[part 2 of 11: package /CANAnalyzer/CommunicationClusters]
AUTOSAR XML (schema 00051)
package /CANAnalyzer/CommunicationClusters  (continued)
  can cluster CAN_FD_IPB_41  (continued)
    can physical channel Channel  (continued)
      frame LocalizationInitFBD_Trunk: id 0x229, frame-length=48, can-addressing-mode=STANDARD, can-frame-rx-behavior=CAN-FD, can-frame-tx-behavior=CAN-FD
        pdu LocalizationInitFBD_Trunk: length=48, unused-bit-pattern=0
          signal LocalizationInitFBD_Trunk_IRKListIndex: start 0, 8 bit, little-endian, data-type-policy=OVERRIDE, base-type=uint8, compu {phys=raw}, range phys 0..252
          signal LocalizationInitFBD_Trunk_ZoneEntry: start 8, 8 bit, little-endian, data-type-policy=OVERRIDE, base-type=uint8, compu {phys=raw}, range phys 0..252
          signal LocalizationInitFBD_Trunk_RangingBlockIndex_0: start 16, 16 bit, little-endian, data-type-policy=OVERRIDE, base-type=uint16, compu {phys=raw}, range phys 0..65532
          signal LocalizationInitFBD_Trunk_TimeOfFlight_0: start 32, 16 bit, little-endian, data-type-policy=OVERRIDE, base-type=uint16, compu {phys=raw*15.65; unit ps}, range phys 0..1000000
          signal LocalizationInitFBD_Trunk_RSSI_0: start 48, 8 bit, little-endian, data-type-policy=OVERRIDE, base-type=uint8, compu {phys=raw-90; unit °}, range phys -90..90
          signal LocalizationInitFBD_Trunk_RangingBlockIndex_1: start 56, 16 bit, little-endian, data-type-policy=OVERRIDE, base-type=uint16, compu {phys=raw}, range phys 0..65532
          signal LocalizationInitFBD_Trunk_TimeOfFlight_1: start 72, 16 bit, little-endian, data-type-policy=OVERRIDE, base-type=uint16, compu {phys=raw*15.65; unit ps}, range phys 0..1000000
          signal LocalizationInitFBD_Trunk_RSSI_1: start 88, 8 bit, little-endian, data-type-policy=OVERRIDE, base-type=uint8, compu {phys=raw-90; unit °}, range phys -90..90
          signal LocalizationInitFBD_Trunk_RangingBlockIndex_2: start 96, 16 bit, little-endian, data-type-policy=OVERRIDE, base-type=uint16, compu {phys=raw}, range phys 0..65532
          signal LocalizationInitFBD_Trunk_TimeOfFlight_2: start 112, 16 bit, little-endian, data-type-policy=OVERRIDE, base-type=uint16, compu {phys=raw*15.65; unit ps}, range phys 0..1000000
          signal LocalizationInitFBD_Trunk_RSSI_2: start 128, 8 bit, little-endian, data-type-policy=OVERRIDE, base-type=uint8, compu {phys=raw-90; unit °}, range phys -90..90
          signal LocalizationInitFBD_Trunk_RangingBlockIndex_3: start 136, 16 bit, little-endian, data-type-policy=OVERRIDE, base-type=uint16, compu {phys=raw}, range phys 0..65532
          signal LocalizationInitFBD_Trunk_TimeOfFlight_3: start 152, 16 bit, little-endian, data-type-policy=OVERRIDE, base-type=uint16, compu {phys=raw*15.65; unit ps}, range phys 0..1000000
          signal LocalizationInitFBD_Trunk_RSSI_3: start 168, 8 bit, little-endian, data-type-policy=OVERRIDE, base-type=uint8, compu {phys=raw-90; unit °}, range phys -90..90
          signal LocalizationInitFBD_Trunk_RangingBlockIndex_4: start 176, 16 bit, little-endian, data-type-policy=OVERRIDE, base-type=uint16, compu {phys=raw}, range phys 0..65532
          signal LocalizationInitFBD_Trunk_TimeOfFlight_4: start 192, 16 bit, little-endian, data-type-policy=OVERRIDE, base-type=uint16, compu {phys=raw*15.65; unit ps}, range phys 0..1000000
          signal LocalizationInitFBD_Trunk_RSSI_4: start 208, 8 bit, little-endian, data-type-policy=OVERRIDE, base-type=uint8, compu {phys=raw-90; unit °}, range phys -90..90
          signal LocalizationInitFBD_Trunk_Sign_00: start 216, 8 bit, little-endian, data-type-policy=OVERRIDE, base-type=uint8, compu {phys=raw}, range phys 0..255
          signal LocalizationInitFBD_Trunk_Sign_01: start 224, 8 bit, little-endian, data-type-policy=OVERRIDE, base-type=uint8, compu {phys=raw}, range phys 0..255
          signal LocalizationInitFBD_Trunk_Sign_02: start 232, 8 bit, little-endian, data-type-policy=OVERRIDE, base-type=uint8, compu {phys=raw}, range phys 0..255
          signal LocalizationInitFBD_Trunk_Sign_03: start 240, 8 bit, little-endian, data-type-policy=OVERRIDE, base-type=uint8, compu {phys=raw}, range phys 0..255
          signal LocalizationInitFBD_Trunk_Sign_04: start 248, 8 bit, little-endian, data-type-policy=OVERRIDE, base-type=uint8, compu {phys=raw}, range phys 0..255
          signal LocalizationInitFBD_Trunk_Sign_05: start 256, 8 bit, little-endian, data-type-policy=OVERRIDE, base-type=uint8, compu {phys=raw}, range phys 0..255
          signal LocalizationInitFBD_Trunk_Sign_06: start 264, 8 bit, little-endian, data-type-policy=OVERRIDE, base-type=uint8, compu {phys=raw}, range phys 0..255
          signal LocalizationInitFBD_Trunk_Sign_07: start 272, 8 bit, little-endian, data-type-policy=OVERRIDE, base-type=uint8, compu {phys=raw}, range phys 0..255
          signal LocalizationInitFBD_Trunk_Sign_08: start 280, 8 bit, little-endian, data-type-policy=OVERRIDE, base-type=uint8, compu {phys=raw}, range phys 0..255
          signal LocalizationInitFBD_Trunk_Sign_09: start 288, 8 bit, little-endian, data-type-policy=OVERRIDE, base-type=uint8, compu {phys=raw}, range phys 0..255
          signal LocalizationInitFBD_Trunk_Sign_10: start 296, 8 bit, little-endian, data-type-policy=OVERRIDE, base-type=uint8, compu {phys=raw}, range phys 0..255
          signal LocalizationInitFBD_Trunk_Sign_11: start 304, 8 bit, little-endian, data-type-policy=OVERRIDE, base-type=uint8, compu {phys=raw}, range phys 0..255
          signal LocalizationInitFBD_Trunk_Sign_12: start 312, 8 bit, little-endian, data-type-policy=OVERRIDE, base-type=uint8, compu {phys=raw}, range phys 0..255
          signal LocalizationInitFBD_Trunk_Sign_13: start 320, 8 bit, little-endian, data-type-policy=OVERRIDE, base-type=uint8, compu {phys=raw}, range phys 0..255
          signal LocalizationInitFBD_Trunk_Sign_14: start 328, 8 bit, little-endian, data-type-policy=OVERRIDE, base-type=uint8, compu {phys=raw}, range phys 0..255
          signal LocalizationInitFBD_Trunk_Sign_15: start 336, 8 bit, little-endian, data-type-policy=OVERRIDE, base-type=uint8, compu {phys=raw}, range phys 0..255
          signal LocalizationInitFBD_Trunk_RangingRoundIndex_0: start 344, 8 bit, little-endian, data-type-policy=OVERRIDE, base-type=uint8, compu {phys=raw}, range phys 0..255
          signal LocalizationInitFBD_Trunk_RangingRoundIndex_1: start 352, 8 bit, little-endian, data-type-policy=OVERRIDE, base-type=uint8, compu {phys=raw}, range phys 0..255
          signal LocalizationInitFBD_Trunk_RangingRoundIndex_2: start 360, 8 bit, little-endian, data-type-policy=OVERRIDE, base-type=uint8, compu {phys=raw}, range phys 0..255
          signal LocalizationInitFBD_Trunk_RangingRoundIndex_3: start 368, 8 bit, little-endian, data-type-policy=OVERRIDE, base-type=uint8, compu {phys=raw}, range phys 0..255
          signal LocalizationInitFBD_Trunk_RangingRoundIndex_4: start 376, 8 bit, little-endian, data-type-policy=OVERRIDE, base-type=uint8, compu {phys=raw}, range phys 0..255
      frame LocalizationInitFBD_VL: id 0x22A, frame-length=48, can-addressing-mode=STANDARD, can-frame-rx-behavior=CAN-FD, can-frame-tx-behavior=CAN-FD
        pdu LocalizationInitFBD_VL: length=48, unused-bit-pattern=0
          signal LocalizationInitFBD_VL_IRKListIndex: start 0, 8 bit, little-endian, data-type-policy=OVERRIDE, base-type=uint8, compu {phys=raw}, range phys 0..252
          signal LocalizationInitFBD_VL_ZoneEntry: start 8, 8 bit, little-endian, data-type-policy=OVERRIDE, base-type=uint8, compu {phys=raw}, range phys 0..252
          signal LocalizationInitFBD_VL_RangingBlockIndex_0: start 16, 16 bit, little-endian, data-type-policy=OVERRIDE, base-type=uint16, compu {phys=raw}, range phys 0..65532
          signal LocalizationInitFBD_VL_TimeOfFlight_0: start 32, 16 bit, little-endian, data-type-policy=OVERRIDE, base-type=uint16, compu {phys=raw*15.65; unit ps}, range phys 0..1000000
          signal LocalizationInitFBD_VL_RSSI_0: start 48, 8 bit, little-endian, data-type-policy=OVERRIDE, base-type=uint8, compu {phys=raw-90; unit °}, range phys -90..90
          signal LocalizationInitFBD_VL_RangingBlockIndex_1: start 56, 16 bit, little-endian, data-type-policy=OVERRIDE, base-type=uint16, compu {phys=raw}, range phys 0..65532
          signal LocalizationInitFBD_VL_TimeOfFlight_1: start 72, 16 bit, little-endian, data-type-policy=OVERRIDE, base-type=uint16, compu {phys=raw*15.65; unit ps}, range phys 0..1000000
          signal LocalizationInitFBD_VL_RSSI_1: start 88, 8 bit, little-endian, data-type-policy=OVERRIDE, base-type=uint8, compu {phys=raw-90; unit °}, range phys -90..90
          signal LocalizationInitFBD_VL_RangingBlockIndex_2: start 96, 16 bit, little-endian, data-type-policy=OVERRIDE, base-type=uint16, compu {phys=raw}, range phys 0..65532
          signal LocalizationInitFBD_VL_TimeOfFlight_2: start 112, 16 bit, little-endian, data-type-policy=OVERRIDE, base-type=uint16, compu {phys=raw*15.65; unit ps}, range phys 0..1000000
          signal LocalizationInitFBD_VL_RSSI_2: start 128, 8 bit, little-endian, data-type-policy=OVERRIDE, base-type=uint8, compu {phys=raw-90; unit °}, range phys -90..90
          signal LocalizationInitFBD_VL_RangingBlockIndex_3: start 136, 16 bit, little-endian, data-type-policy=OVERRIDE, base-type=uint16, compu {phys=raw}, range phys 0..65532
          signal LocalizationInitFBD_VL_TimeOfFlight_3: start 152, 16 bit, little-endian, data-type-policy=OVERRIDE, base-type=uint16, compu {phys=raw*15.65; unit ps}, range phys 0..1000000
          signal LocalizationInitFBD_VL_RSSI_3: start 168, 8 bit, little-endian, data-type-policy=OVERRIDE, base-type=uint8, compu {phys=raw-90; unit °}, range phys -90..90
          signal LocalizationInitFBD_VL_RangingBlockIndex_4: start 176, 16 bit, little-endian, data-type-policy=OVERRIDE, base-type=uint16, compu {phys=raw}, range phys 0..65532
          signal LocalizationInitFBD_VL_TimeOfFlight_4: start 192, 16 bit, little-endian, data-type-policy=OVERRIDE, base-type=uint16, compu {phys=raw*15.65; unit ps}, range phys 0..1000000
          signal LocalizationInitFBD_VL_RSSI_4: start 208, 8 bit, little-endian, data-type-policy=OVERRIDE, base-type=uint8, compu {phys=raw-90; unit °}, range phys -90..90
          signal LocalizationInitFBD_VL_Sign_00: start 216, 8 bit, little-endian, data-type-policy=OVERRIDE, base-type=uint8, compu {phys=raw}, range phys 0..255
          signal LocalizationInitFBD_VL_Sign_01: start 224, 8 bit, little-endian, data-type-policy=OVERRIDE, base-type=uint8, compu {phys=raw}, range phys 0..255
          signal LocalizationInitFBD_VL_Sign_02: start 232, 8 bit, little-endian, data-type-policy=OVERRIDE, base-type=uint8, compu {phys=raw}, range phys 0..255
          signal LocalizationInitFBD_VL_Sign_03: start 240, 8 bit, little-endian, data-type-policy=OVERRIDE, base-type=uint8, compu {phys=raw}, range phys 0..255
          signal LocalizationInitFBD_VL_Sign_04: start 248, 8 bit, little-endian, data-type-policy=OVERRIDE, base-type=uint8, compu {phys=raw}, range phys 0..255
          signal LocalizationInitFBD_VL_Sign_05: start 256, 8 bit, little-endian, data-type-policy=OVERRIDE, base-type=uint8, compu {phys=raw}, range phys 0..255
          signal LocalizationInitFBD_VL_Sign_06: start 264, 8 bit, little-endian, data-type-policy=OVERRIDE, base-type=uint8, compu {phys=raw}, range phys 0..255
          signal LocalizationInitFBD_VL_Sign_07: start 272, 8 bit, little-endian, data-type-policy=OVERRIDE, base-type=uint8, compu {phys=raw}, range phys 0..255
          signal LocalizationInitFBD_VL_Sign_08: start 280, 8 bit, little-endian, data-type-policy=OVERRIDE, base-type=uint8, compu {phys=raw}, range phys 0..255
          signal LocalizationInitFBD_VL_Sign_09: start 288, 8 bit, little-endian, data-type-policy=OVERRIDE, base-type=uint8, compu {phys=raw}, range phys 0..255
          signal LocalizationInitFBD_VL_Sign_10: start 296, 8 bit, little-endian, data-type-policy=OVERRIDE, base-type=uint8, compu {phys=raw}, range phys 0..255
          signal LocalizationInitFBD_VL_Sign_11: start 304, 8 bit, little-endian, data-type-policy=OVERRIDE, base-type=uint8, compu {phys=raw}, range phys 0..255
          signal LocalizationInitFBD_VL_Sign_12: start 312, 8 bit, little-endian, data-type-policy=OVERRIDE, base-type=uint8, compu {phys=raw}, range phys 0..255
          signal LocalizationInitFBD_VL_Sign_13: start 320, 8 bit, little-endian, data-type-policy=OVERRIDE, base-type=uint8, compu {phys=raw}, range phys 0..255
          signal LocalizationInitFBD_VL_Sign_14: start 328, 8 bit, little-endian, data-type-policy=OVERRIDE, base-type=uint8, compu {phys=raw}, range phys 0..255
          signal LocalizationInitFBD_VL_Sign_15: start 336, 8 bit, little-endian, data-type-policy=OVERRIDE, base-type=uint8, compu {phys=raw}, range phys 0..255
          signal LocalizationInitFBD_VL_RangingRoundIndex_0: start 344, 8 bit, little-endian, data-type-policy=OVERRIDE, base-type=uint8, compu {phys=raw}, range phys 0..255
          signal LocalizationInitFBD_VL_RangingRoundIndex_1: start 352, 8 bit, little-endian, data-type-policy=OVERRIDE, base-type=uint8, compu {phys=raw}, range phys 0..255
          signal LocalizationInitFBD_VL_RangingRoundIndex_2: start 360, 8 bit, little-endian, data-type-policy=OVERRIDE, base-type=uint8, compu {phys=raw}, range phys 0..255
          signal LocalizationInitFBD_VL_RangingRoundIndex_3: start 368, 8 bit, little-endian, data-type-policy=OVERRIDE, base-type=uint8, compu {phys=raw}, range phys 0..255
          signal LocalizationInitFBD_VL_RangingRoundIndex_4: start 376, 8 bit, little-endian, data-type-policy=OVERRIDE, base-type=uint8, compu {phys=raw}, range phys 0..255
      frame LocalizationInitFBD_VM: id 0x226, frame-length=48, can-addressing-mode=STANDARD, can-frame-rx-behavior=CAN-FD, can-frame-tx-behavior=CAN-FD
        pdu LocalizationInitFBD_VM: length=48, unused-bit-pattern=0
          signal LocalizationInitFBD_VM_IRKListIndex: start 0, 8 bit, little-endian, data-type-policy=OVERRIDE, base-type=uint8, compu {phys=raw}, range phys 0..252
          signal LocalizationInitFBD_VM_ZoneEntry: start 8, 8 bit, little-endian, data-type-policy=OVERRIDE, base-type=uint8, compu {phys=raw}, range phys 0..252
          signal LocalizationInitFBD_VM_RangingBlockIndex_0: start 16, 16 bit, little-endian, data-type-policy=OVERRIDE, base-type=uint16, compu {phys=raw}, range phys 0..65532
          signal LocalizationInitFBD_VM_TimeOfFlight_0: start 32, 16 bit, little-endian, data-type-policy=OVERRIDE, base-type=uint16, compu {phys=raw*15.65; unit ps}, range phys 0..1000000
          signal LocalizationInitFBD_VM_RSSI_0: start 48, 8 bit, little-endian, data-type-policy=OVERRIDE, base-type=uint8, compu {phys=raw-90; unit °}, range phys -90..90
          signal LocalizationInitFBD_VM_RangingBlockIndex_1: start 56, 16 bit, little-endian, data-type-policy=OVERRIDE, base-type=uint16, compu {phys=raw}, range phys 0..65532
          signal LocalizationInitFBD_VM_TimeOfFlight_1: start 72, 16 bit, little-endian, data-type-policy=OVERRIDE, base-type=uint16, compu {phys=raw*15.65; unit ps}, range phys 0..1000000
          signal LocalizationInitFBD_VM_RSSI_1: start 88, 8 bit, little-endian, data-type-policy=OVERRIDE, base-type=uint8, compu {phys=raw-90; unit °}, range phys -90..90
          signal LocalizationInitFBD_VM_RangingBlockIndex_2: start 96, 16 bit, little-endian, data-type-policy=OVERRIDE, base-type=uint16, compu {phys=raw}, range phys 0..65532
          signal LocalizationInitFBD_VM_TimeOfFlight_2: start 112, 16 bit, little-endian, data-type-policy=OVERRIDE, base-type=uint16, compu {phys=raw*15.65; unit ps}, range phys 0..1000000
          signal LocalizationInitFBD_VM_RSSI_2: start 128, 8 bit, little-endian, data-type-policy=OVERRIDE, base-type=uint8, compu {phys=raw-90; unit °}, range phys -90..90
          signal LocalizationInitFBD_VM_RangingBlockIndex_3: start 136, 16 bit, little-endian, data-type-policy=OVERRIDE, base-type=uint16, compu {phys=raw}, range phys 0..65532
          signal LocalizationInitFBD_VM_TimeOfFlight_3: start 152, 16 bit, little-endian, data-type-policy=OVERRIDE, base-type=uint16, compu {phys=raw*15.65; unit ps}, range phys 0..1000000
          signal LocalizationInitFBD_VM_RSSI_3: start 168, 8 bit, little-endian, data-type-policy=OVERRIDE, base-type=uint8, compu {phys=raw-90; unit °}, range phys -90..90
          signal LocalizationInitFBD_VM_RangingBlockIndex_4: start 176, 16 bit, little-endian, data-type-policy=OVERRIDE, base-type=uint16, compu {phys=raw}, range phys 0..65532
          signal LocalizationInitFBD_VM_TimeOfFlight_4: start 192, 16 bit, little-endian, data-type-policy=OVERRIDE, base-type=uint16, compu {phys=raw*15.65; unit ps}, range phys 0..1000000
          signal LocalizationInitFBD_VM_RSSI_4: start 208, 8 bit, little-endian, data-type-policy=OVERRIDE, base-type=uint8, compu {phys=raw-90; unit °}, range phys -90..90
          signal LocalizationInitFBD_VM_Sign_00: start 216, 8 bit, little-endian, data-type-policy=OVERRIDE, base-type=uint8, compu {phys=raw}, range phys 0..255
          signal LocalizationInitFBD_VM_Sign_01: start 224, 8 bit, little-endian, data-type-policy=OVERRIDE, base-type=uint8, compu {phys=raw}, range phys 0..255
          signal LocalizationInitFBD_VM_Sign_02: start 232, 8 bit, little-endian, data-type-policy=OVERRIDE, base-type=uint8, compu {phys=raw}, range phys 0..255
          signal LocalizationInitFBD_VM_Sign_03: start 240, 8 bit, little-endian, data-type-policy=OVERRIDE, base-type=uint8, compu {phys=raw}, range phys 0..255
          signal LocalizationInitFBD_VM_Sign_04: start 248, 8 bit, little-endian, data-type-policy=OVERRIDE, base-type=uint8, compu {phys=raw}, range phys 0..255
          signal LocalizationInitFBD_VM_Sign_05: start 256, 8 bit, little-endian, data-type-policy=OVERRIDE, base-type=uint8, compu {phys=raw}, range phys 0..255
          signal LocalizationInitFBD_VM_Sign_06: start 264, 8 bit, little-endian, data-type-policy=OVERRIDE, base-type=uint8, compu {phys=raw}, range phys 0..255
          signal LocalizationInitFBD_VM_Sign_07: start 272, 8 bit, little-endian, data-type-policy=OVERRIDE, base-type=uint8, compu {phys=raw}, range phys 0..255
          signal LocalizationInitFBD_VM_Sign_08: start 280, 8 bit, little-endian, data-type-policy=OVERRIDE, base-type=uint8, compu {phys=raw}, range phys 0..255
          signal LocalizationInitFBD_VM_Sign_09: start 288, 8 bit, little-endian, data-type-policy=OVERRIDE, base-type=uint8, compu {phys=raw}, range phys 0..255
          signal LocalizationInitFBD_VM_Sign_10: start 296, 8 bit, little-endian, data-type-policy=OVERRIDE, base-type=uint8, compu {phys=raw}, range phys 0..255
          signal LocalizationInitFBD_VM_Sign_11: start 304, 8 bit, little-endian, data-type-policy=OVERRIDE, base-type=uint8, compu {phys=raw}, range phys 0..255
          signal LocalizationInitFBD_VM_Sign_12: start 312, 8 bit, little-endian, data-type-policy=OVERRIDE, base-type=uint8, compu {phys=raw}, range phys 0..255
          signal LocalizationInitFBD_VM_Sign_13: start 320, 8 bit, little-endian, data-type-policy=OVERRIDE, base-type=uint8, compu {phys=raw}, range phys 0..255
          signal LocalizationInitFBD_VM_Sign_14: start 328, 8 bit, little-endian, data-type-policy=OVERRIDE, base-type=uint8, compu {phys=raw}, range phys 0..255
          signal LocalizationInitFBD_VM_Sign_15: start 336, 8 bit, little-endian, data-type-policy=OVERRIDE, base-type=uint8, compu {phys=raw}, range phys 0..255
          signal LocalizationInitFBD_VM_RangingRoundIndex_0: start 344, 8 bit, little-endian, data-type-policy=OVERRIDE, base-type=uint8, compu {phys=raw}, range phys 0..255
          signal LocalizationInitFBD_VM_RangingRoundIndex_1: start 352, 8 bit, little-endian, data-type-policy=OVERRIDE, base-type=uint8, compu {phys=raw}, range phys 0..255
          signal LocalizationInitFBD_VM_RangingRoundIndex_2: start 360, 8 bit, little-endian, data-type-policy=OVERRIDE, base-type=uint8, compu {phys=raw}, range phys 0..255
          signal LocalizationInitFBD_VM_RangingRoundIndex_3: start 368, 8 bit, little-endian, data-type-policy=OVERRIDE, base-type=uint8, compu {phys=raw}, range phys 0..255
          signal LocalizationInitFBD_VM_RangingRoundIndex_4: start 376, 8 bit, little-endian, data-type-policy=OVERRIDE, base-type=uint8, compu {phys=raw}, range phys 0..255
      frame LocalizationInitFBD_VR: id 0x22B, frame-length=48, can-addressing-mode=STANDARD, can-frame-rx-behavior=CAN-FD, can-frame-tx-behavior=CAN-FD
        pdu LocalizationInitFBD_VR: length=48, unused-bit-pattern=0
          signal LocalizationInitFBD_VR_IRKListIndex: start 0, 8 bit, little-endian, data-type-policy=OVERRIDE, base-type=uint8, compu {phys=raw}, range phys 0..252
          signal LocalizationInitFBD_VR_ZoneEntry: start 8, 8 bit, little-endian, data-type-policy=OVERRIDE, base-type=uint8, compu {phys=raw}, range phys 0..252
          signal LocalizationInitFBD_VR_RangingBlockIndex_0: start 16, 16 bit, little-endian, data-type-policy=OVERRIDE, base-type=uint16, compu {phys=raw}, range phys 0..65532
          signal LocalizationInitFBD_VR_TimeOfFlight_0: start 32, 16 bit, little-endian, data-type-policy=OVERRIDE, base-type=uint16, compu {phys=raw*15.65; unit ps}, range phys 0..1000000
          signal LocalizationInitFBD_VR_RSSI_0: start 48, 8 bit, little-endian, data-type-policy=OVERRIDE, base-type=uint8, compu {phys=raw-90; unit °}, range phys -90..90
          signal LocalizationInitFBD_VR_RangingBlockIndex_1: start 56, 16 bit, little-endian, data-type-policy=OVERRIDE, base-type=uint16, compu {phys=raw}, range phys 0..65532
          signal LocalizationInitFBD_VR_TimeOfFlight_1: start 72, 16 bit, little-endian, data-type-policy=OVERRIDE, base-type=uint16, compu {phys=raw*15.65; unit ps}, range phys 0..1000000
          signal LocalizationInitFBD_VR_RSSI_1: start 88, 8 bit, little-endian, data-type-policy=OVERRIDE, base-type=uint8, compu {phys=raw-90; unit °}, range phys -90..90
          signal LocalizationInitFBD_VR_RangingBlockIndex_2: start 96, 16 bit, little-endian, data-type-policy=OVERRIDE, base-type=uint16, compu {phys=raw}, range phys 0..65532
          signal LocalizationInitFBD_VR_TimeOfFlight_2: start 112, 16 bit, little-endian, data-type-policy=OVERRIDE, base-type=uint16, compu {phys=raw*15.65; unit ps}, range phys 0..1000000
          signal LocalizationInitFBD_VR_RSSI_2: start 128, 8 bit, little-endian, data-type-policy=OVERRIDE, base-type=uint8, compu {phys=raw-90; unit °}, range phys -90..90
          signal LocalizationInitFBD_VR_RangingBlockIndex_3: start 136, 16 bit, little-endian, data-type-policy=OVERRIDE, base-type=uint16, compu {phys=raw}, range phys 0..65532
          signal LocalizationInitFBD_VR_TimeOfFlight_3: start 152, 16 bit, little-endian, data-type-policy=OVERRIDE, base-type=uint16, compu {phys=raw*15.65; unit ps}, range phys 0..1000000
          signal LocalizationInitFBD_VR_RSSI_3: start 168, 8 bit, little-endian, data-type-policy=OVERRIDE, base-type=uint8, compu {phys=raw-90; unit °}, range phys -90..90
          signal LocalizationInitFBD_VR_RangingBlockIndex_4: start 176, 16 bit, little-endian, data-type-policy=OVERRIDE, base-type=uint16, compu {phys=raw}, range phys 0..65532
          signal LocalizationInitFBD_VR_TimeOfFlight_4: start 192, 16 bit, little-endian, data-type-policy=OVERRIDE, base-type=uint16, compu {phys=raw*15.65; unit ps}, range phys 0..1000000
          signal LocalizationInitFBD_VR_RSSI_4: start 208, 8 bit, little-endian, data-type-policy=OVERRIDE, base-type=uint8, compu {phys=raw-90; unit °}, range phys -90..90
          signal LocalizationInitFBD_VR_Sign_00: start 216, 8 bit, little-endian, data-type-policy=OVERRIDE, base-type=uint8, compu {phys=raw}, range phys 0..255
          signal LocalizationInitFBD_VR_Sign_01: start 224, 8 bit, little-endian, data-type-policy=OVERRIDE, base-type=uint8, compu {phys=raw}, range phys 0..255
          signal LocalizationInitFBD_VR_Sign_02: start 232, 8 bit, little-endian, data-type-policy=OVERRIDE, base-type=uint8, compu {phys=raw}, range phys 0..255
          signal LocalizationInitFBD_VR_Sign_03: start 240, 8 bit, little-endian, data-type-policy=OVERRIDE, base-type=uint8, compu {phys=raw}, range phys 0..255
          signal LocalizationInitFBD_VR_Sign_04: start 248, 8 bit, little-endian, data-type-policy=OVERRIDE, base-type=uint8, compu {phys=raw}, range phys 0..255
          signal LocalizationInitFBD_VR_Sign_05: start 256, 8 bit, little-endian, data-type-policy=OVERRIDE, base-type=uint8, compu {phys=raw}, range phys 0..255
          signal LocalizationInitFBD_VR_Sign_06: start 264, 8 bit, little-endian, data-type-policy=OVERRIDE, base-type=uint8, compu {phys=raw}, range phys 0..255
          signal LocalizationInitFBD_VR_Sign_07: start 272, 8 bit, little-endian, data-type-policy=OVERRIDE, base-type=uint8, compu {phys=raw}, range phys 0..255
          signal LocalizationInitFBD_VR_Sign_08: start 280, 8 bit, little-endian, data-type-policy=OVERRIDE, base-type=uint8, compu {phys=raw}, range phys 0..255
          signal LocalizationInitFBD_VR_Sign_09: start 288, 8 bit, little-endian, data-type-policy=OVERRIDE, base-type=uint8, compu {phys=raw}, range phys 0..255
          signal LocalizationInitFBD_VR_Sign_10: start 296, 8 bit, little-endian, data-type-policy=OVERRIDE, base-type=uint8, compu {phys=raw}, range phys 0..255
          signal LocalizationInitFBD_VR_Sign_11: start 304, 8 bit, little-endian, data-type-policy=OVERRIDE, base-type=uint8, compu {phys=raw}, range phys 0..255
          signal LocalizationInitFBD_VR_Sign_12: start 312, 8 bit, little-endian, data-type-policy=OVERRIDE, base-type=uint8, compu {phys=raw}, range phys 0..255
          signal LocalizationInitFBD_VR_Sign_13: start 320, 8 bit, little-endian, data-type-policy=OVERRIDE, base-type=uint8, compu {phys=raw}, range phys 0..255
          signal LocalizationInitFBD_VR_Sign_14: start 328, 8 bit, little-endian, data-type-policy=OVERRIDE, base-type=uint8, compu {phys=raw}, range phys 0..255
          signal LocalizationInitFBD_VR_Sign_15: start 336, 8 bit, little-endian, data-type-policy=OVERRIDE, base-type=uint8, compu {phys=raw}, range phys 0..255
          signal LocalizationInitFBD_VR_RangingRoundIndex_0: start 344, 8 bit, little-endian, data-type-policy=OVERRIDE, base-type=uint8, compu {phys=raw}, range phys 0..255
          signal LocalizationInitFBD_VR_RangingRoundIndex_1: start 352, 8 bit, little-endian, data-type-policy=OVERRIDE, base-type=uint8, compu {phys=raw}, range phys 0..255
          signal LocalizationInitFBD_VR_RangingRoundIndex_2: start 360, 8 bit, little-endian, data-type-policy=OVERRIDE, base-type=uint8, compu {phys=raw}, range phys 0..255
          signal LocalizationInitFBD_VR_RangingRoundIndex_3: start 368, 8 bit, little-endian, data-type-policy=OVERRIDE, base-type=uint8, compu {phys=raw}, range phys 0..255
          signal LocalizationInitFBD_VR_RangingRoundIndex_4: start 376, 8 bit, little-endian, data-type-policy=OVERRIDE, base-type=uint8, compu {phys=raw}, range phys 0..255
      frame LocalizationInitRequest: id 0x196, frame-length=20, can-addressing-mode=STANDARD, can-frame-rx-behavior=CAN-FD, can-frame-tx-behavior=CAN-FD
        pdu LocalizationInitRequest: length=20, unused-bit-pattern=0
          signal LocalizationInitRequest_Address: start 0, 16 bit, little-endian, data-type-policy=OVERRIDE, compu {phys=raw}
          signal LocalizationInitRequest_SessionIDShort: start 16, 8 bit, little-endian, data-type-policy=OVERRIDE, base-type=uint8, compu {phys=raw}, range phys 0..252
          signal LocalizationInitRequest_IRKListIndex: start 24, 8 bit, little-endian, data-type-policy=OVERRIDE, base-type=uint8, compu {phys=raw}, range phys 0..252
          signal LocalizationInitRequest_Auth00: start 32, 8 bit, little-endian, data-type-policy=OVERRIDE, base-type=uint8, compu {phys=raw}, range phys 0..255
          signal LocalizationInitRequest_Auth01: start 40, 8 bit, little-endian, data-type-policy=OVERRIDE, base-type=uint8, compu {phys=raw}, range phys 0..255
          signal LocalizationInitRequest_Auth02: start 48, 8 bit, little-endian, data-type-policy=OVERRIDE, base-type=uint8, compu {phys=raw}, range phys 0..255
          signal LocalizationInitRequest_Auth03: start 56, 8 bit, little-endian, data-type-policy=OVERRIDE, base-type=uint8, compu {phys=raw}, range phys 0..255
          signal LocalizationInitRequest_Auth04: start 64, 8 bit, little-endian, data-type-policy=OVERRIDE, base-type=uint8, compu {phys=raw}, range phys 0..255
          signal LocalizationInitRequest_Auth05: start 72, 8 bit, little-endian, data-type-policy=OVERRIDE, base-type=uint8, compu {phys=raw}, range phys 0..255
          signal LocalizationInitRequest_Auth06: start 80, 8 bit, little-endian, data-type-policy=OVERRIDE, base-type=uint8, compu {phys=raw}, range phys 0..255
          signal LocalizationInitRequest_Auth07: start 88, 8 bit, little-endian, data-type-policy=OVERRIDE, base-type=uint8, compu {phys=raw}, range phys 0..255
          signal LocalizationInitRequest_Auth08: start 96, 8 bit, little-endian, data-type-policy=OVERRIDE, base-type=uint8, compu {phys=raw}, range phys 0..255
          signal LocalizationInitRequest_Auth09: start 104, 8 bit, little-endian, data-type-policy=OVERRIDE, base-type=uint8, compu {phys=raw}, range phys 0..255
          signal LocalizationInitRequest_Auth10: start 112, 8 bit, little-endian, data-type-policy=OVERRIDE, base-type=uint8, compu {phys=raw}, range phys 0..255
          signal LocalizationInitRequest_Auth11: start 120, 8 bit, little-endian, data-type-policy=OVERRIDE, base-type=uint8, compu {phys=raw}, range phys 0..255
          signal LocalizationInitRequest_Auth12: start 128, 8 bit, little-endian, data-type-policy=OVERRIDE, base-type=uint8, compu {phys=raw}, range phys 0..255
          signal LocalizationInitRequest_Auth13: start 136, 8 bit, little-endian, data-type-policy=OVERRIDE, base-type=uint8, compu {phys=raw}, range phys 0..255
          signal LocalizationInitRequest_Auth14: start 144, 8 bit, little-endian, data-type-policy=OVERRIDE, base-type=uint8, compu {phys=raw}, range phys 0..255
          signal LocalizationInitRequest_Auth15: start 152, 8 bit, little-endian, data-type-policy=OVERRIDE, base-type=uint8, compu {phys=raw}, range phys 0..255
      frame LocalizationResult_IPB: id 0x3E7, frame-length=32, can-addressing-mode=STANDARD, can-frame-rx-behavior=CAN-FD, can-frame-tx-behavior=CAN-FD
        pdu LocalizationResult_IPB: length=32, unused-bit-pattern=0
          signal LocalizationResult_IPB_Byte00: start 0, 8 bit, little-endian, data-type-policy=OVERRIDE, base-type=uint8, compu {phys=raw}, range phys 0..252
          signal LocalizationResult_IPB_Byte01: start 8, 8 bit, little-endian, data-type-policy=OVERRIDE, base-type=uint8, compu {phys=raw}, range phys 0..252
          signal LocalizationResult_IPB_Byte02: start 16, 8 bit, little-endian, data-type-policy=OVERRIDE, base-type=uint8, compu {phys=raw}, range phys 0..252
          signal LocalizationResult_IPB_Byte03: start 24, 8 bit, little-endian, data-type-policy=OVERRIDE, base-type=uint8, compu {phys=raw}, range phys 0..252
          signal LocalizationResult_IPB_Byte04: start 32, 8 bit, little-endian, data-type-policy=OVERRIDE, base-type=uint8, compu {phys=raw}, range phys 0..252
          signal LocalizationResult_IPB_Byte05: start 40, 8 bit, little-endian, data-type-policy=OVERRIDE, base-type=uint8, compu {phys=raw}, range phys 0..252
          signal LocalizationResult_IPB_Byte06: start 48, 8 bit, little-endian, data-type-policy=OVERRIDE, base-type=uint8, compu {phys=raw}, range phys 0..252
          signal LocalizationResult_IPB_Byte07: start 56, 8 bit, little-endian, data-type-policy=OVERRIDE, base-type=uint8, compu {phys=raw}, range phys 0..252
          signal LocalizationResult_IPB_Byte08: start 64, 8 bit, little-endian, data-type-policy=OVERRIDE, base-type=uint8, compu {phys=raw}, range phys 0..252
          signal LocalizationResult_IPB_Byte09: start 72, 8 bit, little-endian, data-type-policy=OVERRIDE, base-type=uint8, compu {phys=raw}, range phys 0..252
          signal LocalizationResult_IPB_Byte10: start 80, 8 bit, little-endian, data-type-policy=OVERRIDE, base-type=uint8, compu {phys=raw}, range phys 0..252
          signal LocalizationResult_IPB_Byte11: start 88, 8 bit, little-endian, data-type-policy=OVERRIDE, base-type=uint8, compu {phys=raw}, range phys 0..252
          signal LocalizationResult_IPB_Byte12: start 96, 8 bit, little-endian, data-type-policy=OVERRIDE, base-type=uint8, compu {phys=raw}, range phys 0..252
          signal LocalizationResult_IPB_Byte13: start 104, 8 bit, little-endian, data-type-policy=OVERRIDE, base-type=uint8, compu {phys=raw}, range phys 0..252
          signal LocalizationResult_IPB_Byte14: start 112, 8 bit, little-endian, data-type-policy=OVERRIDE, base-type=uint8, compu {phys=raw}, range phys 0..252
          signal LocalizationResult_IPB_Byte15: start 120, 8 bit, little-endian, data-type-policy=OVERRIDE, base-type=uint8, compu {phys=raw}, range phys 0..252
          signal LocalizationResult_IPB_Byte16: start 128, 8 bit, little-endian, data-type-policy=OVERRIDE, base-type=uint8, compu {phys=raw}, range phys 0..252
          signal LocalizationResult_IPB_Byte17: start 136, 8 bit, little-endian, data-type-policy=OVERRIDE, base-type=uint8, compu {phys=raw}, range phys 0..252
          signal LocalizationResult_IPB_Byte18: start 144, 8 bit, little-endian, data-type-policy=OVERRIDE, base-type=uint8, compu {phys=raw}, range phys 0..252
          signal LocalizationResult_IPB_Byte19: start 152, 8 bit, little-endian, data-type-policy=OVERRIDE, base-type=uint8, compu {phys=raw}, range phys 0..252
          signal LocalizationResult_IPB_Byte20: start 160, 8 bit, little-endian, data-type-policy=OVERRIDE, base-type=uint8, compu {phys=raw}, range phys 0..252
          signal LocalizationResult_IPB_Byte21: start 168, 8 bit, little-endian, data-type-policy=OVERRIDE, base-type=uint8, compu {phys=raw}, range phys 0..252
          signal LocalizationResult_IPB_Byte22: start 176, 8 bit, little-endian, data-type-policy=OVERRIDE, base-type=uint8, compu {phys=raw}, range phys 0..252
          signal LocalizationResult_IPB_Byte23: start 184, 8 bit, little-endian, data-type-policy=OVERRIDE, base-type=uint8, compu {phys=raw}, range phys 0..252
          signal LocalizationResult_IPB_Byte24: start 192, 8 bit, little-endian, data-type-policy=OVERRIDE, base-type=uint8, compu {phys=raw}, range phys 0..252
          signal LocalizationResult_IPB_Byte25: start 200, 8 bit, little-endian, data-type-policy=OVERRIDE, base-type=uint8, compu {phys=raw}, range phys 0..252
          signal LocalizationResult_IPB_Byte26: start 208, 8 bit, little-endian, data-type-policy=OVERRIDE, base-type=uint8, compu {phys=raw}, range phys 0..252
          signal LocalizationResult_IPB_Byte27: start 216, 8 bit, little-endian, data-type-policy=OVERRIDE, base-type=uint8, compu {phys=raw}, range phys 0..252
          signal LocalizationResult_IPB_Byte28: start 224, 8 bit, little-endian, data-type-policy=OVERRIDE, base-type=uint8, compu {phys=raw}, range phys 0..252
          signal LocalizationResult_IPB_Byte29: start 232, 8 bit, little-endian, data-type-policy=OVERRIDE, base-type=uint8, compu {phys=raw}, range phys 0..252
          signal LocalizationResult_IPB_Byte30: start 240, 8 bit, little-endian, data-type-policy=OVERRIDE, base-type=uint8, compu {phys=raw}, range phys 0..252
          signal LocalizationResult_IPB_Byte31: start 248, 8 bit, little-endian, data-type-policy=OVERRIDE, base-type=uint8, compu {phys=raw}, range phys 0..252
      frame MyWayTracking_IPB: id 0x3E6, frame-length=32, can-addressing-mode=STANDARD, can-frame-rx-behavior=CAN-FD, can-frame-tx-behavior=CAN-FD
        pdu MyWayTracking_IPB: length=32, unused-bit-pattern=0
          signal MyWayTracking_IPB_SessionIDShort: start 0, 8 bit, little-endian, data-type-policy=OVERRIDE, base-type=uint8, compu {phys=raw}, range phys 0..252
          signal MyWayTracking_IPB_IRKListIndex: start 8, 8 bit, little-endian, data-type-policy=OVERRIDE, base-type=uint8, compu {phys=raw}, range phys 0..252
          signal MyWayTracking_IPB_TrackingStatus: start 16, 8 bit, little-endian, data-type-policy=OVERRIDE, base-type=uint8, compu {phys=raw}, range phys 0..252
          signal MyWayTracking_IPB_ClassificationConfidence: start 24, 8 bit, little-endian, data-type-policy=OVERRIDE, base-type=uint8, compu {phys=raw}, range phys 0..252
          signal MyWayTracking_IPB_Intent: start 32, 8 bit, little-endian, data-type-policy=OVERRIDE, base-type=uint8, compu {phys=raw}, range phys 0..252
          signal MyWayTracking_IPB_TimeRemaining: start 40, 8 bit, little-endian, data-type-policy=OVERRIDE, base-type=uint8, compu {phys=raw}, range phys 0..252
          signal MyWayTracking_IPB_Target: start 48, 8 bit, little-endian, data-type-policy=OVERRIDE, base-type=uint8, compu {phys=raw}, range phys 0..252
          signal MyWayTracking_IPB_Parameter00: start 56, 8 bit, little-endian, data-type-policy=OVERRIDE, base-type=uint8, compu {phys=raw}, range phys 0..252
          signal MyWayTracking_IPB_Parameter01: start 64, 8 bit, little-endian, data-type-policy=OVERRIDE, base-type=uint8, compu {phys=raw}, range phys 0..252
          signal MyWayTracking_IPB_Parameter02: start 72, 8 bit, little-endian, data-type-policy=OVERRIDE, base-type=uint8, compu {phys=raw}, range phys 0..252
          signal MyWayTracking_IPB_Parameter03: start 80, 8 bit, little-endian, data-type-policy=OVERRIDE, base-type=uint8, compu {phys=raw}, range phys 0..252
          signal MyWayTracking_IPB_Parameter04: start 88, 8 bit, little-endian, data-type-policy=OVERRIDE, base-type=uint8, compu {phys=raw}, range phys 0..252
          signal MyWayTracking_IPB_Parameter05: start 96, 8 bit, little-endian, data-type-policy=OVERRIDE, base-type=uint8, compu {phys=raw}, range phys 0..252
          signal MyWayTracking_IPB_Parameter06: start 104, 8 bit, little-endian, data-type-policy=OVERRIDE, base-type=uint8, compu {phys=raw}, range phys 0..252
          signal MyWayTracking_IPB_Parameter07: start 112, 8 bit, little-endian, data-type-policy=OVERRIDE, base-type=uint8, compu {phys=raw}, range phys 0..252
          signal MyWayTracking_IPB_Parameter08: start 120, 8 bit, little-endian, data-type-policy=OVERRIDE, base-type=uint8, compu {phys=raw}, range phys 0..252
          signal MyWayTracking_IPB_Parameter09: start 128, 8 bit, little-endian, data-type-policy=OVERRIDE, base-type=uint8, compu {phys=raw}, range phys 0..252
          signal MyWayTracking_IPB_Parameter10: start 136, 8 bit, little-endian, data-type-policy=OVERRIDE, base-type=uint8, compu {phys=raw}, range phys 0..252
          signal MyWayTracking_IPB_Parameter11: start 144, 8 bit, little-endian, data-type-policy=OVERRIDE, base-type=uint8, compu {phys=raw}, range phys 0..252
          signal MyWayTracking_IPB_Parameter12: start 152, 8 bit, little-endian, data-type-policy=OVERRIDE, base-type=uint8, compu {phys=raw}, range phys 0..252
          signal MyWayTracking_IPB_Parameter13: start 160, 8 bit, little-endian, data-type-policy=OVERRIDE, base-type=uint8, compu {phys=raw}, range phys 0..252
          signal MyWayTracking_IPB_Parameter14: start 168, 8 bit, little-endian, data-type-policy=OVERRIDE, base-type=uint8, compu {phys=raw}, range phys 0..252
          signal MyWayTracking_IPB_Parameter15: start 176, 8 bit, little-endian, data-type-policy=OVERRIDE, base-type=uint8, compu {phys=raw}, range phys 0..252
          signal MyWayTracking_IPB_Parameter16: start 184, 8 bit, little-endian, data-type-policy=OVERRIDE, base-type=uint8, compu {phys=raw}, range phys 0..252
          signal MyWayTracking_IPB_Parameter17: start 192, 8 bit, little-endian, data-type-policy=OVERRIDE, base-type=uint8, compu {phys=raw}, range phys 0..252
          signal MyWayTracking_IPB_Parameter18: start 200, 8 bit, little-endian, data-type-policy=OVERRIDE, base-type=uint8, compu {phys=raw}, range phys 0..252
          signal MyWayTracking_IPB_Parameter19: start 208, 8 bit, little-endian, data-type-policy=OVERRIDE, base-type=uint8, compu {phys=raw}, range phys 0..252
          signal MyWayTracking_IPB_Parameter20: start 216, 8 bit, little-endian, data-type-policy=OVERRIDE, base-type=uint8, compu {phys=raw}, range phys 0..252
          signal MyWayTracking_IPB_Parameter21: start 224, 8 bit, little-endian, data-type-policy=OVERRIDE, base-type=uint8, compu {phys=raw}, range phys 0..252
          signal MyWayTracking_IPB_Parameter22: start 232, 8 bit, little-endian, data-type-policy=OVERRIDE, base-type=uint8, compu {phys=raw}, range phys 0..252
          signal MyWayTracking_IPB_Parameter23: start 240, 8 bit, little-endian, data-type-policy=OVERRIDE, base-type=uint8, compu {phys=raw}, range phys 0..252
          signal MyWayTracking_IPB_Parameter24: start 248, 8 bit, little-endian, data-type-policy=OVERRIDE, base-type=uint8, compu {phys=raw}, range phys 0..252
      frame RequestBindingStatusFBD: id 0x25E, frame-length=8, can-addressing-mode=STANDARD, can-frame-rx-behavior=CAN-20, can-frame-tx-behavior=CAN-20
        pdu RequestBindingStatusFBD: length=8, unused-bit-pattern=0
          signal RequestBindingStatusFBD_Address: start 0, 16 bit, little-endian, data-type-policy=OVERRIDE, compu {phys=raw}
          signal RequestBindingStatusFBD_RequestStatus: start 16, 8 bit, little-endian, data-type-policy=OVERRIDE, base-type=uint8, compu {phys=raw}, range phys 0..252
      frame RequestBLECSSession: id 0x180, frame-length=48, can-addressing-mode=STANDARD, can-frame-rx-behavior=CAN-FD, can-frame-tx-behavior=CAN-FD
        pdu RequestBLECSSession: length=48, unused-bit-pattern=0
          signal RequestBLECSSession_Address: start 0, 16 bit, little-endian, data-type-policy=OVERRIDE, compu {phys=raw}
          signal RequestBLECSSession_ID: start 16, 8 bit, little-endian, data-type-policy=OVERRIDE, base-type=uint8, compu {phys=raw}, range phys 0..252
          signal RequestBLECSSession_IRKListID: start 24, 8 bit, little-endian, data-type-policy=OVERRIDE, base-type=uint8, compu {phys=raw}, range phys 0..252
          signal RequestBLECSSession_DeviceGroup: start 32, 8 bit, little-endian, data-type-policy=OVERRIDE, base-type=uint8, compu {phys=raw}, range phys 0..252
          signal RequestBLECSSession_MainModeType: start 40, 8 bit, little-endian, data-type-policy=OVERRIDE, compu {phys=raw}
          signal RequestBLECSSession_SubModeType: start 48, 8 bit, little-endian, data-type-policy=OVERRIDE, compu {phys=raw}
          signal RequestBLECSSession_MainModeRepetition: start 56, 8 bit, little-endian, data-type-policy=OVERRIDE, base-type=uint8, compu {phys=raw}, range phys 0..252
          signal RequestBLECSSession_Mode0Steps: start 64, 8 bit, little-endian, data-type-policy=OVERRIDE, base-type=uint8, compu {phys=raw}, range phys 0..252
          signal RequestBLECSSession_RTTType: start 72, 8 bit, little-endian, data-type-policy=OVERRIDE, compu {phys=raw}
          signal RequestBLECSSession_CSSyncPHY: start 80, 8 bit, little-endian, data-type-policy=OVERRIDE, compu {phys=raw}
          signal RequestBLECSSession_ChannelMap00_59: start 88, 64 bit, little-endian, data-type-policy=OVERRIDE, compu {phys=raw}
          signal RequestBLECSSession_ChannelMap60_79: start 152, 24 bit, little-endian, data-type-policy=OVERRIDE, compu {phys=raw}
          signal RequestBLECSSession_MaxProcedureLen: start 176, 16 bit, little-endian, data-type-policy=OVERRIDE, base-type=uint16, compu {phys=raw*0.625; unit ms}, range phys 0..40900
          signal RequestBLECSSession_MinProcedureIntervals: start 192, 16 bit, little-endian, data-type-policy=OVERRIDE, base-type=uint16, compu {phys=raw*0.625; unit ms}, range phys 0..40900
          signal RequestBLECSSession_MaxProcedureIntervals: start 208, 16 bit, little-endian, data-type-policy=OVERRIDE, base-type=uint16, compu {phys=raw*0.625; unit ms}, range phys 0..40900
          signal RequestBLECSSession_MaxProcedureCount: start 224, 16 bit, little-endian, data-type-policy=OVERRIDE, base-type=uint16, compu {phys=raw}, range phys 0..65532
          signal RequestBLECSSession_ToneAntennaConfigSelection: start 240, 8 bit, little-endian, data-type-policy=OVERRIDE, compu {phys=raw}
          signal RequestBLECSSession_BusCycleTime: start 248, 16 bit, little-endian, data-type-policy=OVERRIDE, base-type=uint16, compu {phys=raw; unit ms}, range phys 0..65532
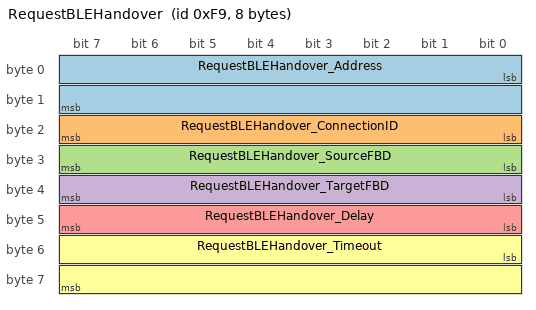
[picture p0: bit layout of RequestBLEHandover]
      frame RequestBLEHandover: id 0xF9, frame-length=8, can-addressing-mode=STANDARD, can-frame-rx-behavior=CAN-20, can-frame-tx-behavior=CAN-20
        pdu RequestBLEHandover: length=8, unused-bit-pattern=0
          signal RequestBLEHandover_Address: start 0, 16 bit, little-endian, data-type-policy=OVERRIDE, compu {phys=raw}
          signal RequestBLEHandover_ConnectionID: start 16, 8 bit, little-endian, data-type-policy=OVERRIDE, base-type=uint8, compu {phys=raw}, range phys 0..252
          signal RequestBLEHandover_SourceFBD: start 24, 8 bit, little-endian, data-type-policy=OVERRIDE, compu {phys=raw}
          signal RequestBLEHandover_TargetFBD: start 32, 8 bit, little-endian, data-type-policy=OVERRIDE, compu {phys=raw}
          signal RequestBLEHandover_Delay: start 40, 8 bit, little-endian, data-type-policy=OVERRIDE, base-type=uint8, compu {phys=raw; unit ms}, range phys 0..252
          signal RequestBLEHandover_Timeout: start 48, 16 bit, little-endian, data-type-policy=OVERRIDE, base-type=uint16, compu {phys=raw; unit ms}, range phys 0..65532
      frame RequestBLESettings: id 0xCB, frame-length=8, can-addressing-mode=STANDARD, can-frame-rx-behavior=CAN-20, can-frame-tx-behavior=CAN-20
        pdu RequestBLESettings: length=8, unused-bit-pattern=0
          signal RequestBLESettings_Address: start 0, 16 bit, little-endian, data-type-policy=OVERRIDE, compu {phys=raw}
          signal RequestBLESettings_RequestSettings: start 16, 8 bit, little-endian, data-type-policy=OVERRIDE, base-type=uint8, compu {phys=raw}, range phys 0..252
      frame RequestConfigurationStatusFBD: id 0x259, frame-length=8, can-addressing-mode=STANDARD, can-frame-rx-behavior=CAN-20, can-frame-tx-behavior=CAN-20
        pdu RequestConfigurationStatusFBD: length=8, unused-bit-pattern=0
          signal RequestConfigurationStatusFBD_Address: start 0, 16 bit, little-endian, data-type-policy=OVERRIDE, compu {phys=raw}
          signal RequestConfigurationStatusFBD_RequestConfiguration: start 16, 8 bit, little-endian, data-type-policy=OVERRIDE, base-type=uint8, compu {phys=raw}, range phys 0..252
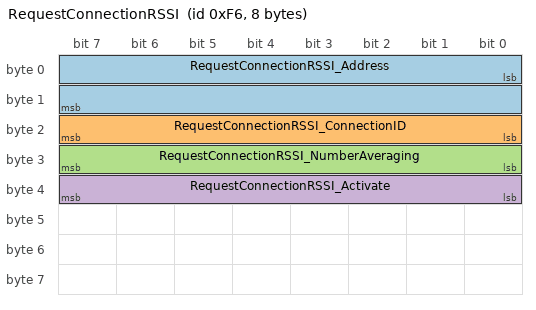
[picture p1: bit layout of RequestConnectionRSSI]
      frame RequestConnectionRSSI: id 0xF6, frame-length=8, can-addressing-mode=STANDARD, can-frame-rx-behavior=CAN-20, can-frame-tx-behavior=CAN-20
        pdu RequestConnectionRSSI: length=8, unused-bit-pattern=0
          signal RequestConnectionRSSI_Address: start 0, 16 bit, little-endian, data-type-policy=OVERRIDE, compu {phys=raw}
          signal RequestConnectionRSSI_ConnectionID: start 16, 8 bit, little-endian, data-type-policy=OVERRIDE, base-type=uint8, compu {phys=raw}, range phys 0..252
          signal RequestConnectionRSSI_NumberAveraging: start 24, 8 bit, little-endian, data-type-policy=OVERRIDE, base-type=uint8, compu {phys=raw}, range phys 0..252
          signal RequestConnectionRSSI_Activate: start 32, 8 bit, little-endian, data-type-policy=OVERRIDE, compu {phys=raw}
      frame RequestCoordinates: id 0x25A, frame-length=8, can-addressing-mode=STANDARD, can-frame-rx-behavior=CAN-20, can-frame-tx-behavior=CAN-20
        pdu RequestCoordinates: length=8, unused-bit-pattern=0
          signal RequestCoordinates_Address: start 0, 16 bit, little-endian, data-type-policy=OVERRIDE, compu {phys=raw}
          signal RequestCoordinates_RequestData: start 16, 8 bit, little-endian, data-type-policy=OVERRIDE, base-type=uint8, compu {phys=raw}, range phys 0..252
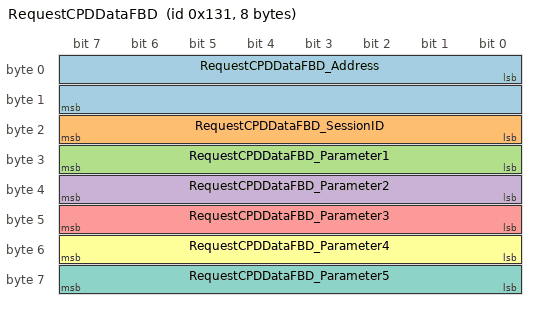
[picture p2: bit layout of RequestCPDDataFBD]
      frame RequestCPDDataFBD: id 0x131, frame-length=8, can-addressing-mode=STANDARD, can-frame-rx-behavior=CAN-20, can-frame-tx-behavior=CAN-20
        pdu RequestCPDDataFBD: length=8, unused-bit-pattern=0
          signal RequestCPDDataFBD_Address: start 0, 16 bit, little-endian, data-type-policy=OVERRIDE, compu {phys=raw}
          signal RequestCPDDataFBD_SessionID: start 16, 8 bit, little-endian, data-type-policy=OVERRIDE, base-type=uint8, compu {phys=raw}, range phys 0..252
          signal RequestCPDDataFBD_Parameter1: start 24, 8 bit, little-endian, data-type-policy=OVERRIDE, base-type=uint8, compu {phys=raw}, range phys 0..252
          signal RequestCPDDataFBD_Parameter2: start 32, 8 bit, little-endian, data-type-policy=OVERRIDE, base-type=uint8, compu {phys=raw}, range phys 0..252
          signal RequestCPDDataFBD_Parameter3: start 40, 8 bit, little-endian, data-type-policy=OVERRIDE, base-type=uint8, compu {phys=raw}, range phys 0..252
          signal RequestCPDDataFBD_Parameter4: start 48, 8 bit, little-endian, data-type-policy=OVERRIDE, base-type=uint8, compu {phys=raw}, range phys 0..252
          signal RequestCPDDataFBD_Parameter5: start 56, 8 bit, little-endian, data-type-policy=OVERRIDE, base-type=uint8, compu {phys=raw}, range phys 0..252
      frame RequestRangingSessionSign: id 0x195, frame-length=12, can-addressing-mode=STANDARD, can-frame-rx-behavior=CAN-FD, can-frame-tx-behavior=CAN-FD
        pdu RequestRangingSessionSign: length=12, unused-bit-pattern=0
          signal RequestRangingSessionSign_Address: start 0, 16 bit, little-endian, data-type-policy=OVERRIDE, compu {phys=raw}
          signal RequestRangingSessionSign_Function: start 16, 8 bit, little-endian, data-type-policy=OVERRIDE, base-type=uint8, compu {phys=raw}, range phys 0..252
          signal RequestRangingSessionSign_IRKListID: start 24, 8 bit, little-endian, data-type-policy=OVERRIDE, base-type=uint8, compu {phys=raw}, range phys 0..252
          signal RequestRangingSessionSign_STSIndex: start 32, 32 bit, little-endian, data-type-policy=OVERRIDE, base-type=uint32, compu {phys=raw}, range phys 0..4294967292
          signal RequestRangingSessionSign_Nonce: start 64, 32 bit, little-endian, data-type-policy=OVERRIDE, base-type=uint32, compu {phys=raw}, range phys 0..4294967294
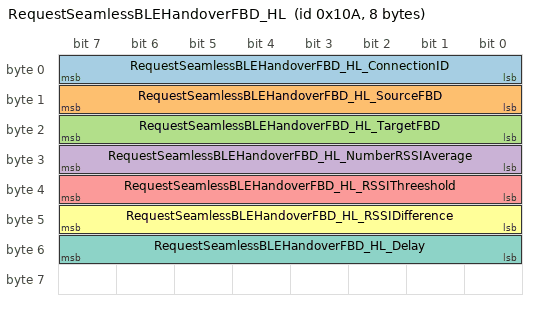
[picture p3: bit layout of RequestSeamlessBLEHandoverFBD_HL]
      frame RequestSeamlessBLEHandoverFBD_HL: id 0x10A, frame-length=8, can-addressing-mode=STANDARD, can-frame-rx-behavior=CAN-20, can-frame-tx-behavior=CAN-20
        pdu RequestSeamlessBLEHandoverFBD_HL: length=8, unused-bit-pattern=0
          signal RequestSeamlessBLEHandoverFBD_HL_ConnectionID: start 0, 8 bit, little-endian, data-type-policy=OVERRIDE, base-type=uint8, compu {phys=raw}, range phys 0..252
          signal RequestSeamlessBLEHandoverFBD_HL_SourceFBD: start 8, 8 bit, little-endian, data-type-policy=OVERRIDE, compu {phys=raw}
          signal RequestSeamlessBLEHandoverFBD_HL_TargetFBD: start 16, 8 bit, little-endian, data-type-policy=OVERRIDE, compu {phys=raw}
          signal RequestSeamlessBLEHandoverFBD_HL_NumberRSSIAverage: start 24, 8 bit, little-endian, data-type-policy=OVERRIDE, base-type=uint8, compu {phys=raw}, range phys 0..252
          signal RequestSeamlessBLEHandoverFBD_HL_RSSIThreeshold: start 32, 8 bit, little-endian, data-type-policy=OVERRIDE, base-type=uint8, compu {phys=raw*0.5-127; unit dB}, range phys -127..-1
          signal RequestSeamlessBLEHandoverFBD_HL_RSSIDifference: start 40, 8 bit, little-endian, data-type-policy=OVERRIDE, base-type=uint8, compu {phys=raw*0.5; unit dB}, range phys 0..126
          signal RequestSeamlessBLEHandoverFBD_HL_Delay: start 48, 8 bit, little-endian, data-type-policy=OVERRIDE, base-type=uint8, compu {phys=raw; unit ms}, range phys 0..252
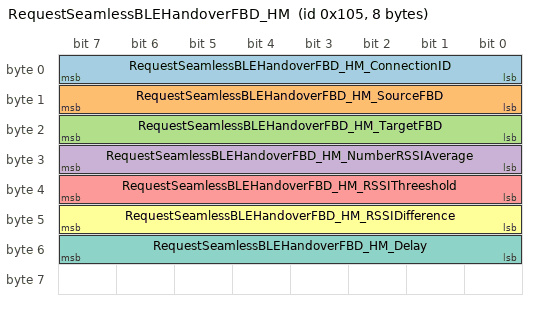
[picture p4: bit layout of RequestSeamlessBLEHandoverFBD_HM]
      frame RequestSeamlessBLEHandoverFBD_HM: id 0x105, frame-length=8, can-addressing-mode=STANDARD, can-frame-rx-behavior=CAN-20, can-frame-tx-behavior=CAN-20
        pdu RequestSeamlessBLEHandoverFBD_HM: length=8, unused-bit-pattern=0
          signal RequestSeamlessBLEHandoverFBD_HM_ConnectionID: start 0, 8 bit, little-endian, data-type-policy=OVERRIDE, base-type=uint8, compu {phys=raw}, range phys 0..252
          signal RequestSeamlessBLEHandoverFBD_HM_SourceFBD: start 8, 8 bit, little-endian, data-type-policy=OVERRIDE, compu {phys=raw}
          signal RequestSeamlessBLEHandoverFBD_HM_TargetFBD: start 16, 8 bit, little-endian, data-type-policy=OVERRIDE, compu {phys=raw}
          signal RequestSeamlessBLEHandoverFBD_HM_NumberRSSIAverage: start 24, 8 bit, little-endian, data-type-policy=OVERRIDE, base-type=uint8, compu {phys=raw}, range phys 0..252
          signal RequestSeamlessBLEHandoverFBD_HM_RSSIThreeshold: start 32, 8 bit, little-endian, data-type-policy=OVERRIDE, base-type=uint8, compu {phys=raw*0.5-127; unit dB}, range phys -127..-1
          signal RequestSeamlessBLEHandoverFBD_HM_RSSIDifference: start 40, 8 bit, little-endian, data-type-policy=OVERRIDE, base-type=uint8, compu {phys=raw*0.5; unit dB}, range phys 0..126
          signal RequestSeamlessBLEHandoverFBD_HM_Delay: start 48, 8 bit, little-endian, data-type-policy=OVERRIDE, base-type=uint8, compu {phys=raw; unit ms}, range phys 0..252
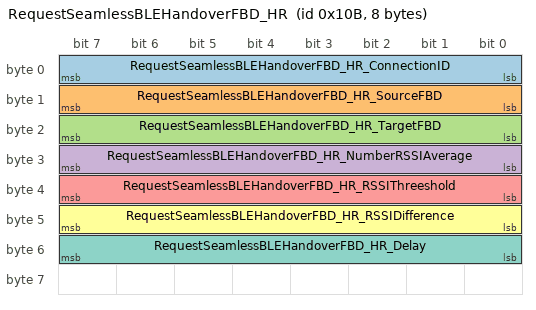
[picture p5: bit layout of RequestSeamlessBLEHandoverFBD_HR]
      frame RequestSeamlessBLEHandoverFBD_HR: id 0x10B, frame-length=8, can-addressing-mode=STANDARD, can-frame-rx-behavior=CAN-20, can-frame-tx-behavior=CAN-20
        pdu RequestSeamlessBLEHandoverFBD_HR: length=8, unused-bit-pattern=0
          signal RequestSeamlessBLEHandoverFBD_HR_ConnectionID: start 0, 8 bit, little-endian, data-type-policy=OVERRIDE, base-type=uint8, compu {phys=raw}, range phys 0..252
          signal RequestSeamlessBLEHandoverFBD_HR_SourceFBD: start 8, 8 bit, little-endian, data-type-policy=OVERRIDE, compu {phys=raw}
          signal RequestSeamlessBLEHandoverFBD_HR_TargetFBD: start 16, 8 bit, little-endian, data-type-policy=OVERRIDE, compu {phys=raw}
          signal RequestSeamlessBLEHandoverFBD_HR_NumberRSSIAverage: start 24, 8 bit, little-endian, data-type-policy=OVERRIDE, base-type=uint8, compu {phys=raw}, range phys 0..252
          signal RequestSeamlessBLEHandoverFBD_HR_RSSIThreeshold: start 32, 8 bit, little-endian, data-type-policy=OVERRIDE, base-type=uint8, compu {phys=raw*0.5-127; unit dB}, range phys -127..-1
          signal RequestSeamlessBLEHandoverFBD_HR_RSSIDifference: start 40, 8 bit, little-endian, data-type-policy=OVERRIDE, base-type=uint8, compu {phys=raw*0.5; unit dB}, range phys 0..126
          signal RequestSeamlessBLEHandoverFBD_HR_Delay: start 48, 8 bit, little-endian, data-type-policy=OVERRIDE, base-type=uint8, compu {phys=raw; unit ms}, range phys 0..252
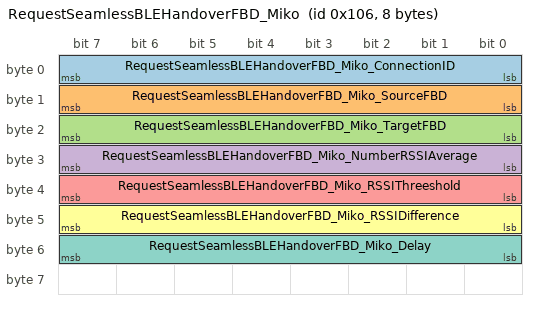
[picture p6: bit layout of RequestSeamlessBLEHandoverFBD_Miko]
      frame RequestSeamlessBLEHandoverFBD_Miko: id 0x106, frame-length=8, can-addressing-mode=STANDARD, can-frame-rx-behavior=CAN-20, can-frame-tx-behavior=CAN-20
        pdu RequestSeamlessBLEHandoverFBD_Miko: length=8, unused-bit-pattern=0
          signal RequestSeamlessBLEHandoverFBD_Miko_ConnectionID: start 0, 8 bit, little-endian, data-type-policy=OVERRIDE, base-type=uint8, compu {phys=raw}, range phys 0..252
          signal RequestSeamlessBLEHandoverFBD_Miko_SourceFBD: start 8, 8 bit, little-endian, data-type-policy=OVERRIDE, compu {phys=raw}
          signal RequestSeamlessBLEHandoverFBD_Miko_TargetFBD: start 16, 8 bit, little-endian, data-type-policy=OVERRIDE, compu {phys=raw}
          signal RequestSeamlessBLEHandoverFBD_Miko_NumberRSSIAverage: start 24, 8 bit, little-endian, data-type-policy=OVERRIDE, base-type=uint8, compu {phys=raw}, range phys 0..252
          signal RequestSeamlessBLEHandoverFBD_Miko_RSSIThreeshold: start 32, 8 bit, little-endian, data-type-policy=OVERRIDE, base-type=uint8, compu {phys=raw*0.5-127; unit dB}, range phys -127..-1
          signal RequestSeamlessBLEHandoverFBD_Miko_RSSIDifference: start 40, 8 bit, little-endian, data-type-policy=OVERRIDE, base-type=uint8, compu {phys=raw*0.5; unit dB}, range phys 0..126
          signal RequestSeamlessBLEHandoverFBD_Miko_Delay: start 48, 8 bit, little-endian, data-type-policy=OVERRIDE, base-type=uint8, compu {phys=raw; unit ms}, range phys 0..252
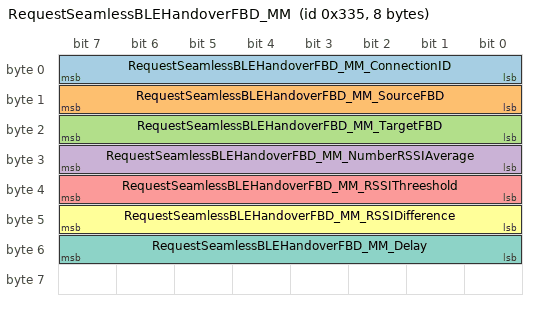
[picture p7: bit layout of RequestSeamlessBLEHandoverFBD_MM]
      frame RequestSeamlessBLEHandoverFBD_MM: id 0x335, frame-length=8, can-addressing-mode=STANDARD, can-frame-rx-behavior=CAN-20, can-frame-tx-behavior=CAN-20
        pdu RequestSeamlessBLEHandoverFBD_MM: length=8, unused-bit-pattern=0
          signal RequestSeamlessBLEHandoverFBD_MM_ConnectionID: start 0, 8 bit, little-endian, data-type-policy=OVERRIDE, base-type=uint8, compu {phys=raw}, range phys 0..252
          signal RequestSeamlessBLEHandoverFBD_MM_SourceFBD: start 8, 8 bit, little-endian, data-type-policy=OVERRIDE, compu {phys=raw}
          signal RequestSeamlessBLEHandoverFBD_MM_TargetFBD: start 16, 8 bit, little-endian, data-type-policy=OVERRIDE, compu {phys=raw}
          signal RequestSeamlessBLEHandoverFBD_MM_NumberRSSIAverage: start 24, 8 bit, little-endian, data-type-policy=OVERRIDE, base-type=uint8, compu {phys=raw}, range phys 0..252
          signal RequestSeamlessBLEHandoverFBD_MM_RSSIThreeshold: start 32, 8 bit, little-endian, data-type-policy=OVERRIDE, base-type=uint8, compu {phys=raw*0.5-127; unit dB}, range phys -127..-1
          signal RequestSeamlessBLEHandoverFBD_MM_RSSIDifference: start 40, 8 bit, little-endian, data-type-policy=OVERRIDE, base-type=uint8, compu {phys=raw*0.5; unit dB}, range phys 0..126
          signal RequestSeamlessBLEHandoverFBD_MM_Delay: start 48, 8 bit, little-endian, data-type-policy=OVERRIDE, base-type=uint8, compu {phys=raw; unit ms}, range phys 0..252
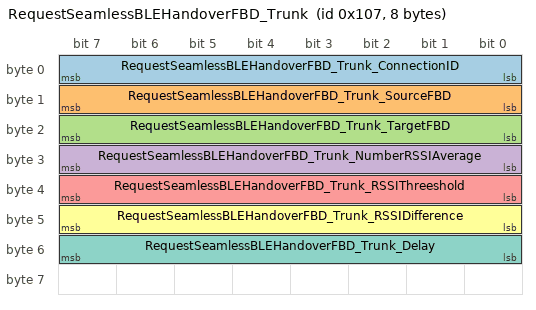
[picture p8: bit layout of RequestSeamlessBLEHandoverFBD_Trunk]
      frame RequestSeamlessBLEHandoverFBD_Trunk: id 0x107, frame-length=8, can-addressing-mode=STANDARD, can-frame-rx-behavior=CAN-20, can-frame-tx-behavior=CAN-20
        pdu RequestSeamlessBLEHandoverFBD_Trunk: length=8, unused-bit-pattern=0
          signal RequestSeamlessBLEHandoverFBD_Trunk_ConnectionID: start 0, 8 bit, little-endian, data-type-policy=OVERRIDE, base-type=uint8, compu {phys=raw}, range phys 0..252
          signal RequestSeamlessBLEHandoverFBD_Trunk_SourceFBD: start 8, 8 bit, little-endian, data-type-policy=OVERRIDE, compu {phys=raw}
          signal RequestSeamlessBLEHandoverFBD_Trunk_TargetFBD: start 16, 8 bit, little-endian, data-type-policy=OVERRIDE, compu {phys=raw}
          signal RequestSeamlessBLEHandoverFBD_Trunk_NumberRSSIAverage: start 24, 8 bit, little-endian, data-type-policy=OVERRIDE, base-type=uint8, compu {phys=raw}, range phys 0..252
          signal RequestSeamlessBLEHandoverFBD_Trunk_RSSIThreeshold: start 32, 8 bit, little-endian, data-type-policy=OVERRIDE, base-type=uint8, compu {phys=raw*0.5-127; unit dB}, range phys -127..-1
          signal RequestSeamlessBLEHandoverFBD_Trunk_RSSIDifference: start 40, 8 bit, little-endian, data-type-policy=OVERRIDE, base-type=uint8, compu {phys=raw*0.5; unit dB}, range phys 0..126
          signal RequestSeamlessBLEHandoverFBD_Trunk_Delay: start 48, 8 bit, little-endian, data-type-policy=OVERRIDE, base-type=uint8, compu {phys=raw; unit ms}, range phys 0..252
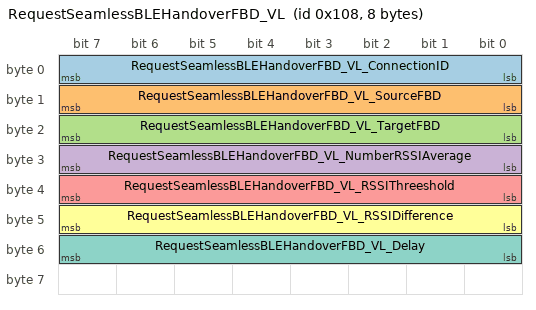
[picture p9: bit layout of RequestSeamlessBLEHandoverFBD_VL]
      frame RequestSeamlessBLEHandoverFBD_VL: id 0x108, frame-length=8, can-addressing-mode=STANDARD, can-frame-rx-behavior=CAN-20, can-frame-tx-behavior=CAN-20
        pdu RequestSeamlessBLEHandoverFBD_VL: length=8, unused-bit-pattern=0
          signal RequestSeamlessBLEHandoverFBD_VL_ConnectionID: start 0, 8 bit, little-endian, data-type-policy=OVERRIDE, base-type=uint8, compu {phys=raw}, range phys 0..252
          signal RequestSeamlessBLEHandoverFBD_VL_SourceFBD: start 8, 8 bit, little-endian, data-type-policy=OVERRIDE, compu {phys=raw}
          signal RequestSeamlessBLEHandoverFBD_VL_TargetFBD: start 16, 8 bit, little-endian, data-type-policy=OVERRIDE, compu {phys=raw}
          signal RequestSeamlessBLEHandoverFBD_VL_NumberRSSIAverage: start 24, 8 bit, little-endian, data-type-policy=OVERRIDE, base-type=uint8, compu {phys=raw}, range phys 0..252
          signal RequestSeamlessBLEHandoverFBD_VL_RSSIThreeshold: start 32, 8 bit, little-endian, data-type-policy=OVERRIDE, base-type=uint8, compu {phys=raw*0.5-127; unit dB}, range phys -127..-1
          signal RequestSeamlessBLEHandoverFBD_VL_RSSIDifference: start 40, 8 bit, little-endian, data-type-policy=OVERRIDE, base-type=uint8, compu {phys=raw*0.5; unit dB}, range phys 0..126
          signal RequestSeamlessBLEHandoverFBD_VL_Delay: start 48, 8 bit, little-endian, data-type-policy=OVERRIDE, base-type=uint8, compu {phys=raw; unit ms}, range phys 0..252
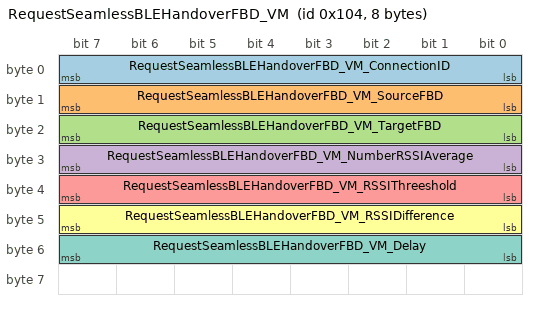
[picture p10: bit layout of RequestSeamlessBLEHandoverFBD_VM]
      frame RequestSeamlessBLEHandoverFBD_VM: id 0x104, frame-length=8, can-addressing-mode=STANDARD, can-frame-rx-behavior=CAN-20, can-frame-tx-behavior=CAN-20
        pdu RequestSeamlessBLEHandoverFBD_VM: length=8, unused-bit-pattern=0
          signal RequestSeamlessBLEHandoverFBD_VM_ConnectionID: start 0, 8 bit, little-endian, data-type-policy=OVERRIDE, base-type=uint8, compu {phys=raw}, range phys 0..252
          signal RequestSeamlessBLEHandoverFBD_VM_SourceFBD: start 8, 8 bit, little-endian, data-type-policy=OVERRIDE, compu {phys=raw}
          signal RequestSeamlessBLEHandoverFBD_VM_TargetFBD: start 16, 8 bit, little-endian, data-type-policy=OVERRIDE, compu {phys=raw}
          signal RequestSeamlessBLEHandoverFBD_VM_NumberRSSIAverage: start 24, 8 bit, little-endian, data-type-policy=OVERRIDE, base-type=uint8, compu {phys=raw}, range phys 0..252
          signal RequestSeamlessBLEHandoverFBD_VM_RSSIThreeshold: start 32, 8 bit, little-endian, data-type-policy=OVERRIDE, base-type=uint8, compu {phys=raw*0.5-127; unit dB}, range phys -127..-1
          signal RequestSeamlessBLEHandoverFBD_VM_RSSIDifference: start 40, 8 bit, little-endian, data-type-policy=OVERRIDE, base-type=uint8, compu {phys=raw*0.5; unit dB}, range phys 0..126
          signal RequestSeamlessBLEHandoverFBD_VM_Delay: start 48, 8 bit, little-endian, data-type-policy=OVERRIDE, base-type=uint8, compu {phys=raw; unit ms}, range phys 0..252
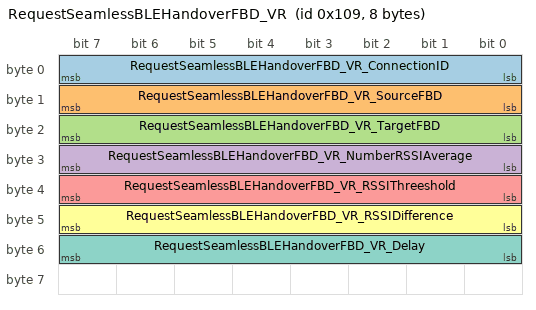
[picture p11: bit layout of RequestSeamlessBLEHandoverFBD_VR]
      frame RequestSeamlessBLEHandoverFBD_VR: id 0x109, frame-length=8, can-addressing-mode=STANDARD, can-frame-rx-behavior=CAN-20, can-frame-tx-behavior=CAN-20
        pdu RequestSeamlessBLEHandoverFBD_VR: length=8, unused-bit-pattern=0
          signal RequestSeamlessBLEHandoverFBD_VR_ConnectionID: start 0, 8 bit, little-endian, data-type-policy=OVERRIDE, base-type=uint8, compu {phys=raw}, range phys 0..252
          signal RequestSeamlessBLEHandoverFBD_VR_SourceFBD: start 8, 8 bit, little-endian, data-type-policy=OVERRIDE, compu {phys=raw}
          signal RequestSeamlessBLEHandoverFBD_VR_TargetFBD: start 16, 8 bit, little-endian, data-type-policy=OVERRIDE, compu {phys=raw}
          signal RequestSeamlessBLEHandoverFBD_VR_NumberRSSIAverage: start 24, 8 bit, little-endian, data-type-policy=OVERRIDE, base-type=uint8, compu {phys=raw}, range phys 0..252
          signal RequestSeamlessBLEHandoverFBD_VR_RSSIThreeshold: start 32, 8 bit, little-endian, data-type-policy=OVERRIDE, base-type=uint8, compu {phys=raw*0.5-127; unit dB}, range phys -127..-1
          signal RequestSeamlessBLEHandoverFBD_VR_RSSIDifference: start 40, 8 bit, little-endian, data-type-policy=OVERRIDE, base-type=uint8, compu {phys=raw*0.5; unit dB}, range phys 0..126
          signal RequestSeamlessBLEHandoverFBD_VR_Delay: start 48, 8 bit, little-endian, data-type-policy=OVERRIDE, base-type=uint8, compu {phys=raw; unit ms}, range phys 0..252
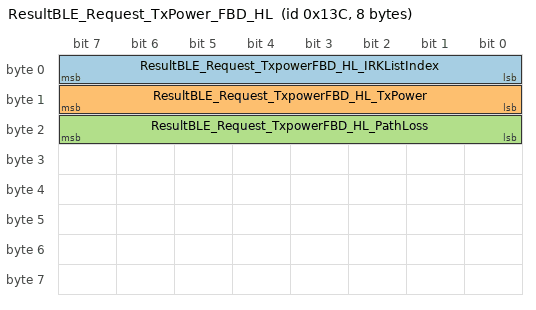
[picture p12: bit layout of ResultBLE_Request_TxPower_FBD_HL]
      frame ResultBLE_Request_TxPower_FBD_HL: id 0x13C, frame-length=8, can-addressing-mode=STANDARD, can-frame-rx-behavior=CAN-20, can-frame-tx-behavior=CAN-20
        pdu ResultBLE_Request_TxPower_FBD_HL: length=8, unused-bit-pattern=0
          signal ResultBLE_Request_TxpowerFBD_HL_IRKListIndex: start 0, 8 bit, little-endian, data-type-policy=OVERRIDE, base-type=uint8, compu {phys=raw}, range phys 0..252
          signal ResultBLE_Request_TxpowerFBD_HL_TxPower: start 8, 8 bit, little-endian, data-type-policy=OVERRIDE, base-type=uint8, compu {phys=raw; unit dB}, range phys 0..252
          signal ResultBLE_Request_TxpowerFBD_HL_PathLoss: start 16, 8 bit, little-endian, data-type-policy=OVERRIDE, base-type=uint8, compu {phys=raw; unit dB}, range phys 0..126
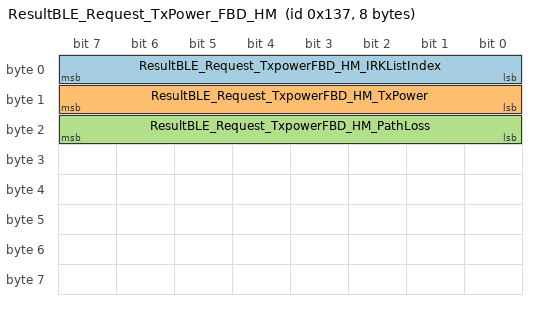
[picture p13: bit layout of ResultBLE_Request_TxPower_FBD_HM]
      frame ResultBLE_Request_TxPower_FBD_HM: id 0x137, frame-length=8, can-addressing-mode=STANDARD, can-frame-rx-behavior=CAN-20, can-frame-tx-behavior=CAN-20
        pdu ResultBLE_Request_TxPower_FBD_HM: length=8, unused-bit-pattern=0
          signal ResultBLE_Request_TxpowerFBD_HM_IRKListIndex: start 0, 8 bit, little-endian, data-type-policy=OVERRIDE, base-type=uint8, compu {phys=raw}, range phys 0..252
          signal ResultBLE_Request_TxpowerFBD_HM_TxPower: start 8, 8 bit, little-endian, data-type-policy=OVERRIDE, base-type=uint8, compu {phys=raw; unit dB}, range phys 0..252
          signal ResultBLE_Request_TxpowerFBD_HM_PathLoss: start 16, 8 bit, little-endian, data-type-policy=OVERRIDE, base-type=uint8, compu {phys=raw; unit dB}, range phys 0..126
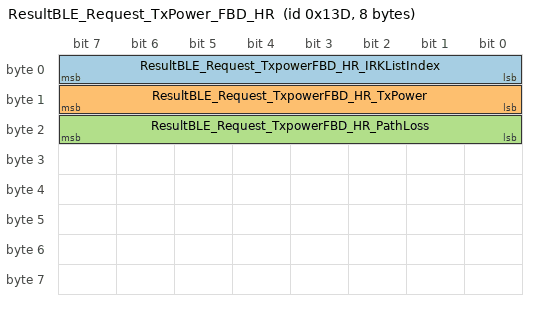
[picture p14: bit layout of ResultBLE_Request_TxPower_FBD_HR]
      frame ResultBLE_Request_TxPower_FBD_HR: id 0x13D, frame-length=8, can-addressing-mode=STANDARD, can-frame-rx-behavior=CAN-20, can-frame-tx-behavior=CAN-20
        pdu ResultBLE_Request_TxPower_FBD_HR: length=8, unused-bit-pattern=0
          signal ResultBLE_Request_TxpowerFBD_HR_IRKListIndex: start 0, 8 bit, little-endian, data-type-policy=OVERRIDE, base-type=uint8, compu {phys=raw}, range phys 0..252
          signal ResultBLE_Request_TxpowerFBD_HR_TxPower: start 8, 8 bit, little-endian, data-type-policy=OVERRIDE, base-type=uint8, compu {phys=raw; unit dB}, range phys 0..252
          signal ResultBLE_Request_TxpowerFBD_HR_PathLoss: start 16, 8 bit, little-endian, data-type-policy=OVERRIDE, base-type=uint8, compu {phys=raw; unit dB}, range phys 0..126
      frame ResultBLE_Request_TxPower_FBD_Miko: id 0x138, frame-length=8, can-addressing-mode=STANDARD, can-frame-rx-behavior=CAN-20, can-frame-tx-behavior=CAN-20
        pdu ResultBLE_Request_TxPower_FBD_Miko: length=8, unused-bit-pattern=0
          signal ResultBLE_Request_TxpowerFBD_Miko_IRKListIndex: start 0, 8 bit, little-endian, data-type-policy=OVERRIDE, base-type=uint8, compu {phys=raw}, range phys 0..252
          signal ResultBLE_Request_TxpowerFBD_Miko_TxPower: start 8, 8 bit, little-endian, data-type-policy=OVERRIDE, base-type=uint8, compu {phys=raw; unit dB}, range phys 0..252
          signal ResultBLE_Request_TxpowerFBD_Miko_PathLoss: start 16, 8 bit, little-endian, data-type-policy=OVERRIDE, base-type=uint8, compu {phys=raw; unit dB}, range phys 0..126
      frame ResultBLE_Request_TxPower_FBD_MM: id 0x13E, frame-length=8, can-addressing-mode=STANDARD, can-frame-rx-behavior=CAN-20, can-frame-tx-behavior=CAN-20
        pdu ResultBLE_Request_TxPower_FBD_MM: length=8, unused-bit-pattern=0
          signal ResultBLE_Request_TxpowerFBD_MM_IRKListIndex: start 0, 8 bit, little-endian, data-type-policy=OVERRIDE, base-type=uint8, compu {phys=raw}, range phys 0..252
          signal ResultBLE_Request_TxpowerFBD_MM_TxPower: start 8, 8 bit, little-endian, data-type-policy=OVERRIDE, base-type=uint8, compu {phys=raw; unit dB}, range phys 0..252
          signal ResultBLE_Request_TxpowerFBD_MM_PathLoss: start 16, 8 bit, little-endian, data-type-policy=OVERRIDE, base-type=uint8, compu {phys=raw; unit dB}, range phys 0..126
      frame ResultBLE_Request_TxPower_FBD_Trunk: id 0x139, frame-length=8, can-addressing-mode=STANDARD, can-frame-rx-behavior=CAN-20, can-frame-tx-behavior=CAN-20
        pdu ResultBLE_Request_TxPower_FBD_Trunk: length=8, unused-bit-pattern=0
          signal ResultBLE_Request_TxpowerFBD_Trunk_IRKListIndex: start 0, 8 bit, little-endian, data-type-policy=OVERRIDE, base-type=uint8, compu {phys=raw}, range phys 0..252
          signal ResultBLE_Request_TxpowerFBD_Trunk_TxPower: start 8, 8 bit, little-endian, data-type-policy=OVERRIDE, base-type=uint8, compu {phys=raw; unit dB}, range phys 0..252
          signal ResultBLE_Request_TxpowerFBD_Trunk_PathLoss: start 16, 8 bit, little-endian, data-type-policy=OVERRIDE, base-type=uint8, compu {phys=raw; unit dB}, range phys 0..126
      frame ResultBLE_Request_TxPower_FBD_VL: id 0x13A, frame-length=8, can-addressing-mode=STANDARD, can-frame-rx-behavior=CAN-20, can-frame-tx-behavior=CAN-20
        pdu ResultBLE_Request_TxPower_FBD_VL: length=8, unused-bit-pattern=0
          signal ResultBLE_Request_TxpowerFBD_VL_IRKListIndex: start 0, 8 bit, little-endian, data-type-policy=OVERRIDE, base-type=uint8, compu {phys=raw}, range phys 0..252
          signal ResultBLE_Request_TxpowerFBD_VL_TxPower: start 8, 8 bit, little-endian, data-type-policy=OVERRIDE, base-type=uint8, compu {phys=raw; unit dB}, range phys 0..252
          signal ResultBLE_Request_TxpowerFBD_VL_PathLoss: start 16, 8 bit, little-endian, data-type-policy=OVERRIDE, base-type=uint8, compu {phys=raw; unit dB}, range phys 0..126
      frame ResultBLE_Request_TxPower_FBD_VM: id 0x136, frame-length=8, can-addressing-mode=STANDARD, can-frame-rx-behavior=CAN-20, can-frame-tx-behavior=CAN-20
        pdu ResultBLE_Request_TxPower_FBD_VM: length=8, unused-bit-pattern=0
          signal ResultBLE_Request_TxpowerFBD_VM_IRKListIndex: start 0, 8 bit, little-endian, data-type-policy=OVERRIDE, base-type=uint8, compu {phys=raw}, range phys 0..252
          signal ResultBLE_Request_TxpowerFBD_VM_TxPower: start 8, 8 bit, little-endian, data-type-policy=OVERRIDE, base-type=uint8, compu {phys=raw; unit dB}, range phys 0..252
          signal ResultBLE_Request_TxpowerFBD_VM_PathLoss: start 16, 8 bit, little-endian, data-type-policy=OVERRIDE, base-type=uint8, compu {phys=raw; unit dB}, range phys 0..126
      frame ResultBLE_Request_TxPower_FBD_VR: id 0x13B, frame-length=8, can-addressing-mode=STANDARD, can-frame-rx-behavior=CAN-20, can-frame-tx-behavior=CAN-20
        pdu ResultBLE_Request_TxPower_FBD_VR: length=8, unused-bit-pattern=0
          signal ResultBLE_Request_TxpowerFBD_VR_IRKListIndex: start 0, 8 bit, little-endian, data-type-policy=OVERRIDE, base-type=uint8, compu {phys=raw}, range phys 0..252
          signal ResultBLE_Request_TxpowerFBD_VR_TxPower: start 8, 8 bit, little-endian, data-type-policy=OVERRIDE, base-type=uint8, compu {phys=raw; unit dB}, range phys 0..252
          signal ResultBLE_Request_TxpowerFBD_VR_PathLoss: start 16, 8 bit, little-endian, data-type-policy=OVERRIDE, base-type=uint8, compu {phys=raw; unit dB}, range phys 0..126
      frame ResultBLEConMonitoringFBD_HL: id 0x128, frame-length=64, can-addressing-mode=STANDARD, can-frame-rx-behavior=CAN-FD, can-frame-tx-behavior=CAN-FD
        pdu ResultBLEConMonitoringFBD_HL: length=64, unused-bit-pattern=0
          signal ResultBLEConMonitoringFBD_HL_IRKListID: start 0, 8 bit, little-endian, data-type-policy=OVERRIDE, base-type=uint8, compu {phys=raw}, range phys 0..252
          signal ResultBLEConMonitoringFBD_HL_RSSILevel01: start 8, 8 bit, little-endian, data-type-policy=OVERRIDE, base-type=uint8, compu {phys=raw; unit dB}, range phys 0..252
          signal ResultBLEConMonitoringFBD_HL_connEventCounter01: start 16, 16 bit, little-endian, data-type-policy=OVERRIDE, base-type=uint16, compu {phys=raw}, range phys 0..65532
          signal ResultBLEConMonitoringFBD_HL_Ch_Num01: start 32, 8 bit, little-endian, data-type-policy=OVERRIDE, base-type=uint8, compu {phys=raw}, range phys 0..252
          signal ResultBLEConMonitoringFBD_HL_Dev_TxPower: start 40, 8 bit, little-endian, data-type-policy=OVERRIDE, base-type=uint8, compu {phys=raw}, range phys 0..252
          signal ResultBLEConMonitoringFBD_HL_RSSILevel02: start 48, 8 bit, little-endian, data-type-policy=OVERRIDE, base-type=uint8, compu {phys=raw; unit dB}, range phys 0..252
          signal ResultBLEConMonitoringFBD_HL_connEventCounter02: start 56, 16 bit, little-endian, data-type-policy=OVERRIDE, base-type=uint16, compu {phys=raw}, range phys 0..65532
          signal ResultBLEConMonitoringFBD_HL_Ch_Num02: start 72, 8 bit, little-endian, data-type-policy=OVERRIDE, base-type=uint8, compu {phys=raw}, range phys 0..252
          signal ResultBLEConMonitoringFBD_HL_Ch_qual02: start 80, 8 bit, little-endian, data-type-policy=OVERRIDE, base-type=uint8, compu {phys=raw}, range phys 0..252
          signal ResultBLEConMonitoringFBD_HL_RSSILevel03: start 88, 8 bit, little-endian, data-type-policy=OVERRIDE, base-type=uint8, compu {phys=raw; unit dB}, range phys 0..252
          signal ResultBLEConMonitoringFBD_HL_connEventCounter03: start 96, 16 bit, little-endian, data-type-policy=OVERRIDE, base-type=uint16, compu {phys=raw}, range phys 0..65532
          signal ResultBLEConMonitoringFBD_HL_Ch_Num03: start 112, 8 bit, little-endian, data-type-policy=OVERRIDE, base-type=uint8, compu {phys=raw}, range phys 0..252
          signal ResultBLEConMonitoringFBD_HL_Ch_qual03: start 120, 8 bit, little-endian, data-type-policy=OVERRIDE, base-type=uint8, compu {phys=raw}, range phys 0..252
          signal ResultBLEConMonitoringFBD_HL_RSSILevel04: start 128, 8 bit, little-endian, data-type-policy=OVERRIDE, base-type=uint8, compu {phys=raw; unit dB}, range phys 0..252
          signal ResultBLEConMonitoringFBD_HL_connEventCounter04: start 136, 16 bit, little-endian, data-type-policy=OVERRIDE, base-type=uint16, compu {phys=raw}, range phys 0..65532
          signal ResultBLEConMonitoringFBD_HL_Ch_Num04: start 152, 8 bit, little-endian, data-type-policy=OVERRIDE, base-type=uint8, compu {phys=raw}, range phys 0..252
          signal ResultBLEConMonitoringFBD_HL_Ch_qual04: start 160, 8 bit, little-endian, data-type-policy=OVERRIDE, base-type=uint8, compu {phys=raw}, range phys 0..252
          signal ResultBLEConMonitoringFBD_HL_RSSILevel05: start 168, 8 bit, little-endian, data-type-policy=OVERRIDE, base-type=uint8, compu {phys=raw; unit dB}, range phys 0..252
          signal ResultBLEConMonitoringFBD_HL_connEventCounter05: start 176, 16 bit, little-endian, data-type-policy=OVERRIDE, base-type=uint16, compu {phys=raw}, range phys 0..65532
          signal ResultBLEConMonitoringFBD_HL_Ch_Num05: start 192, 8 bit, little-endian, data-type-policy=OVERRIDE, base-type=uint8, compu {phys=raw}, range phys 0..252
          signal ResultBLEConMonitoringFBD_HL_Ch_qual05: start 200, 8 bit, little-endian, data-type-policy=OVERRIDE, base-type=uint8, compu {phys=raw}, range phys 0..252
          signal ResultBLEConMonitoringFBD_HL_RSSILevel06: start 208, 8 bit, little-endian, data-type-policy=OVERRIDE, base-type=uint8, compu {phys=raw; unit dB}, range phys 0..252
          signal ResultBLEConMonitoringFBD_HL_connEventCounter06: start 216, 16 bit, little-endian, data-type-policy=OVERRIDE, base-type=uint16, compu {phys=raw}, range phys 0..65532
          signal ResultBLEConMonitoringFBD_HL_Ch_Num06: start 232, 8 bit, little-endian, data-type-policy=OVERRIDE, base-type=uint8, compu {phys=raw}, range phys 0..252
          signal ResultBLEConMonitoringFBD_HL_Ch_qual06: start 240, 8 bit, little-endian, data-type-policy=OVERRIDE, base-type=uint8, compu {phys=raw}, range phys 0..252
          signal ResultBLEConMonitoringFBD_HL_RSSILevel07: start 248, 8 bit, little-endian, data-type-policy=OVERRIDE, base-type=uint8, compu {phys=raw; unit dB}, range phys 0..252
          signal ResultBLEConMonitoringFBD_HL_connEventCounter07: start 256, 16 bit, little-endian, data-type-policy=OVERRIDE, base-type=uint16, compu {phys=raw}, range phys 0..65532
          signal ResultBLEConMonitoringFBD_HL_Ch_Num07: start 272, 8 bit, little-endian, data-type-policy=OVERRIDE, base-type=uint8, compu {phys=raw}, range phys 0..252
          signal ResultBLEConMonitoringFBD_HL_Ch_qual07: start 280, 8 bit, little-endian, data-type-policy=OVERRIDE, base-type=uint8, compu {phys=raw}, range phys 0..252
          signal ResultBLEConMonitoringFBD_HL_RSSILevel08: start 288, 8 bit, little-endian, data-type-policy=OVERRIDE, base-type=uint8, compu {phys=raw; unit dB}, range phys 0..252
          signal ResultBLEConMonitoringFBD_HL_connEventCounter08: start 296, 16 bit, little-endian, data-type-policy=OVERRIDE, base-type=uint16, compu {phys=raw}, range phys 0..65532
          signal ResultBLEConMonitoringFBD_HL_Ch_Num08: start 312, 8 bit, little-endian, data-type-policy=OVERRIDE, base-type=uint8, compu {phys=raw}, range phys 0..252
          signal ResultBLEConMonitoringFBD_HL_Ch_qual08: start 320, 8 bit, little-endian, data-type-policy=OVERRIDE, base-type=uint8, compu {phys=raw}, range phys 0..252
          signal ResultBLEConMonitoringFBD_HL_RSSILevel09: start 328, 8 bit, little-endian, data-type-policy=OVERRIDE, base-type=uint8, compu {phys=raw; unit dB}, range phys 0..252
          signal ResultBLEConMonitoringFBD_HL_connEventCounter09: start 336, 16 bit, little-endian, data-type-policy=OVERRIDE, base-type=uint16, compu {phys=raw}, range phys 0..65532
          signal ResultBLEConMonitoringFBD_HL_Ch_Num09: start 352, 8 bit, little-endian, data-type-policy=OVERRIDE, base-type=uint8, compu {phys=raw}, range phys 0..252
          signal ResultBLEConMonitoringFBD_HL_Ch_qual09: start 360, 8 bit, little-endian, data-type-policy=OVERRIDE, base-type=uint8, compu {phys=raw}, range phys 0..252
          signal ResultBLEConMonitoringFBD_HL_RSSILevel10: start 368, 8 bit, little-endian, data-type-policy=OVERRIDE, base-type=uint8, compu {phys=raw; unit dB}, range phys 0..252
          signal ResultBLEConMonitoringFBD_HL_connEventCounter10: start 376, 16 bit, little-endian, data-type-policy=OVERRIDE, base-type=uint16, compu {phys=raw}, range phys 0..65532
          signal ResultBLEConMonitoringFBD_HL_Ch_Num10: start 392, 8 bit, little-endian, data-type-policy=OVERRIDE, base-type=uint8, compu {phys=raw}, range phys 0..252
          signal ResultBLEConMonitoringFBD_HL_Ch_qual10: start 400, 8 bit, little-endian, data-type-policy=OVERRIDE, base-type=uint8, compu {phys=raw}, range phys 0..252
          signal ResultBLEConMonitoringFBD_HL_IV00: start 408, 8 bit, little-endian, data-type-policy=OVERRIDE, base-type=uint8, compu {phys=raw}, range phys 0..255
          signal ResultBLEConMonitoringFBD_HL_IV01: start 416, 8 bit, little-endian, data-type-policy=OVERRIDE, base-type=uint8, compu {phys=raw}, range phys 0..255
          signal ResultBLEConMonitoringFBD_HL_IV02: start 424, 8 bit, little-endian, data-type-policy=OVERRIDE, base-type=uint8, compu {phys=raw}, range phys 0..255
          signal ResultBLEConMonitoringFBD_HL_IV03: start 432, 8 bit, little-endian, data-type-policy=OVERRIDE, base-type=uint8, compu {phys=raw}, range phys 0..255
          signal ResultBLEConMonitoringFBD_HL_Sign00: start 440, 8 bit, little-endian, data-type-policy=OVERRIDE, base-type=uint8, compu {phys=raw}, range phys 0..255
          signal ResultBLEConMonitoringFBD_HL_Sign01: start 448, 8 bit, little-endian, data-type-policy=OVERRIDE, base-type=uint8, compu {phys=raw}, range phys 0..255
          signal ResultBLEConMonitoringFBD_HL_Sign02: start 456, 8 bit, little-endian, data-type-policy=OVERRIDE, base-type=uint8, compu {phys=raw}, range phys 0..255
          signal ResultBLEConMonitoringFBD_HL_Sign03: start 464, 8 bit, little-endian, data-type-policy=OVERRIDE, base-type=uint8, compu {phys=raw}, range phys 0..255
          signal ResultBLEConMonitoringFBD_HL_Sign04: start 472, 8 bit, little-endian, data-type-policy=OVERRIDE, base-type=uint8, compu {phys=raw}, range phys 0..255
          signal ResultBLEConMonitoringFBD_HL_Sign05: start 480, 8 bit, little-endian, data-type-policy=OVERRIDE, base-type=uint8, compu {phys=raw}, range phys 0..255
          signal ResultBLEConMonitoringFBD_HL_Sign06: start 488, 8 bit, little-endian, data-type-policy=OVERRIDE, base-type=uint8, compu {phys=raw}, range phys 0..255
          signal ResultBLEConMonitoringFBD_HL_Sign07: start 496, 8 bit, little-endian, data-type-policy=OVERRIDE, base-type=uint8, compu {phys=raw}, range phys 0..255
      frame ResultBLEConMonitoringFBD_HM: id 0x123, frame-length=64, can-addressing-mode=STANDARD, can-frame-rx-behavior=CAN-FD, can-frame-tx-behavior=CAN-FD
        pdu ResultBLEConMonitoringFBD_HM: length=64, unused-bit-pattern=0
          signal ResultBLEConMonitoringFBD_HM_IRKListID: start 0, 8 bit, little-endian, data-type-policy=OVERRIDE, base-type=uint8, compu {phys=raw}, range phys 0..252
          signal ResultBLEConMonitoringFBD_HM_RSSILevel01: start 8, 8 bit, little-endian, data-type-policy=OVERRIDE, base-type=uint8, compu {phys=raw; unit dB}, range phys 0..252
          signal ResultBLEConMonitoringFBD_HM_connEventCounter01: start 16, 16 bit, little-endian, data-type-policy=OVERRIDE, base-type=uint16, compu {phys=raw}, range phys 0..65532
          signal ResultBLEConMonitoringFBD_HM_Ch_Num01: start 32, 8 bit, little-endian, data-type-policy=OVERRIDE, base-type=uint8, compu {phys=raw}, range phys 0..252
          signal ResultBLEConMonitoringFBD_HM_Dev_TxPower: start 40, 8 bit, little-endian, data-type-policy=OVERRIDE, base-type=uint8, compu {phys=raw}, range phys 0..252
          signal ResultBLEConMonitoringFBD_HM_RSSILevel02: start 48, 8 bit, little-endian, data-type-policy=OVERRIDE, base-type=uint8, compu {phys=raw; unit dB}, range phys 0..252
          signal ResultBLEConMonitoringFBD_HM_connEventCounter02: start 56, 16 bit, little-endian, data-type-policy=OVERRIDE, base-type=uint16, compu {phys=raw}, range phys 0..65532
          signal ResultBLEConMonitoringFBD_HM_Ch_Num02: start 72, 8 bit, little-endian, data-type-policy=OVERRIDE, base-type=uint8, compu {phys=raw}, range phys 0..252
          signal ResultBLEConMonitoringFBD_HM_Ch_qual02: start 80, 8 bit, little-endian, data-type-policy=OVERRIDE, base-type=uint8, compu {phys=raw}, range phys 0..252
          signal ResultBLEConMonitoringFBD_HM_RSSILevel03: start 88, 8 bit, little-endian, data-type-policy=OVERRIDE, base-type=uint8, compu {phys=raw; unit dB}, range phys 0..252
          signal ResultBLEConMonitoringFBD_HM_connEventCounter03: start 96, 16 bit, little-endian, data-type-policy=OVERRIDE, base-type=uint16, compu {phys=raw}, range phys 0..65532
          signal ResultBLEConMonitoringFBD_HM_Ch_Num03: start 112, 8 bit, little-endian, data-type-policy=OVERRIDE, base-type=uint8, compu {phys=raw}, range phys 0..252
          signal ResultBLEConMonitoringFBD_HM_Ch_qual03: start 120, 8 bit, little-endian, data-type-policy=OVERRIDE, base-type=uint8, compu {phys=raw}, range phys 0..252
          signal ResultBLEConMonitoringFBD_HM_RSSILevel04: start 128, 8 bit, little-endian, data-type-policy=OVERRIDE, base-type=uint8, compu {phys=raw; unit dB}, range phys 0..252
          signal ResultBLEConMonitoringFBD_HM_connEventCounter04: start 136, 16 bit, little-endian, data-type-policy=OVERRIDE, base-type=uint16, compu {phys=raw}, range phys 0..65532
          signal ResultBLEConMonitoringFBD_HM_Ch_Num04: start 152, 8 bit, little-endian, data-type-policy=OVERRIDE, base-type=uint8, compu {phys=raw}, range phys 0..252
          signal ResultBLEConMonitoringFBD_HM_Ch_qual04: start 160, 8 bit, little-endian, data-type-policy=OVERRIDE, base-type=uint8, compu {phys=raw}, range phys 0..252
          signal ResultBLEConMonitoringFBD_HM_RSSILevel05: start 168, 8 bit, little-endian, data-type-policy=OVERRIDE, base-type=uint8, compu {phys=raw; unit dB}, range phys 0..252
          signal ResultBLEConMonitoringFBD_HM_connEventCounter05: start 176, 16 bit, little-endian, data-type-policy=OVERRIDE, base-type=uint16, compu {phys=raw}, range phys 0..65532
          signal ResultBLEConMonitoringFBD_HM_Ch_Num05: start 192, 8 bit, little-endian, data-type-policy=OVERRIDE, base-type=uint8, compu {phys=raw}, range phys 0..252
          signal ResultBLEConMonitoringFBD_HM_Ch_qual05: start 200, 8 bit, little-endian, data-type-policy=OVERRIDE, base-type=uint8, compu {phys=raw}, range phys 0..252
          signal ResultBLEConMonitoringFBD_HM_RSSILevel06: start 208, 8 bit, little-endian, data-type-policy=OVERRIDE, base-type=uint8, compu {phys=raw; unit dB}, range phys 0..252
          signal ResultBLEConMonitoringFBD_HM_connEventCounter06: start 216, 16 bit, little-endian, data-type-policy=OVERRIDE, base-type=uint16, compu {phys=raw}, range phys 0..65532
          signal ResultBLEConMonitoringFBD_HM_Ch_Num06: start 232, 8 bit, little-endian, data-type-policy=OVERRIDE, base-type=uint8, compu {phys=raw}, range phys 0..252
          signal ResultBLEConMonitoringFBD_HM_Ch_qual06: start 240, 8 bit, little-endian, data-type-policy=OVERRIDE, base-type=uint8, compu {phys=raw}, range phys 0..252
          signal ResultBLEConMonitoringFBD_HM_RSSILevel07: start 248, 8 bit, little-endian, data-type-policy=OVERRIDE, base-type=uint8, compu {phys=raw; unit dB}, range phys 0..252
          signal ResultBLEConMonitoringFBD_HM_connEventCounter07: start 256, 16 bit, little-endian, data-type-policy=OVERRIDE, base-type=uint16, compu {phys=raw}, range phys 0..65532
          signal ResultBLEConMonitoringFBD_HM_Ch_Num07: start 272, 8 bit, little-endian, data-type-policy=OVERRIDE, base-type=uint8, compu {phys=raw}, range phys 0..252
          signal ResultBLEConMonitoringFBD_HM_Ch_qual07: start 280, 8 bit, little-endian, data-type-policy=OVERRIDE, base-type=uint8, compu {phys=raw}, range phys 0..252
          signal ResultBLEConMonitoringFBD_HM_RSSILevel08: start 288, 8 bit, little-endian, data-type-policy=OVERRIDE, base-type=uint8, compu {phys=raw; unit dB}, range phys 0..252
          signal ResultBLEConMonitoringFBD_HM_connEventCounter08: start 296, 16 bit, little-endian, data-type-policy=OVERRIDE, base-type=uint16, compu {phys=raw}, range phys 0..65532
          signal ResultBLEConMonitoringFBD_HM_Ch_Num08: start 312, 8 bit, little-endian, data-type-policy=OVERRIDE, base-type=uint8, compu {phys=raw}, range phys 0..252
          signal ResultBLEConMonitoringFBD_HM_Ch_qual08: start 320, 8 bit, little-endian, data-type-policy=OVERRIDE, base-type=uint8, compu {phys=raw}, range phys 0..252
          signal ResultBLEConMonitoringFBD_HM_RSSILevel09: start 328, 8 bit, little-endian, data-type-policy=OVERRIDE, base-type=uint8, compu {phys=raw; unit dB}, range phys 0..252
          signal ResultBLEConMonitoringFBD_HM_connEventCounter09: start 336, 16 bit, little-endian, data-type-policy=OVERRIDE, base-type=uint16, compu {phys=raw}, range phys 0..65532
          signal ResultBLEConMonitoringFBD_HM_Ch_Num09: start 352, 8 bit, little-endian, data-type-policy=OVERRIDE, base-type=uint8, compu {phys=raw}, range phys 0..252
          signal ResultBLEConMonitoringFBD_HM_Ch_qual09: start 360, 8 bit, little-endian, data-type-policy=OVERRIDE, base-type=uint8, compu {phys=raw}, range phys 0..252
          signal ResultBLEConMonitoringFBD_HM_RSSILevel10: start 368, 8 bit, little-endian, data-type-policy=OVERRIDE, base-type=uint8, compu {phys=raw; unit dB}, range phys 0..252
          signal ResultBLEConMonitoringFBD_HM_connEventCounter10: start 376, 16 bit, little-endian, data-type-policy=OVERRIDE, base-type=uint16, compu {phys=raw}, range phys 0..65532
          signal ResultBLEConMonitoringFBD_HM_Ch_Num10: start 392, 8 bit, little-endian, data-type-policy=OVERRIDE, base-type=uint8, compu {phys=raw}, range phys 0..252
          signal ResultBLEConMonitoringFBD_HM_Ch_qual10: start 400, 8 bit, little-endian, data-type-policy=OVERRIDE, base-type=uint8, compu {phys=raw}, range phys 0..252
          signal ResultBLEConMonitoringFBD_HM_IV00: start 408, 8 bit, little-endian, data-type-policy=OVERRIDE, base-type=uint8, compu {phys=raw}, range phys 0..255
          signal ResultBLEConMonitoringFBD_HM_IV01: start 416, 8 bit, little-endian, data-type-policy=OVERRIDE, base-type=uint8, compu {phys=raw}, range phys 0..255
          signal ResultBLEConMonitoringFBD_HM_IV02: start 424, 8 bit, little-endian, data-type-policy=OVERRIDE, base-type=uint8, compu {phys=raw}, range phys 0..255
          signal ResultBLEConMonitoringFBD_HM_IV03: start 432, 8 bit, little-endian, data-type-policy=OVERRIDE, base-type=uint8, compu {phys=raw}, range phys 0..255
          signal ResultBLEConMonitoringFBD_HM_Sign00: start 440, 8 bit, little-endian, data-type-policy=OVERRIDE, base-type=uint8, compu {phys=raw}, range phys 0..255
          signal ResultBLEConMonitoringFBD_HM_Sign01: start 448, 8 bit, little-endian, data-type-policy=OVERRIDE, base-type=uint8, compu {phys=raw}, range phys 0..255
          signal ResultBLEConMonitoringFBD_HM_Sign02: start 456, 8 bit, little-endian, data-type-policy=OVERRIDE, base-type=uint8, compu {phys=raw}, range phys 0..255
          signal ResultBLEConMonitoringFBD_HM_Sign03: start 464, 8 bit, little-endian, data-type-policy=OVERRIDE, base-type=uint8, compu {phys=raw}, range phys 0..255
          signal ResultBLEConMonitoringFBD_HM_Sign04: start 472, 8 bit, little-endian, data-type-policy=OVERRIDE, base-type=uint8, compu {phys=raw}, range phys 0..255
          signal ResultBLEConMonitoringFBD_HM_Sign05: start 480, 8 bit, little-endian, data-type-policy=OVERRIDE, base-type=uint8, compu {phys=raw}, range phys 0..255
          signal ResultBLEConMonitoringFBD_HM_Sign06: start 488, 8 bit, little-endian, data-type-policy=OVERRIDE, base-type=uint8, compu {phys=raw}, range phys 0..255
          signal ResultBLEConMonitoringFBD_HM_Sign07: start 496, 8 bit, little-endian, data-type-policy=OVERRIDE, base-type=uint8, compu {phys=raw}, range phys 0..255
      frame ResultBLEConMonitoringFBD_HR: id 0x129, frame-length=64, can-addressing-mode=STANDARD, can-frame-rx-behavior=CAN-FD, can-frame-tx-behavior=CAN-FD
        pdu ResultBLEConMonitoringFBD_HR: length=64, unused-bit-pattern=0
          signal ResultBLEConMonitoringFBD_HR_IRKListID: start 0, 8 bit, little-endian, data-type-policy=OVERRIDE, base-type=uint8, compu {phys=raw}, range phys 0..252
          signal ResultBLEConMonitoringFBD_HR_RSSILevel01: start 8, 8 bit, little-endian, data-type-policy=OVERRIDE, base-type=uint8, compu {phys=raw; unit dB}, range phys 0..252
          signal ResultBLEConMonitoringFBD_HR_connEventCounter01: start 16, 16 bit, little-endian, data-type-policy=OVERRIDE, base-type=uint16, compu {phys=raw}, range phys 0..65532
          signal ResultBLEConMonitoringFBD_HR_Ch_Num01: start 32, 8 bit, little-endian, data-type-policy=OVERRIDE, base-type=uint8, compu {phys=raw}, range phys 0..252
          signal ResultBLEConMonitoringFBD_HR_Dev_TxPower: start 40, 8 bit, little-endian, data-type-policy=OVERRIDE, base-type=uint8, compu {phys=raw}, range phys 0..252
          signal ResultBLEConMonitoringFBD_HR_RSSILevel02: start 48, 8 bit, little-endian, data-type-policy=OVERRIDE, base-type=uint8, compu {phys=raw; unit dB}, range phys 0..252
          signal ResultBLEConMonitoringFBD_HR_connEventCounter02: start 56, 16 bit, little-endian, data-type-policy=OVERRIDE, base-type=uint16, compu {phys=raw}, range phys 0..65532
          signal ResultBLEConMonitoringFBD_HR_Ch_Num02: start 72, 8 bit, little-endian, data-type-policy=OVERRIDE, base-type=uint8, compu {phys=raw}, range phys 0..252
          signal ResultBLEConMonitoringFBD_HR_Ch_qual02: start 80, 8 bit, little-endian, data-type-policy=OVERRIDE, base-type=uint8, compu {phys=raw}, range phys 0..252
          signal ResultBLEConMonitoringFBD_HR_RSSILevel03: start 88, 8 bit, little-endian, data-type-policy=OVERRIDE, base-type=uint8, compu {phys=raw; unit dB}, range phys 0..252
          signal ResultBLEConMonitoringFBD_HR_connEventCounter03: start 96, 16 bit, little-endian, data-type-policy=OVERRIDE, base-type=uint16, compu {phys=raw}, range phys 0..65532
          signal ResultBLEConMonitoringFBD_HR_Ch_Num03: start 112, 8 bit, little-endian, data-type-policy=OVERRIDE, base-type=uint8, compu {phys=raw}, range phys 0..252
          signal ResultBLEConMonitoringFBD_HR_Ch_qual03: start 120, 8 bit, little-endian, data-type-policy=OVERRIDE, base-type=uint8, compu {phys=raw}, range phys 0..252
          signal ResultBLEConMonitoringFBD_HR_RSSILevel04: start 128, 8 bit, little-endian, data-type-policy=OVERRIDE, base-type=uint8, compu {phys=raw; unit dB}, range phys 0..252
          signal ResultBLEConMonitoringFBD_HR_connEventCounter04: start 136, 16 bit, little-endian, data-type-policy=OVERRIDE, base-type=uint16, compu {phys=raw}, range phys 0..65532
          signal ResultBLEConMonitoringFBD_HR_Ch_Num04: start 152, 8 bit, little-endian, data-type-policy=OVERRIDE, base-type=uint8, compu {phys=raw}, range phys 0..252
          signal ResultBLEConMonitoringFBD_HR_Ch_qual04: start 160, 8 bit, little-endian, data-type-policy=OVERRIDE, base-type=uint8, compu {phys=raw}, range phys 0..252
          signal ResultBLEConMonitoringFBD_HR_RSSILevel05: start 168, 8 bit, little-endian, data-type-policy=OVERRIDE, base-type=uint8, compu {phys=raw; unit dB}, range phys 0..252
          signal ResultBLEConMonitoringFBD_HR_connEventCounter05: start 176, 16 bit, little-endian, data-type-policy=OVERRIDE, base-type=uint16, compu {phys=raw}, range phys 0..65532
          signal ResultBLEConMonitoringFBD_HR_Ch_Num05: start 192, 8 bit, little-endian, data-type-policy=OVERRIDE, base-type=uint8, compu {phys=raw}, range phys 0..252
          signal ResultBLEConMonitoringFBD_HR_Ch_qual05: start 200, 8 bit, little-endian, data-type-policy=OVERRIDE, base-type=uint8, compu {phys=raw}, range phys 0..252
          signal ResultBLEConMonitoringFBD_HR_RSSILevel06: start 208, 8 bit, little-endian, data-type-policy=OVERRIDE, base-type=uint8, compu {phys=raw; unit dB}, range phys 0..252
          signal ResultBLEConMonitoringFBD_HR_connEventCounter06: start 216, 16 bit, little-endian, data-type-policy=OVERRIDE, base-type=uint16, compu {phys=raw}, range phys 0..65532
          signal ResultBLEConMonitoringFBD_HR_Ch_Num06: start 232, 8 bit, little-endian, data-type-policy=OVERRIDE, base-type=uint8, compu {phys=raw}, range phys 0..252
          signal ResultBLEConMonitoringFBD_HR_Ch_qual06: start 240, 8 bit, little-endian, data-type-policy=OVERRIDE, base-type=uint8, compu {phys=raw}, range phys 0..252
          signal ResultBLEConMonitoringFBD_HR_RSSILevel07: start 248, 8 bit, little-endian, data-type-policy=OVERRIDE, base-type=uint8, compu {phys=raw; unit dB}, range phys 0..252
          signal ResultBLEConMonitoringFBD_HR_connEventCounter07: start 256, 16 bit, little-endian, data-type-policy=OVERRIDE, base-type=uint16, compu {phys=raw}, range phys 0..65532
          signal ResultBLEConMonitoringFBD_HR_Ch_Num07: start 272, 8 bit, little-endian, data-type-policy=OVERRIDE, base-type=uint8, compu {phys=raw}, range phys 0..252
          signal ResultBLEConMonitoringFBD_HR_Ch_qual07: start 280, 8 bit, little-endian, data-type-policy=OVERRIDE, base-type=uint8, compu {phys=raw}, range phys 0..252
          signal ResultBLEConMonitoringFBD_HR_RSSILevel08: start 288, 8 bit, little-endian, data-type-policy=OVERRIDE, base-type=uint8, compu {phys=raw; unit dB}, range phys 0..252
          signal ResultBLEConMonitoringFBD_HR_connEventCounter08: start 296, 16 bit, little-endian, data-type-policy=OVERRIDE, base-type=uint16, compu {phys=raw}, range phys 0..65532
          signal ResultBLEConMonitoringFBD_HR_Ch_Num08: start 312, 8 bit, little-endian, data-type-policy=OVERRIDE, base-type=uint8, compu {phys=raw}, range phys 0..252
          signal ResultBLEConMonitoringFBD_HR_Ch_qual08: start 320, 8 bit, little-endian, data-type-policy=OVERRIDE, base-type=uint8, compu {phys=raw}, range phys 0..252
          signal ResultBLEConMonitoringFBD_HR_RSSILevel09: start 328, 8 bit, little-endian, data-type-policy=OVERRIDE, base-type=uint8, compu {phys=raw; unit dB}, range phys 0..252
          signal ResultBLEConMonitoringFBD_HR_connEventCounter09: start 336, 16 bit, little-endian, data-type-policy=OVERRIDE, base-type=uint16, compu {phys=raw}, range phys 0..65532
          signal ResultBLEConMonitoringFBD_HR_Ch_Num09: start 352, 8 bit, little-endian, data-type-policy=OVERRIDE, base-type=uint8, compu {phys=raw}, range phys 0..252
          signal ResultBLEConMonitoringFBD_HR_Ch_qual09: start 360, 8 bit, little-endian, data-type-policy=OVERRIDE, base-type=uint8, compu {phys=raw}, range phys 0..252
          signal ResultBLEConMonitoringFBD_HR_RSSILevel10: start 368, 8 bit, little-endian, data-type-policy=OVERRIDE, base-type=uint8, compu {phys=raw; unit dB}, range phys 0..252
          signal ResultBLEConMonitoringFBD_HR_connEventCounter10: start 376, 16 bit, little-endian, data-type-policy=OVERRIDE, base-type=uint16, compu {phys=raw}, range phys 0..65532
          signal ResultBLEConMonitoringFBD_HR_Ch_Num10: start 392, 8 bit, little-endian, data-type-policy=OVERRIDE, base-type=uint8, compu {phys=raw}, range phys 0..252
          signal ResultBLEConMonitoringFBD_HR_Ch_qual10: start 400, 8 bit, little-endian, data-type-policy=OVERRIDE, base-type=uint8, compu {phys=raw}, range phys 0..252
          signal ResultBLEConMonitoringFBD_HR_IV00: start 408, 8 bit, little-endian, data-type-policy=OVERRIDE, base-type=uint8, compu {phys=raw}, range phys 0..255
          signal ResultBLEConMonitoringFBD_HR_IV01: start 416, 8 bit, little-endian, data-type-policy=OVERRIDE, base-type=uint8, compu {phys=raw}, range phys 0..255
          signal ResultBLEConMonitoringFBD_HR_IV02: start 424, 8 bit, little-endian, data-type-policy=OVERRIDE, base-type=uint8, compu {phys=raw}, range phys 0..255
          signal ResultBLEConMonitoringFBD_HR_IV03: start 432, 8 bit, little-endian, data-type-policy=OVERRIDE, base-type=uint8, compu {phys=raw}, range phys 0..255
          signal ResultBLEConMonitoringFBD_HR_Sign00: start 440, 8 bit, little-endian, data-type-policy=OVERRIDE, base-type=uint8, compu {phys=raw}, range phys 0..255
          signal ResultBLEConMonitoringFBD_HR_Sign01: start 448, 8 bit, little-endian, data-type-policy=OVERRIDE, base-type=uint8, compu {phys=raw}, range phys 0..255
          signal ResultBLEConMonitoringFBD_HR_Sign02: start 456, 8 bit, little-endian, data-type-policy=OVERRIDE, base-type=uint8, compu {phys=raw}, range phys 0..255
          signal ResultBLEConMonitoringFBD_HR_Sign03: start 464, 8 bit, little-endian, data-type-policy=OVERRIDE, base-type=uint8, compu {phys=raw}, range phys 0..255
          signal ResultBLEConMonitoringFBD_HR_Sign04: start 472, 8 bit, little-endian, data-type-policy=OVERRIDE, base-type=uint8, compu {phys=raw}, range phys 0..255
          signal ResultBLEConMonitoringFBD_HR_Sign05: start 480, 8 bit, little-endian, data-type-policy=OVERRIDE, base-type=uint8, compu {phys=raw}, range phys 0..255
          signal ResultBLEConMonitoringFBD_HR_Sign06: start 488, 8 bit, little-endian, data-type-policy=OVERRIDE, base-type=uint8, compu {phys=raw}, range phys 0..255
          signal ResultBLEConMonitoringFBD_HR_Sign07: start 496, 8 bit, little-endian, data-type-policy=OVERRIDE, base-type=uint8, compu {phys=raw}, range phys 0..255
      frame ResultBLEConMonitoringFBD_Miko: id 0x124, frame-length=64, can-addressing-mode=STANDARD, can-frame-rx-behavior=CAN-FD, can-frame-tx-behavior=CAN-FD
        pdu ResultBLEConMonitoringFBD_Miko: length=64, unused-bit-pattern=0
          signal ResultBLEConMonitoringFBD_Miko_IRKListID: start 0, 8 bit, little-endian, data-type-policy=OVERRIDE, base-type=uint8, compu {phys=raw}, range phys 0..252
          signal ResultBLEConMonitoringFBD_Miko_RSSILevel01: start 8, 8 bit, little-endian, data-type-policy=OVERRIDE, base-type=uint8, compu {phys=raw; unit dB}, range phys 0..252
          signal ResultBLEConMonitoringFBD_Miko_connEventCounter01: start 16, 16 bit, little-endian, data-type-policy=OVERRIDE, base-type=uint16, compu {phys=raw}, range phys 0..65532
          signal ResultBLEConMonitoringFBD_Miko_Ch_Num01: start 32, 8 bit, little-endian, data-type-policy=OVERRIDE, base-type=uint8, compu {phys=raw}, range phys 0..252
          signal ResultBLEConMonitoringFBD_Miko_Dev_TxPower: start 40, 8 bit, little-endian, data-type-policy=OVERRIDE, base-type=uint8, compu {phys=raw}, range phys 0..252
          signal ResultBLEConMonitoringFBD_Miko_RSSILevel02: start 48, 8 bit, little-endian, data-type-policy=OVERRIDE, base-type=uint8, compu {phys=raw; unit dB}, range phys 0..252
          signal ResultBLEConMonitoringFBD_Miko_connEventCounter02: start 56, 16 bit, little-endian, data-type-policy=OVERRIDE, base-type=uint16, compu {phys=raw}, range phys 0..65532
          signal ResultBLEConMonitoringFBD_Miko_Ch_Num02: start 72, 8 bit, little-endian, data-type-policy=OVERRIDE, base-type=uint8, compu {phys=raw}, range phys 0..252
          signal ResultBLEConMonitoringFBD_Miko_Ch_qual02: start 80, 8 bit, little-endian, data-type-policy=OVERRIDE, base-type=uint8, compu {phys=raw}, range phys 0..252
          signal ResultBLEConMonitoringFBD_Miko_RSSILevel03: start 88, 8 bit, little-endian, data-type-policy=OVERRIDE, base-type=uint8, compu {phys=raw; unit dB}, range phys 0..252
          signal ResultBLEConMonitoringFBD_Miko_connEventCounter03: start 96, 16 bit, little-endian, data-type-policy=OVERRIDE, base-type=uint16, compu {phys=raw}, range phys 0..65532
          signal ResultBLEConMonitoringFBD_Miko_Ch_Num03: start 112, 8 bit, little-endian, data-type-policy=OVERRIDE, base-type=uint8, compu {phys=raw}, range phys 0..252
          signal ResultBLEConMonitoringFBD_Miko_Ch_qual03: start 120, 8 bit, little-endian, data-type-policy=OVERRIDE, base-type=uint8, compu {phys=raw}, range phys 0..252
          signal ResultBLEConMonitoringFBD_Miko_RSSILevel04: start 128, 8 bit, little-endian, data-type-policy=OVERRIDE, base-type=uint8, compu {phys=raw; unit dB}, range phys 0..252
          signal ResultBLEConMonitoringFBD_Miko_connEventCounter04: start 136, 16 bit, little-endian, data-type-policy=OVERRIDE, base-type=uint16, compu {phys=raw}, range phys 0..65532
          signal ResultBLEConMonitoringFBD_Miko_Ch_Num04: start 152, 8 bit, little-endian, data-type-policy=OVERRIDE, base-type=uint8, compu {phys=raw}, range phys 0..252
          signal ResultBLEConMonitoringFBD_Miko_Ch_qual04: start 160, 8 bit, little-endian, data-type-policy=OVERRIDE, base-type=uint8, compu {phys=raw}, range phys 0..252
          signal ResultBLEConMonitoringFBD_Miko_RSSILevel05: start 168, 8 bit, little-endian, data-type-policy=OVERRIDE, base-type=uint8, compu {phys=raw; unit dB}, range phys 0..252
          signal ResultBLEConMonitoringFBD_Miko_connEventCounter05: start 176, 16 bit, little-endian, data-type-policy=OVERRIDE, base-type=uint16, compu {phys=raw}, range phys 0..65532
          signal ResultBLEConMonitoringFBD_Miko_Ch_Num05: start 192, 8 bit, little-endian, data-type-policy=OVERRIDE, base-type=uint8, compu {phys=raw}, range phys 0..252
          signal ResultBLEConMonitoringFBD_Miko_Ch_qual05: start 200, 8 bit, little-endian, data-type-policy=OVERRIDE, base-type=uint8, compu {phys=raw}, range phys 0..252
          signal ResultBLEConMonitoringFBD_Miko_RSSILevel06: start 208, 8 bit, little-endian, data-type-policy=OVERRIDE, base-type=uint8, compu {phys=raw; unit dB}, range phys 0..252
          signal ResultBLEConMonitoringFBD_Miko_connEventCounter06: start 216, 16 bit, little-endian, data-type-policy=OVERRIDE, base-type=uint16, compu {phys=raw}, range phys 0..65532
          signal ResultBLEConMonitoringFBD_Miko_Ch_Num06: start 232, 8 bit, little-endian, data-type-policy=OVERRIDE, base-type=uint8, compu {phys=raw}, range phys 0..252
          signal ResultBLEConMonitoringFBD_Miko_Ch_qual06: start 240, 8 bit, little-endian, data-type-policy=OVERRIDE, base-type=uint8, compu {phys=raw}, range phys 0..252
          signal ResultBLEConMonitoringFBD_Miko_RSSILevel07: start 248, 8 bit, little-endian, data-type-policy=OVERRIDE, base-type=uint8, compu {phys=raw; unit dB}, range phys 0..252
          signal ResultBLEConMonitoringFBD_Miko_connEventCounter07: start 256, 16 bit, little-endian, data-type-policy=OVERRIDE, base-type=uint16, compu {phys=raw}, range phys 0..65532
          signal ResultBLEConMonitoringFBD_Miko_Ch_Num07: start 272, 8 bit, little-endian, data-type-policy=OVERRIDE, base-type=uint8, compu {phys=raw}, range phys 0..252
          signal ResultBLEConMonitoringFBD_Miko_Ch_qual07: start 280, 8 bit, little-endian, data-type-policy=OVERRIDE, base-type=uint8, compu {phys=raw}, range phys 0..252
          signal ResultBLEConMonitoringFBD_Miko_RSSILevel08: start 288, 8 bit, little-endian, data-type-policy=OVERRIDE, base-type=uint8, compu {phys=raw; unit dB}, range phys 0..252
          signal ResultBLEConMonitoringFBD_Miko_connEventCounter08: start 296, 16 bit, little-endian, data-type-policy=OVERRIDE, base-type=uint16, compu {phys=raw}, range phys 0..65532
          signal ResultBLEConMonitoringFBD_Miko_Ch_Num08: start 312, 8 bit, little-endian, data-type-policy=OVERRIDE, base-type=uint8, compu {phys=raw}, range phys 0..252
          signal ResultBLEConMonitoringFBD_Miko_Ch_qual08: start 320, 8 bit, little-endian, data-type-policy=OVERRIDE, base-type=uint8, compu {phys=raw}, range phys 0..252
          signal ResultBLEConMonitoringFBD_Miko_RSSILevel09: start 328, 8 bit, little-endian, data-type-policy=OVERRIDE, base-type=uint8, compu {phys=raw; unit dB}, range phys 0..252
          signal ResultBLEConMonitoringFBD_Miko_connEventCounter09: start 336, 16 bit, little-endian, data-type-policy=OVERRIDE, base-type=uint16, compu {phys=raw}, range phys 0..65532
          signal ResultBLEConMonitoringFBD_Miko_Ch_Num09: start 352, 8 bit, little-endian, data-type-policy=OVERRIDE, base-type=uint8, compu {phys=raw}, range phys 0..252
          signal ResultBLEConMonitoringFBD_Miko_Ch_qual09: start 360, 8 bit, little-endian, data-type-policy=OVERRIDE, base-type=uint8, compu {phys=raw}, range phys 0..252
          signal ResultBLEConMonitoringFBD_Miko_RSSILevel10: start 368, 8 bit, little-endian, data-type-policy=OVERRIDE, base-type=uint8, compu {phys=raw; unit dB}, range phys 0..252
          signal ResultBLEConMonitoringFBD_Miko_connEventCounter10: start 376, 16 bit, little-endian, data-type-policy=OVERRIDE, base-type=uint16, compu {phys=raw}, range phys 0..65532
          signal ResultBLEConMonitoringFBD_Miko_Ch_Num10: start 392, 8 bit, little-endian, data-type-policy=OVERRIDE, base-type=uint8, compu {phys=raw}, range phys 0..252
          signal ResultBLEConMonitoringFBD_Miko_Ch_qual10: start 400, 8 bit, little-endian, data-type-policy=OVERRIDE, base-type=uint8, compu {phys=raw}, range phys 0..252
          signal ResultBLEConMonitoringFBD_Miko_IV00: start 408, 8 bit, little-endian, data-type-policy=OVERRIDE, base-type=uint8, compu {phys=raw}, range phys 0..255
          signal ResultBLEConMonitoringFBD_Miko_IV01: start 416, 8 bit, little-endian, data-type-policy=OVERRIDE, base-type=uint8, compu {phys=raw}, range phys 0..255
          signal ResultBLEConMonitoringFBD_Miko_IV02: start 424, 8 bit, little-endian, data-type-policy=OVERRIDE, base-type=uint8, compu {phys=raw}, range phys 0..255
          signal ResultBLEConMonitoringFBD_Miko_IV03: start 432, 8 bit, little-endian, data-type-policy=OVERRIDE, base-type=uint8, compu {phys=raw}, range phys 0..255
          signal ResultBLEConMonitoringFBD_Miko_Sign00: start 440, 8 bit, little-endian, data-type-policy=OVERRIDE, base-type=uint8, compu {phys=raw}, range phys 0..255
          signal ResultBLEConMonitoringFBD_Miko_Sign01: start 448, 8 bit, little-endian, data-type-policy=OVERRIDE, base-type=uint8, compu {phys=raw}, range phys 0..255
          signal ResultBLEConMonitoringFBD_Miko_Sign02: start 456, 8 bit, little-endian, data-type-policy=OVERRIDE, base-type=uint8, compu {phys=raw}, range phys 0..255
          signal ResultBLEConMonitoringFBD_Miko_Sign03: start 464, 8 bit, little-endian, data-type-policy=OVERRIDE, base-type=uint8, compu {phys=raw}, range phys 0..255
          signal ResultBLEConMonitoringFBD_Miko_Sign04: start 472, 8 bit, little-endian, data-type-policy=OVERRIDE, base-type=uint8, compu {phys=raw}, range phys 0..255
          signal ResultBLEConMonitoringFBD_Miko_Sign05: start 480, 8 bit, little-endian, data-type-policy=OVERRIDE, base-type=uint8, compu {phys=raw}, range phys 0..255
          signal ResultBLEConMonitoringFBD_Miko_Sign06: start 488, 8 bit, little-endian, data-type-policy=OVERRIDE, base-type=uint8, compu {phys=raw}, range phys 0..255
          signal ResultBLEConMonitoringFBD_Miko_Sign07: start 496, 8 bit, little-endian, data-type-policy=OVERRIDE, base-type=uint8, compu {phys=raw}, range phys 0..255
      frame ResultBLEConMonitoringFBD_MM: id 0x339, frame-length=64, can-addressing-mode=STANDARD, can-frame-rx-behavior=CAN-FD, can-frame-tx-behavior=CAN-FD
        pdu ResultBLEConMonitoringFBD_MM: length=64, unused-bit-pattern=0
          signal ResultBLEConMonitoringFBD_MM_IRKListID: start 0, 8 bit, little-endian, data-type-policy=OVERRIDE, base-type=uint8, compu {phys=raw}, range phys 0..252
          signal ResultBLEConMonitoringFBD_MM_RSSILevel01: start 8, 8 bit, little-endian, data-type-policy=OVERRIDE, base-type=uint8, compu {phys=raw; unit dB}, range phys 0..252
          signal ResultBLEConMonitoringFBD_MM_connEventCounter01: start 16, 16 bit, little-endian, data-type-policy=OVERRIDE, base-type=uint16, compu {phys=raw}, range phys 0..65532
          signal ResultBLEConMonitoringFBD_MM_Ch_Num01: start 32, 8 bit, little-endian, data-type-policy=OVERRIDE, base-type=uint8, compu {phys=raw}, range phys 0..252
          signal ResultBLEConMonitoringFBD_MM_Dev_TxPower: start 40, 8 bit, little-endian, data-type-policy=OVERRIDE, base-type=uint8, compu {phys=raw}, range phys 0..252
          signal ResultBLEConMonitoringFBD_MM_RSSILevel02: start 48, 8 bit, little-endian, data-type-policy=OVERRIDE, base-type=uint8, compu {phys=raw; unit dB}, range phys 0..252
          signal ResultBLEConMonitoringFBD_MM_connEventCounter02: start 56, 16 bit, little-endian, data-type-policy=OVERRIDE, base-type=uint16, compu {phys=raw}, range phys 0..65532
          signal ResultBLEConMonitoringFBD_MM_Ch_Num02: start 72, 8 bit, little-endian, data-type-policy=OVERRIDE, base-type=uint8, compu {phys=raw}, range phys 0..252
          signal ResultBLEConMonitoringFBD_MM_Ch_qual02: start 80, 8 bit, little-endian, data-type-policy=OVERRIDE, base-type=uint8, compu {phys=raw}, range phys 0..252
          signal ResultBLEConMonitoringFBD_MM_RSSILevel03: start 88, 8 bit, little-endian, data-type-policy=OVERRIDE, base-type=uint8, compu {phys=raw; unit dB}, range phys 0..252
          signal ResultBLEConMonitoringFBD_MM_connEventCounter03: start 96, 16 bit, little-endian, data-type-policy=OVERRIDE, base-type=uint16, compu {phys=raw}, range phys 0..65532
          signal ResultBLEConMonitoringFBD_MM_Ch_Num03: start 112, 8 bit, little-endian, data-type-policy=OVERRIDE, base-type=uint8, compu {phys=raw}, range phys 0..252
          signal ResultBLEConMonitoringFBD_MM_Ch_qual03: start 120, 8 bit, little-endian, data-type-policy=OVERRIDE, base-type=uint8, compu {phys=raw}, range phys 0..252
          signal ResultBLEConMonitoringFBD_MM_RSSILevel04: start 128, 8 bit, little-endian, data-type-policy=OVERRIDE, base-type=uint8, compu {phys=raw; unit dB}, range phys 0..252
          signal ResultBLEConMonitoringFBD_MM_connEventCounter04: start 136, 16 bit, little-endian, data-type-policy=OVERRIDE, base-type=uint16, compu {phys=raw}, range phys 0..65532
          signal ResultBLEConMonitoringFBD_MM_Ch_Num04: start 152, 8 bit, little-endian, data-type-policy=OVERRIDE, base-type=uint8, compu {phys=raw}, range phys 0..252
          signal ResultBLEConMonitoringFBD_MM_Ch_qual04: start 160, 8 bit, little-endian, data-type-policy=OVERRIDE, base-type=uint8, compu {phys=raw}, range phys 0..252
          signal ResultBLEConMonitoringFBD_MM_RSSILevel05: start 168, 8 bit, little-endian, data-type-policy=OVERRIDE, base-type=uint8, compu {phys=raw; unit dB}, range phys 0..252
          signal ResultBLEConMonitoringFBD_MM_connEventCounter05: start 176, 16 bit, little-endian, data-type-policy=OVERRIDE, base-type=uint16, compu {phys=raw}, range phys 0..65532
          signal ResultBLEConMonitoringFBD_MM_Ch_Num05: start 192, 8 bit, little-endian, data-type-policy=OVERRIDE, base-type=uint8, compu {phys=raw}, range phys 0..252
          signal ResultBLEConMonitoringFBD_MM_Ch_qual05: start 200, 8 bit, little-endian, data-type-policy=OVERRIDE, base-type=uint8, compu {phys=raw}, range phys 0..252
          signal ResultBLEConMonitoringFBD_MM_RSSILevel06: start 208, 8 bit, little-endian, data-type-policy=OVERRIDE, base-type=uint8, compu {phys=raw; unit dB}, range phys 0..252
          signal ResultBLEConMonitoringFBD_MM_connEventCounter06: start 216, 16 bit, little-endian, data-type-policy=OVERRIDE, base-type=uint16, compu {phys=raw}, range phys 0..65532
          signal ResultBLEConMonitoringFBD_MM_Ch_Num06: start 232, 8 bit, little-endian, data-type-policy=OVERRIDE, base-type=uint8, compu {phys=raw}, range phys 0..252
          signal ResultBLEConMonitoringFBD_MM_Ch_qual06: start 240, 8 bit, little-endian, data-type-policy=OVERRIDE, base-type=uint8, compu {phys=raw}, range phys 0..252
          signal ResultBLEConMonitoringFBD_MM_RSSILevel07: start 248, 8 bit, little-endian, data-type-policy=OVERRIDE, base-type=uint8, compu {phys=raw; unit dB}, range phys 0..252
          signal ResultBLEConMonitoringFBD_MM_connEventCounter07: start 256, 16 bit, little-endian, data-type-policy=OVERRIDE, base-type=uint16, compu {phys=raw}, range phys 0..65532
          signal ResultBLEConMonitoringFBD_MM_Ch_Num07: start 272, 8 bit, little-endian, data-type-policy=OVERRIDE, base-type=uint8, compu {phys=raw}, range phys 0..252
          signal ResultBLEConMonitoringFBD_MM_Ch_qual07: start 280, 8 bit, little-endian, data-type-policy=OVERRIDE, base-type=uint8, compu {phys=raw}, range phys 0..252
          signal ResultBLEConMonitoringFBD_MM_RSSILevel08: start 288, 8 bit, little-endian, data-type-policy=OVERRIDE, base-type=uint8, compu {phys=raw; unit dB}, range phys 0..252
          signal ResultBLEConMonitoringFBD_MM_connEventCounter08: start 296, 16 bit, little-endian, data-type-policy=OVERRIDE, base-type=uint16, compu {phys=raw}, range phys 0..65532
          signal ResultBLEConMonitoringFBD_MM_Ch_Num08: start 312, 8 bit, little-endian, data-type-policy=OVERRIDE, base-type=uint8, compu {phys=raw}, range phys 0..252
          signal ResultBLEConMonitoringFBD_MM_Ch_qual08: start 320, 8 bit, little-endian, data-type-policy=OVERRIDE, base-type=uint8, compu {phys=raw}, range phys 0..252
          signal ResultBLEConMonitoringFBD_MM_RSSILevel09: start 328, 8 bit, little-endian, data-type-policy=OVERRIDE, base-type=uint8, compu {phys=raw; unit dB}, range phys 0..252
          signal ResultBLEConMonitoringFBD_MM_connEventCounter09: start 336, 16 bit, little-endian, data-type-policy=OVERRIDE, base-type=uint16, compu {phys=raw}, range phys 0..65532
          signal ResultBLEConMonitoringFBD_MM_Ch_Num09: start 352, 8 bit, little-endian, data-type-policy=OVERRIDE, base-type=uint8, compu {phys=raw}, range phys 0..252
          signal ResultBLEConMonitoringFBD_MM_Ch_qual09: start 360, 8 bit, little-endian, data-type-policy=OVERRIDE, base-type=uint8, compu {phys=raw}, range phys 0..252
          signal ResultBLEConMonitoringFBD_MM_RSSILevel10: start 368, 8 bit, little-endian, data-type-policy=OVERRIDE, base-type=uint8, compu {phys=raw; unit dB}, range phys 0..252
          signal ResultBLEConMonitoringFBD_MM_connEventCounter10: start 376, 16 bit, little-endian, data-type-policy=OVERRIDE, base-type=uint16, compu {phys=raw}, range phys 0..65532
          signal ResultBLEConMonitoringFBD_MM_Ch_Num10: start 392, 8 bit, little-endian, data-type-policy=OVERRIDE, base-type=uint8, compu {phys=raw}, range phys 0..252
          signal ResultBLEConMonitoringFBD_MM_Ch_qual10: start 400, 8 bit, little-endian, data-type-policy=OVERRIDE, base-type=uint8, compu {phys=raw}, range phys 0..252
          signal ResultBLEConMonitoringFBD_MM_IV00: start 408, 8 bit, little-endian, data-type-policy=OVERRIDE, base-type=uint8, compu {phys=raw}, range phys 0..255
          signal ResultBLEConMonitoringFBD_MM_IV01: start 416, 8 bit, little-endian, data-type-policy=OVERRIDE, base-type=uint8, compu {phys=raw}, range phys 0..255
          signal ResultBLEConMonitoringFBD_MM_IV02: start 424, 8 bit, little-endian, data-type-policy=OVERRIDE, base-type=uint8, compu {phys=raw}, range phys 0..255
          signal ResultBLEConMonitoringFBD_MM_IV03: start 432, 8 bit, little-endian, data-type-policy=OVERRIDE, base-type=uint8, compu {phys=raw}, range phys 0..255
          signal ResultBLEConMonitoringFBD_MM_Sign00: start 440, 8 bit, little-endian, data-type-policy=OVERRIDE, base-type=uint8, compu {phys=raw}, range phys 0..255
          signal ResultBLEConMonitoringFBD_MM_Sign01: start 448, 8 bit, little-endian, data-type-policy=OVERRIDE, base-type=uint8, compu {phys=raw}, range phys 0..255
          signal ResultBLEConMonitoringFBD_MM_Sign02: start 456, 8 bit, little-endian, data-type-policy=OVERRIDE, base-type=uint8, compu {phys=raw}, range phys 0..255
          signal ResultBLEConMonitoringFBD_MM_Sign03: start 464, 8 bit, little-endian, data-type-policy=OVERRIDE, base-type=uint8, compu {phys=raw}, range phys 0..255
          signal ResultBLEConMonitoringFBD_MM_Sign04: start 472, 8 bit, little-endian, data-type-policy=OVERRIDE, base-type=uint8, compu {phys=raw}, range phys 0..255
          signal ResultBLEConMonitoringFBD_MM_Sign05: start 480, 8 bit, little-endian, data-type-policy=OVERRIDE, base-type=uint8, compu {phys=raw}, range phys 0..255
          signal ResultBLEConMonitoringFBD_MM_Sign06: start 488, 8 bit, little-endian, data-type-policy=OVERRIDE, base-type=uint8, compu {phys=raw}, range phys 0..255
          signal ResultBLEConMonitoringFBD_MM_Sign07: start 496, 8 bit, little-endian, data-type-policy=OVERRIDE, base-type=uint8, compu {phys=raw}, range phys 0..255
      frame ResultBLEConMonitoringFBD_Trunk: id 0x125, frame-length=64, can-addressing-mode=STANDARD, can-frame-rx-behavior=CAN-FD, can-frame-tx-behavior=CAN-FD
        pdu ResultBLEConMonitoringFBD_Trunk: length=64, unused-bit-pattern=0
          signal ResultBLEConMonitoringFBD_Trunk_IRKListID: start 0, 8 bit, little-endian, data-type-policy=OVERRIDE, base-type=uint8, compu {phys=raw}, range phys 0..252
          signal ResultBLEConMonitoringFBD_Trunk_RSSILevel01: start 8, 8 bit, little-endian, data-type-policy=OVERRIDE, base-type=uint8, compu {phys=raw; unit dB}, range phys 0..252
          signal ResultBLEConMonitoringFBD_Trunk_connEventCounter01: start 16, 16 bit, little-endian, data-type-policy=OVERRIDE, base-type=uint16, compu {phys=raw}, range phys 0..65532
          signal ResultBLEConMonitoringFBD_Trunk_Ch_Num01: start 32, 8 bit, little-endian, data-type-policy=OVERRIDE, base-type=uint8, compu {phys=raw}, range phys 0..252
          signal ResultBLEConMonitoringFBD_Tunk_Dev_TxPower: start 40, 8 bit, little-endian, data-type-policy=OVERRIDE, base-type=uint8, compu {phys=raw}, range phys 0..252
          signal ResultBLEConMonitoringFBD_Trunk_RSSILevel02: start 48, 8 bit, little-endian, data-type-policy=OVERRIDE, base-type=uint8, compu {phys=raw; unit dB}, range phys 0..252
          signal ResultBLEConMonitoringFBD_Trunk_connEventCounter02: start 56, 16 bit, little-endian, data-type-policy=OVERRIDE, base-type=uint16, compu {phys=raw}, range phys 0..65532
          signal ResultBLEConMonitoringFBD_Trunk_Ch_Num02: start 72, 8 bit, little-endian, data-type-policy=OVERRIDE, base-type=uint8, compu {phys=raw}, range phys 0..252
          signal ResultBLEConMonitoringFBD_Trunk_Ch_qual02: start 80, 8 bit, little-endian, data-type-policy=OVERRIDE, base-type=uint8, compu {phys=raw}, range phys 0..252
          signal ResultBLEConMonitoringFBD_Trunk_RSSILevel03: start 88, 8 bit, little-endian, data-type-policy=OVERRIDE, base-type=uint8, compu {phys=raw; unit dB}, range phys 0..252
          signal ResultBLEConMonitoringFBD_Trunk_connEventCounter03: start 96, 16 bit, little-endian, data-type-policy=OVERRIDE, base-type=uint16, compu {phys=raw}, range phys 0..65532
          signal ResultBLEConMonitoringFBD_Trunk_Ch_Num03: start 112, 8 bit, little-endian, data-type-policy=OVERRIDE, base-type=uint8, compu {phys=raw}, range phys 0..252
          signal ResultBLEConMonitoringFBD_Trunk_Ch_qual03: start 120, 8 bit, little-endian, data-type-policy=OVERRIDE, base-type=uint8, compu {phys=raw}, range phys 0..252
          signal ResultBLEConMonitoringFBD_Trunk_RSSILevel04: start 128, 8 bit, little-endian, data-type-policy=OVERRIDE, base-type=uint8, compu {phys=raw; unit dB}, range phys 0..252
          signal ResultBLEConMonitoringFBD_Trunk_connEventCounter04: start 136, 16 bit, little-endian, data-type-policy=OVERRIDE, base-type=uint16, compu {phys=raw}, range phys 0..65532
          signal ResultBLEConMonitoringFBD_Trunk_Ch_Num04: start 152, 8 bit, little-endian, data-type-policy=OVERRIDE, base-type=uint8, compu {phys=raw}, range phys 0..252
          signal ResultBLEConMonitoringFBD_Trunk_Ch_qual04: start 160, 8 bit, little-endian, data-type-policy=OVERRIDE, base-type=uint8, compu {phys=raw}, range phys 0..252
          signal ResultBLEConMonitoringFBD_Trunk_RSSILevel05: start 168, 8 bit, little-endian, data-type-policy=OVERRIDE, base-type=uint8, compu {phys=raw; unit dB}, range phys 0..252
          signal ResultBLEConMonitoringFBD_Trunk_connEventCounter05: start 176, 16 bit, little-endian, data-type-policy=OVERRIDE, base-type=uint16, compu {phys=raw}, range phys 0..65532
          signal ResultBLEConMonitoringFBD_Trunk_Ch_Num05: start 192, 8 bit, little-endian, data-type-policy=OVERRIDE, base-type=uint8, compu {phys=raw}, range phys 0..252
          signal ResultBLEConMonitoringFBD_Trunk_Ch_qual05: start 200, 8 bit, little-endian, data-type-policy=OVERRIDE, base-type=uint8, compu {phys=raw}, range phys 0..252
          signal ResultBLEConMonitoringFBD_Trunk_RSSILevel06: start 208, 8 bit, little-endian, data-type-policy=OVERRIDE, base-type=uint8, compu {phys=raw; unit dB}, range phys 0..252
          signal ResultBLEConMonitoringFBD_Trunk_connEventCounter06: start 216, 16 bit, little-endian, data-type-policy=OVERRIDE, base-type=uint16, compu {phys=raw}, range phys 0..65532
          signal ResultBLEConMonitoringFBD_Trunk_Ch_Num06: start 232, 8 bit, little-endian, data-type-policy=OVERRIDE, base-type=uint8, compu {phys=raw}, range phys 0..252
          signal ResultBLEConMonitoringFBD_Trunk_Ch_qual06: start 240, 8 bit, little-endian, data-type-policy=OVERRIDE, base-type=uint8, compu {phys=raw}, range phys 0..252
          signal ResultBLEConMonitoringFBD_Trunk_RSSILevel07: start 248, 8 bit, little-endian, data-type-policy=OVERRIDE, base-type=uint8, compu {phys=raw; unit dB}, range phys 0..252
          signal ResultBLEConMonitoringFBD_Trunk_connEventCounter07: start 256, 16 bit, little-endian, data-type-policy=OVERRIDE, base-type=uint16, compu {phys=raw}, range phys 0..65532
          signal ResultBLEConMonitoringFBD_Trunk_Ch_Num07: start 272, 8 bit, little-endian, data-type-policy=OVERRIDE, base-type=uint8, compu {phys=raw}, range phys 0..252
          signal ResultBLEConMonitoringFBD_Trunk_Ch_qual07: start 280, 8 bit, little-endian, data-type-policy=OVERRIDE, base-type=uint8, compu {phys=raw}, range phys 0..252
          signal ResultBLEConMonitoringFBD_Trunk_RSSILevel08: start 288, 8 bit, little-endian, data-type-policy=OVERRIDE, base-type=uint8, compu {phys=raw; unit dB}, range phys 0..252
          signal ResultBLEConMonitoringFBD_Trunk_connEventCounter08: start 296, 16 bit, little-endian, data-type-policy=OVERRIDE, base-type=uint16, compu {phys=raw}, range phys 0..65532
          signal ResultBLEConMonitoringFBD_Trunk_Ch_Num08: start 312, 8 bit, little-endian, data-type-policy=OVERRIDE, base-type=uint8, compu {phys=raw}, range phys 0..252
          signal ResultBLEConMonitoringFBD_Trunk_Ch_qual08: start 320, 8 bit, little-endian, data-type-policy=OVERRIDE, base-type=uint8, compu {phys=raw}, range phys 0..252
          signal ResultBLEConMonitoringFBD_Trunk_RSSILevel09: start 328, 8 bit, little-endian, data-type-policy=OVERRIDE, base-type=uint8, compu {phys=raw; unit dB}, range phys 0..252
          signal ResultBLEConMonitoringFBD_Trunk_connEventCounter09: start 336, 16 bit, little-endian, data-type-policy=OVERRIDE, base-type=uint16, compu {phys=raw}, range phys 0..65532
          signal ResultBLEConMonitoringFBD_Trunk_Ch_Num09: start 352, 8 bit, little-endian, data-type-policy=OVERRIDE, base-type=uint8, compu {phys=raw}, range phys 0..252
          signal ResultBLEConMonitoringFBD_Trunk_Ch_qual09: start 360, 8 bit, little-endian, data-type-policy=OVERRIDE, base-type=uint8, compu {phys=raw}, range phys 0..252
          signal ResultBLEConMonitoringFBD_Trunk_RSSILevel10: start 368, 8 bit, little-endian, data-type-policy=OVERRIDE, base-type=uint8, compu {phys=raw; unit dB}, range phys 0..252
          signal ResultBLEConMonitoringFBD_Trunk_connEventCounter10: start 376, 16 bit, little-endian, data-type-policy=OVERRIDE, base-type=uint16, compu {phys=raw}, range phys 0..65532
          signal ResultBLEConMonitoringFBD_Trunk_Ch_Num10: start 392, 8 bit, little-endian, data-type-policy=OVERRIDE, base-type=uint8, compu {phys=raw}, range phys 0..252
          signal ResultBLEConMonitoringFBD_Trunk_Ch_qual10: start 400, 8 bit, little-endian, data-type-policy=OVERRIDE, base-type=uint8, compu {phys=raw}, range phys 0..252
          signal ResultBLEConMonitoringFBD_Trunk_IV00: start 408, 8 bit, little-endian, data-type-policy=OVERRIDE, base-type=uint8, compu {phys=raw}, range phys 0..255
          signal ResultBLEConMonitoringFBD_Trunk_IV01: start 416, 8 bit, little-endian, data-type-policy=OVERRIDE, base-type=uint8, compu {phys=raw}, range phys 0..255
          signal ResultBLEConMonitoringFBD_Trunk_IV02: start 424, 8 bit, little-endian, data-type-policy=OVERRIDE, base-type=uint8, compu {phys=raw}, range phys 0..255
          signal ResultBLEConMonitoringFBD_Trunk_IV03: start 432, 8 bit, little-endian, data-type-policy=OVERRIDE, base-type=uint8, compu {phys=raw}, range phys 0..255
          signal ResultBLEConMonitoringFBD_Trunk_Sign00: start 440, 8 bit, little-endian, data-type-policy=OVERRIDE, base-type=uint8, compu {phys=raw}, range phys 0..255
          signal ResultBLEConMonitoringFBD_Trunk_Sign01: start 448, 8 bit, little-endian, data-type-policy=OVERRIDE, base-type=uint8, compu {phys=raw}, range phys 0..255
          signal ResultBLEConMonitoringFBD_Trunk_Sign02: start 456, 8 bit, little-endian, data-type-policy=OVERRIDE, base-type=uint8, compu {phys=raw}, range phys 0..255
          signal ResultBLEConMonitoringFBD_Trunk_Sign03: start 464, 8 bit, little-endian, data-type-policy=OVERRIDE, base-type=uint8, compu {phys=raw}, range phys 0..255
          signal ResultBLEConMonitoringFBD_Trunk_Sign04: start 472, 8 bit, little-endian, data-type-policy=OVERRIDE, base-type=uint8, compu {phys=raw}, range phys 0..255
          signal ResultBLEConMonitoringFBD_Trunk_Sign05: start 480, 8 bit, little-endian, data-type-policy=OVERRIDE, base-type=uint8, compu {phys=raw}, range phys 0..255
          signal ResultBLEConMonitoringFBD_Trunk_Sign06: start 488, 8 bit, little-endian, data-type-policy=OVERRIDE, base-type=uint8, compu {phys=raw}, range phys 0..255
          signal ResultBLEConMonitoringFBD_Trunk_Sign07: start 496, 8 bit, little-endian, data-type-policy=OVERRIDE, base-type=uint8, compu {phys=raw}, range phys 0..255
      frame ResultBLEConMonitoringFBD_VL: id 0x126, frame-length=64, can-addressing-mode=STANDARD, can-frame-rx-behavior=CAN-FD, can-frame-tx-behavior=CAN-FD
        pdu ResultBLEConMonitoringFBD_VL: length=64, unused-bit-pattern=0
          signal ResultBLEConMonitoringFBD_VL_IRKListID: start 0, 8 bit, little-endian, data-type-policy=OVERRIDE, base-type=uint8, compu {phys=raw}, range phys 0..252
          signal ResultBLEConMonitoringFBD_VL_RSSILevel01: start 8, 8 bit, little-endian, data-type-policy=OVERRIDE, base-type=uint8, compu {phys=raw; unit dB}, range phys 0..252
          signal ResultBLEConMonitoringFBD_VL_connEventCounter01: start 16, 16 bit, little-endian, data-type-policy=OVERRIDE, base-type=uint16, compu {phys=raw}, range phys 0..65532
          signal ResultBLEConMonitoringFBD_VL_Ch_Num01: start 32, 8 bit, little-endian, data-type-policy=OVERRIDE, base-type=uint8, compu {phys=raw}, range phys 0..252
          signal ResultBLEConMonitoringFBD_VL_Dev_TxPower: start 40, 8 bit, little-endian, data-type-policy=OVERRIDE, base-type=uint8, compu {phys=raw}, range phys 0..252
          signal ResultBLEConMonitoringFBD_VL_RSSILevel02: start 48, 8 bit, little-endian, data-type-policy=OVERRIDE, base-type=uint8, compu {phys=raw; unit dB}, range phys 0..252
          signal ResultBLEConMonitoringFBD_VL_connEventCounter02: start 56, 16 bit, little-endian, data-type-policy=OVERRIDE, base-type=uint16, compu {phys=raw}, range phys 0..65532
          signal ResultBLEConMonitoringFBD_VL_Ch_Num02: start 72, 8 bit, little-endian, data-type-policy=OVERRIDE, base-type=uint8, compu {phys=raw}, range phys 0..252
          signal ResultBLEConMonitoringFBD_VL_Ch_qual02: start 80, 8 bit, little-endian, data-type-policy=OVERRIDE, base-type=uint8, compu {phys=raw}, range phys 0..252
          signal ResultBLEConMonitoringFBD_VL_RSSILevel03: start 88, 8 bit, little-endian, data-type-policy=OVERRIDE, base-type=uint8, compu {phys=raw; unit dB}, range phys 0..252
          signal ResultBLEConMonitoringFBD_VL_connEventCounter03: start 96, 16 bit, little-endian, data-type-policy=OVERRIDE, base-type=uint16, compu {phys=raw}, range phys 0..65532
          signal ResultBLEConMonitoringFBD_VL_Ch_Num03: start 112, 8 bit, little-endian, data-type-policy=OVERRIDE, base-type=uint8, compu {phys=raw}, range phys 0..252
          signal ResultBLEConMonitoringFBD_VL_Ch_qual03: start 120, 8 bit, little-endian, data-type-policy=OVERRIDE, base-type=uint8, compu {phys=raw}, range phys 0..252
          signal ResultBLEConMonitoringFBD_VL_RSSILevel04: start 128, 8 bit, little-endian, data-type-policy=OVERRIDE, base-type=uint8, compu {phys=raw; unit dB}, range phys 0..252
          signal ResultBLEConMonitoringFBD_VL_connEventCounter04: start 136, 16 bit, little-endian, data-type-policy=OVERRIDE, base-type=uint16, compu {phys=raw}, range phys 0..65532
          signal ResultBLEConMonitoringFBD_VL_Ch_Num04: start 152, 8 bit, little-endian, data-type-policy=OVERRIDE, base-type=uint8, compu {phys=raw}, range phys 0..252
          signal ResultBLEConMonitoringFBD_VL_Ch_qual04: start 160, 8 bit, little-endian, data-type-policy=OVERRIDE, base-type=uint8, compu {phys=raw}, range phys 0..252
          signal ResultBLEConMonitoringFBD_VL_RSSILevel05: start 168, 8 bit, little-endian, data-type-policy=OVERRIDE, base-type=uint8, compu {phys=raw; unit dB}, range phys 0..252
          signal ResultBLEConMonitoringFBD_VL_connEventCounter05: start 176, 16 bit, little-endian, data-type-policy=OVERRIDE, base-type=uint16, compu {phys=raw}, range phys 0..65532
          signal ResultBLEConMonitoringFBD_VL_Ch_Num05: start 192, 8 bit, little-endian, data-type-policy=OVERRIDE, base-type=uint8, compu {phys=raw}, range phys 0..252
          signal ResultBLEConMonitoringFBD_VL_Ch_qual05: start 200, 8 bit, little-endian, data-type-policy=OVERRIDE, base-type=uint8, compu {phys=raw}, range phys 0..252
          signal ResultBLEConMonitoringFBD_VL_RSSILevel06: start 208, 8 bit, little-endian, data-type-policy=OVERRIDE, base-type=uint8, compu {phys=raw; unit dB}, range phys 0..252
          signal ResultBLEConMonitoringFBD_VL_connEventCounter06: start 216, 16 bit, little-endian, data-type-policy=OVERRIDE, base-type=uint16, compu {phys=raw}, range phys 0..65532
          signal ResultBLEConMonitoringFBD_VL_Ch_Num06: start 232, 8 bit, little-endian, data-type-policy=OVERRIDE, base-type=uint8, compu {phys=raw}, range phys 0..252
          signal ResultBLEConMonitoringFBD_VL_Ch_qual06: start 240, 8 bit, little-endian, data-type-policy=OVERRIDE, base-type=uint8, compu {phys=raw}, range phys 0..252
          signal ResultBLEConMonitoringFBD_VL_RSSILevel07: start 248, 8 bit, little-endian, data-type-policy=OVERRIDE, base-type=uint8, compu {phys=raw; unit dB}, range phys 0..252
          signal ResultBLEConMonitoringFBD_VL_connEventCounter07: start 256, 16 bit, little-endian, data-type-policy=OVERRIDE, base-type=uint16, compu {phys=raw}, range phys 0..65532
          signal ResultBLEConMonitoringFBD_VL_Ch_Num07: start 272, 8 bit, little-endian, data-type-policy=OVERRIDE, base-type=uint8, compu {phys=raw}, range phys 0..252
          signal ResultBLEConMonitoringFBD_VL_Ch_qual07: start 280, 8 bit, little-endian, data-type-policy=OVERRIDE, base-type=uint8, compu {phys=raw}, range phys 0..252
          signal ResultBLEConMonitoringFBD_VL_RSSILevel08: start 288, 8 bit, little-endian, data-type-policy=OVERRIDE, base-type=uint8, compu {phys=raw; unit dB}, range phys 0..252
          signal ResultBLEConMonitoringFBD_VL_connEventCounter08: start 296, 16 bit, little-endian, data-type-policy=OVERRIDE, base-type=uint16, compu {phys=raw}, range phys 0..65532
          signal ResultBLEConMonitoringFBD_VL_Ch_Num08: start 312, 8 bit, little-endian, data-type-policy=OVERRIDE, base-type=uint8, compu {phys=raw}, range phys 0..252
          signal ResultBLEConMonitoringFBD_VL_Ch_qual08: start 320, 8 bit, little-endian, data-type-policy=OVERRIDE, base-type=uint8, compu {phys=raw}, range phys 0..252
          signal ResultBLEConMonitoringFBD_VL_RSSILevel09: start 328, 8 bit, little-endian, data-type-policy=OVERRIDE, base-type=uint8, compu {phys=raw; unit dB}, range phys 0..252
          signal ResultBLEConMonitoringFBD_VL_connEventCounter09: start 336, 16 bit, little-endian, data-type-policy=OVERRIDE, base-type=uint16, compu {phys=raw}, range phys 0..65532
          signal ResultBLEConMonitoringFBD_VL_Ch_Num09: start 352, 8 bit, little-endian, data-type-policy=OVERRIDE, base-type=uint8, compu {phys=raw}, range phys 0..252
          signal ResultBLEConMonitoringFBD_VL_Ch_qual09: start 360, 8 bit, little-endian, data-type-policy=OVERRIDE, base-type=uint8, compu {phys=raw}, range phys 0..252
          signal ResultBLEConMonitoringFBD_VL_RSSILevel10: start 368, 8 bit, little-endian, data-type-policy=OVERRIDE, base-type=uint8, compu {phys=raw; unit dB}, range phys 0..252
          signal ResultBLEConMonitoringFBD_VL_connEventCounter10: start 376, 16 bit, little-endian, data-type-policy=OVERRIDE, base-type=uint16, compu {phys=raw}, range phys 0..65532
          signal ResultBLEConMonitoringFBD_VL_Ch_Num10: start 392, 8 bit, little-endian, data-type-policy=OVERRIDE, base-type=uint8, compu {phys=raw}, range phys 0..252
          signal ResultBLEConMonitoringFBD_VL_Ch_qual10: start 400, 8 bit, little-endian, data-type-policy=OVERRIDE, base-type=uint8, compu {phys=raw}, range phys 0..252
          signal ResultBLEConMonitoringFBD_VL_IV00: start 408, 8 bit, little-endian, data-type-policy=OVERRIDE, base-type=uint8, compu {phys=raw}, range phys 0..255
          signal ResultBLEConMonitoringFBD_VL_IV01: start 416, 8 bit, little-endian, data-type-policy=OVERRIDE, base-type=uint8, compu {phys=raw}, range phys 0..255
          signal ResultBLEConMonitoringFBD_VL_IV02: start 424, 8 bit, little-endian, data-type-policy=OVERRIDE, base-type=uint8, compu {phys=raw}, range phys 0..255
          signal ResultBLEConMonitoringFBD_VL_IV03: start 432, 8 bit, little-endian, data-type-policy=OVERRIDE, base-type=uint8, compu {phys=raw}, range phys 0..255
          signal ResultBLEConMonitoringFBD_VL_Sign00: start 440, 8 bit, little-endian, data-type-policy=OVERRIDE, base-type=uint8, compu {phys=raw}, range phys 0..255
          signal ResultBLEConMonitoringFBD_VL_Sign01: start 448, 8 bit, little-endian, data-type-policy=OVERRIDE, base-type=uint8, compu {phys=raw}, range phys 0..255
          signal ResultBLEConMonitoringFBD_VL_Sign02: start 456, 8 bit, little-endian, data-type-policy=OVERRIDE, base-type=uint8, compu {phys=raw}, range phys 0..255
          signal ResultBLEConMonitoringFBD_VL_Sign03: start 464, 8 bit, little-endian, data-type-policy=OVERRIDE, base-type=uint8, compu {phys=raw}, range phys 0..255
          signal ResultBLEConMonitoringFBD_VL_Sign04: start 472, 8 bit, little-endian, data-type-policy=OVERRIDE, base-type=uint8, compu {phys=raw}, range phys 0..255
          signal ResultBLEConMonitoringFBD_VL_Sign05: start 480, 8 bit, little-endian, data-type-policy=OVERRIDE, base-type=uint8, compu {phys=raw}, range phys 0..255
          signal ResultBLEConMonitoringFBD_VL_Sign06: start 488, 8 bit, little-endian, data-type-policy=OVERRIDE, base-type=uint8, compu {phys=raw}, range phys 0..255
          signal ResultBLEConMonitoringFBD_VL_Sign07: start 496, 8 bit, little-endian, data-type-policy=OVERRIDE, base-type=uint8, compu {phys=raw}, range phys 0..255
      frame ResultBLEConMonitoringFBD_VM: id 0x122, frame-length=64, can-addressing-mode=STANDARD, can-frame-rx-behavior=CAN-FD, can-frame-tx-behavior=CAN-FD
        pdu ResultBLEConMonitoringFBD_VM: length=64, unused-bit-pattern=0
          signal ResultBLEConMonitoringFBD_VM_IRKListID: start 0, 8 bit, little-endian, data-type-policy=OVERRIDE, base-type=uint8, compu {phys=raw}, range phys 0..252
          signal ResultBLEConMonitoringFBD_VM_RSSILevel01: start 8, 8 bit, little-endian, data-type-policy=OVERRIDE, base-type=uint8, compu {phys=raw; unit dB}, range phys 0..252
          signal ResultBLEConMonitoringFBD_VM_connEventCounter01: start 16, 16 bit, little-endian, data-type-policy=OVERRIDE, base-type=uint16, compu {phys=raw}, range phys 0..65532
          signal ResultBLEConMonitoringFBD_VM_Ch_Num01: start 32, 8 bit, little-endian, data-type-policy=OVERRIDE, base-type=uint8, compu {phys=raw}, range phys 0..252
          signal ResultBLEConMonitoringFBD_VM_Dev_TxPower: start 40, 8 bit, little-endian, data-type-policy=OVERRIDE, base-type=uint8, compu {phys=raw}, range phys 0..252
          signal ResultBLEConMonitoringFBD_VM_RSSILevel02: start 48, 8 bit, little-endian, data-type-policy=OVERRIDE, base-type=uint8, compu {phys=raw; unit dB}, range phys 0..252
          signal ResultBLEConMonitoringFBD_VM_connEventCounter02: start 56, 16 bit, little-endian, data-type-policy=OVERRIDE, base-type=uint16, compu {phys=raw}, range phys 0..65532
          signal ResultBLEConMonitoringFBD_VM_Ch_Num02: start 72, 8 bit, little-endian, data-type-policy=OVERRIDE, base-type=uint8, compu {phys=raw}, range phys 0..252
          signal ResultBLEConMonitoringFBD_VM_Ch_qual02: start 80, 8 bit, little-endian, data-type-policy=OVERRIDE, base-type=uint8, compu {phys=raw}, range phys 0..252
          signal ResultBLEConMonitoringFBD_VM_RSSILevel03: start 88, 8 bit, little-endian, data-type-policy=OVERRIDE, base-type=uint8, compu {phys=raw; unit dB}, range phys 0..252
          signal ResultBLEConMonitoringFBD_VM_connEventCounter03: start 96, 16 bit, little-endian, data-type-policy=OVERRIDE, base-type=uint16, compu {phys=raw}, range phys 0..65532
          signal ResultBLEConMonitoringFBD_VM_Ch_Num03: start 112, 8 bit, little-endian, data-type-policy=OVERRIDE, base-type=uint8, compu {phys=raw}, range phys 0..252
          signal ResultBLEConMonitoringFBD_VM_Ch_qual03: start 120, 8 bit, little-endian, data-type-policy=OVERRIDE, base-type=uint8, compu {phys=raw}, range phys 0..252
          signal ResultBLEConMonitoringFBD_VM_RSSILevel04: start 128, 8 bit, little-endian, data-type-policy=OVERRIDE, base-type=uint8, compu {phys=raw; unit dB}, range phys 0..252
          signal ResultBLEConMonitoringFBD_VM_connEventCounter04: start 136, 16 bit, little-endian, data-type-policy=OVERRIDE, base-type=uint16, compu {phys=raw}, range phys 0..65532
          signal ResultBLEConMonitoringFBD_VM_Ch_Num04: start 152, 8 bit, little-endian, data-type-policy=OVERRIDE, base-type=uint8, compu {phys=raw}, range phys 0..252
          signal ResultBLEConMonitoringFBD_VM_Ch_qual04: start 160, 8 bit, little-endian, data-type-policy=OVERRIDE, base-type=uint8, compu {phys=raw}, range phys 0..252
          signal ResultBLEConMonitoringFBD_VM_RSSILevel05: start 168, 8 bit, little-endian, data-type-policy=OVERRIDE, base-type=uint8, compu {phys=raw; unit dB}, range phys 0..252
          signal ResultBLEConMonitoringFBD_VM_connEventCounter05: start 176, 16 bit, little-endian, data-type-policy=OVERRIDE, base-type=uint16, compu {phys=raw}, range phys 0..65532
          signal ResultBLEConMonitoringFBD_VM_Ch_Num05: start 192, 8 bit, little-endian, data-type-policy=OVERRIDE, base-type=uint8, compu {phys=raw}, range phys 0..252
          signal ResultBLEConMonitoringFBD_VM_Ch_qual05: start 200, 8 bit, little-endian, data-type-policy=OVERRIDE, base-type=uint8, compu {phys=raw}, range phys 0..252
          signal ResultBLEConMonitoringFBD_VM_RSSILevel06: start 208, 8 bit, little-endian, data-type-policy=OVERRIDE, base-type=uint8, compu {phys=raw; unit dB}, range phys 0..252
          signal ResultBLEConMonitoringFBD_VM_connEventCounter06: start 216, 16 bit, little-endian, data-type-policy=OVERRIDE, base-type=uint16, compu {phys=raw}, range phys 0..65532
          signal ResultBLEConMonitoringFBD_VM_Ch_Num06: start 232, 8 bit, little-endian, data-type-policy=OVERRIDE, base-type=uint8, compu {phys=raw}, range phys 0..252
          signal ResultBLEConMonitoringFBD_VM_Ch_qual06: start 240, 8 bit, little-endian, data-type-policy=OVERRIDE, base-type=uint8, compu {phys=raw}, range phys 0..252
          signal ResultBLEConMonitoringFBD_VM_RSSILevel07: start 248, 8 bit, little-endian, data-type-policy=OVERRIDE, base-type=uint8, compu {phys=raw; unit dB}, range phys 0..252
          signal ResultBLEConMonitoringFBD_VM_connEventCounter07: start 256, 16 bit, little-endian, data-type-policy=OVERRIDE, base-type=uint16, compu {phys=raw}, range phys 0..65532
          signal ResultBLEConMonitoringFBD_VM_Ch_Num07: start 272, 8 bit, little-endian, data-type-policy=OVERRIDE, base-type=uint8, compu {phys=raw}, range phys 0..252
          signal ResultBLEConMonitoringFBD_VM_Ch_qual07: start 280, 8 bit, little-endian, data-type-policy=OVERRIDE, base-type=uint8, compu {phys=raw}, range phys 0..252
          signal ResultBLEConMonitoringFBD_VM_RSSILevel08: start 288, 8 bit, little-endian, data-type-policy=OVERRIDE, base-type=uint8, compu {phys=raw; unit dB}, range phys 0..252
          signal ResultBLEConMonitoringFBD_VM_connEventCounter08: start 296, 16 bit, little-endian, data-type-policy=OVERRIDE, base-type=uint16, compu {phys=raw}, range phys 0..65532
          signal ResultBLEConMonitoringFBD_VM_Ch_Num08: start 312, 8 bit, little-endian, data-type-policy=OVERRIDE, base-type=uint8, compu {phys=raw}, range phys 0..252
          signal ResultBLEConMonitoringFBD_VM_Ch_qual08: start 320, 8 bit, little-endian, data-type-policy=OVERRIDE, base-type=uint8, compu {phys=raw}, range phys 0..252
          signal ResultBLEConMonitoringFBD_VM_RSSILevel09: start 328, 8 bit, little-endian, data-type-policy=OVERRIDE, base-type=uint8, compu {phys=raw; unit dB}, range phys 0..252
          signal ResultBLEConMonitoringFBD_VM_connEventCounter09: start 336, 16 bit, little-endian, data-type-policy=OVERRIDE, base-type=uint16, compu {phys=raw}, range phys 0..65532
          signal ResultBLEConMonitoringFBD_VM_Ch_Num09: start 352, 8 bit, little-endian, data-type-policy=OVERRIDE, base-type=uint8, compu {phys=raw}, range phys 0..252
          signal ResultBLEConMonitoringFBD_VM_Ch_qual09: start 360, 8 bit, little-endian, data-type-policy=OVERRIDE, base-type=uint8, compu {phys=raw}, range phys 0..252
          signal ResultBLEConMonitoringFBD_VM_RSSILevel10: start 368, 8 bit, little-endian, data-type-policy=OVERRIDE, base-type=uint8, compu {phys=raw; unit dB}, range phys 0..252
          signal ResultBLEConMonitoringFBD_VM_connEventCounter10: start 376, 16 bit, little-endian, data-type-policy=OVERRIDE, base-type=uint16, compu {phys=raw}, range phys 0..65532
          signal ResultBLEConMonitoringFBD_VM_Ch_Num10: start 392, 8 bit, little-endian, data-type-policy=OVERRIDE, base-type=uint8, compu {phys=raw}, range phys 0..252
          signal ResultBLEConMonitoringFBD_VM_Ch_qual10: start 400, 8 bit, little-endian, data-type-policy=OVERRIDE, base-type=uint8, compu {phys=raw}, range phys 0..252
          signal ResultBLEConMonitoringFBD_VM_IV00: start 408, 8 bit, little-endian, data-type-policy=OVERRIDE, base-type=uint8, compu {phys=raw}, range phys 0..255
          signal ResultBLEConMonitoringFBD_VM_IV01: start 416, 8 bit, little-endian, data-type-policy=OVERRIDE, base-type=uint8, compu {phys=raw}, range phys 0..255
          signal ResultBLEConMonitoringFBD_VM_IV02: start 424, 8 bit, little-endian, data-type-policy=OVERRIDE, base-type=uint8, compu {phys=raw}, range phys 0..255
          signal ResultBLEConMonitoringFBD_VM_IV03: start 432, 8 bit, little-endian, data-type-policy=OVERRIDE, base-type=uint8, compu {phys=raw}, range phys 0..255
          signal ResultBLEConMonitoringFBD_VM_Sign00: start 440, 8 bit, little-endian, data-type-policy=OVERRIDE, base-type=uint8, compu {phys=raw}, range phys 0..255
          signal ResultBLEConMonitoringFBD_VM_Sign01: start 448, 8 bit, little-endian, data-type-policy=OVERRIDE, base-type=uint8, compu {phys=raw}, range phys 0..255
          signal ResultBLEConMonitoringFBD_VM_Sign02: start 456, 8 bit, little-endian, data-type-policy=OVERRIDE, base-type=uint8, compu {phys=raw}, range phys 0..255
          signal ResultBLEConMonitoringFBD_VM_Sign03: start 464, 8 bit, little-endian, data-type-policy=OVERRIDE, base-type=uint8, compu {phys=raw}, range phys 0..255
          signal ResultBLEConMonitoringFBD_VM_Sign04: start 472, 8 bit, little-endian, data-type-policy=OVERRIDE, base-type=uint8, compu {phys=raw}, range phys 0..255
          signal ResultBLEConMonitoringFBD_VM_Sign05: start 480, 8 bit, little-endian, data-type-policy=OVERRIDE, base-type=uint8, compu {phys=raw}, range phys 0..255
          signal ResultBLEConMonitoringFBD_VM_Sign06: start 488, 8 bit, little-endian, data-type-policy=OVERRIDE, base-type=uint8, compu {phys=raw}, range phys 0..255
          signal ResultBLEConMonitoringFBD_VM_Sign07: start 496, 8 bit, little-endian, data-type-policy=OVERRIDE, base-type=uint8, compu {phys=raw}, range phys 0..255
      frame ResultBLEConMonitoringFBD_VR: id 0x127, frame-length=64, can-addressing-mode=STANDARD, can-frame-rx-behavior=CAN-FD, can-frame-tx-behavior=CAN-FD
        pdu ResultBLEConMonitoringFBD_VR: length=64, unused-bit-pattern=0
          signal ResultBLEConMonitoringFBD_VR_IRKListID: start 0, 8 bit, little-endian, data-type-policy=OVERRIDE, base-type=uint8, compu {phys=raw}, range phys 0..252
          signal ResultBLEConMonitoringFBD_VR_RSSILevel01: start 8, 8 bit, little-endian, data-type-policy=OVERRIDE, base-type=uint8, compu {phys=raw; unit dB}, range phys 0..252
          signal ResultBLEConMonitoringFBD_VR_connEventCounter01: start 16, 16 bit, little-endian, data-type-policy=OVERRIDE, base-type=uint16, compu {phys=raw}, range phys 0..65532
          signal ResultBLEConMonitoringFBD_VR_Ch_Num01: start 32, 8 bit, little-endian, data-type-policy=OVERRIDE, base-type=uint8, compu {phys=raw}, range phys 0..252
          signal ResultBLEConMonitoringFBD_VR_Dev_TxPower: start 40, 8 bit, little-endian, data-type-policy=OVERRIDE, base-type=uint8, compu {phys=raw}, range phys 0..252
          signal ResultBLEConMonitoringFBD_VR_RSSILevel02: start 48, 8 bit, little-endian, data-type-policy=OVERRIDE, base-type=uint8, compu {phys=raw; unit dB}, range phys 0..252
          signal ResultBLEConMonitoringFBD_VR_connEventCounter02: start 56, 16 bit, little-endian, data-type-policy=OVERRIDE, base-type=uint16, compu {phys=raw}, range phys 0..65532
          signal ResultBLEConMonitoringFBD_VR_Ch_Num02: start 72, 8 bit, little-endian, data-type-policy=OVERRIDE, base-type=uint8, compu {phys=raw}, range phys 0..252
          signal ResultBLEConMonitoringFBD_VR_Ch_qual02: start 80, 8 bit, little-endian, data-type-policy=OVERRIDE, base-type=uint8, compu {phys=raw}, range phys 0..252
          signal ResultBLEConMonitoringFBD_VR_RSSILevel03: start 88, 8 bit, little-endian, data-type-policy=OVERRIDE, base-type=uint8, compu {phys=raw; unit dB}, range phys 0..252
          signal ResultBLEConMonitoringFBD_VR_connEventCounter03: start 96, 16 bit, little-endian, data-type-policy=OVERRIDE, base-type=uint16, compu {phys=raw}, range phys 0..65532
          signal ResultBLEConMonitoringFBD_VR_Ch_Num03: start 112, 8 bit, little-endian, data-type-policy=OVERRIDE, base-type=uint8, compu {phys=raw}, range phys 0..252
          signal ResultBLEConMonitoringFBD_VR_Ch_qual03: start 120, 8 bit, little-endian, data-type-policy=OVERRIDE, base-type=uint8, compu {phys=raw}, range phys 0..252
          signal ResultBLEConMonitoringFBD_VR_RSSILevel04: start 128, 8 bit, little-endian, data-type-policy=OVERRIDE, base-type=uint8, compu {phys=raw; unit dB}, range phys 0..252
          signal ResultBLEConMonitoringFBD_VR_connEventCounter04: start 136, 16 bit, little-endian, data-type-policy=OVERRIDE, base-type=uint16, compu {phys=raw}, range phys 0..65532
          signal ResultBLEConMonitoringFBD_VR_Ch_Num04: start 152, 8 bit, little-endian, data-type-policy=OVERRIDE, base-type=uint8, compu {phys=raw}, range phys 0..252
          signal ResultBLEConMonitoringFBD_VR_Ch_qual04: start 160, 8 bit, little-endian, data-type-policy=OVERRIDE, base-type=uint8, compu {phys=raw}, range phys 0..252
          signal ResultBLEConMonitoringFBD_VR_RSSILevel05: start 168, 8 bit, little-endian, data-type-policy=OVERRIDE, base-type=uint8, compu {phys=raw; unit dB}, range phys 0..252
          signal ResultBLEConMonitoringFBD_VR_connEventCounter05: start 176, 16 bit, little-endian, data-type-policy=OVERRIDE, base-type=uint16, compu {phys=raw}, range phys 0..65532
          signal ResultBLEConMonitoringFBD_VR_Ch_Num05: start 192, 8 bit, little-endian, data-type-policy=OVERRIDE, base-type=uint8, compu {phys=raw}, range phys 0..252
          signal ResultBLEConMonitoringFBD_VR_Ch_qual05: start 200, 8 bit, little-endian, data-type-policy=OVERRIDE, base-type=uint8, compu {phys=raw}, range phys 0..252
          signal ResultBLEConMonitoringFBD_VR_RSSILevel06: start 208, 8 bit, little-endian, data-type-policy=OVERRIDE, base-type=uint8, compu {phys=raw; unit dB}, range phys 0..252
          signal ResultBLEConMonitoringFBD_VR_connEventCounter06: start 216, 16 bit, little-endian, data-type-policy=OVERRIDE, base-type=uint16, compu {phys=raw}, range phys 0..65532
          signal ResultBLEConMonitoringFBD_VR_Ch_Num06: start 232, 8 bit, little-endian, data-type-policy=OVERRIDE, base-type=uint8, compu {phys=raw}, range phys 0..252
          signal ResultBLEConMonitoringFBD_VR_Ch_qual06: start 240, 8 bit, little-endian, data-type-policy=OVERRIDE, base-type=uint8, compu {phys=raw}, range phys 0..252
          signal ResultBLEConMonitoringFBD_VR_RSSILevel07: start 248, 8 bit, little-endian, data-type-policy=OVERRIDE, base-type=uint8, compu {phys=raw; unit dB}, range phys 0..252
          signal ResultBLEConMonitoringFBD_VR_connEventCounter07: start 256, 16 bit, little-endian, data-type-policy=OVERRIDE, base-type=uint16, compu {phys=raw}, range phys 0..65532
          signal ResultBLEConMonitoringFBD_VR_Ch_Num07: start 272, 8 bit, little-endian, data-type-policy=OVERRIDE, base-type=uint8, compu {phys=raw}, range phys 0..252
          signal ResultBLEConMonitoringFBD_VR_Ch_qual07: start 280, 8 bit, little-endian, data-type-policy=OVERRIDE, base-type=uint8, compu {phys=raw}, range phys 0..252
          signal ResultBLEConMonitoringFBD_VR_RSSILevel08: start 288, 8 bit, little-endian, data-type-policy=OVERRIDE, base-type=uint8, compu {phys=raw; unit dB}, range phys 0..252
          signal ResultBLEConMonitoringFBD_VR_connEventCounter08: start 296, 16 bit, little-endian, data-type-policy=OVERRIDE, base-type=uint16, compu {phys=raw}, range phys 0..65532
          signal ResultBLEConMonitoringFBD_VR_Ch_Num08: start 312, 8 bit, little-endian, data-type-policy=OVERRIDE, base-type=uint8, compu {phys=raw}, range phys 0..252
          signal ResultBLEConMonitoringFBD_VR_Ch_qual08: start 320, 8 bit, little-endian, data-type-policy=OVERRIDE, base-type=uint8, compu {phys=raw}, range phys 0..252
          signal ResultBLEConMonitoringFBD_VR_RSSILevel09: start 328, 8 bit, little-endian, data-type-policy=OVERRIDE, base-type=uint8, compu {phys=raw; unit dB}, range phys 0..252
          signal ResultBLEConMonitoringFBD_VR_connEventCounter09: start 336, 16 bit, little-endian, data-type-policy=OVERRIDE, base-type=uint16, compu {phys=raw}, range phys 0..65532
          signal ResultBLEConMonitoringFBD_VR_Ch_Num09: start 352, 8 bit, little-endian, data-type-policy=OVERRIDE, base-type=uint8, compu {phys=raw}, range phys 0..252
          signal ResultBLEConMonitoringFBD_VR_Ch_qual09: start 360, 8 bit, little-endian, data-type-policy=OVERRIDE, base-type=uint8, compu {phys=raw}, range phys 0..252
          signal ResultBLEConMonitoringFBD_VR_RSSILevel10: start 368, 8 bit, little-endian, data-type-policy=OVERRIDE, base-type=uint8, compu {phys=raw; unit dB}, range phys 0..252
          signal ResultBLEConMonitoringFBD_VR_connEventCounter10: start 376, 16 bit, little-endian, data-type-policy=OVERRIDE, base-type=uint16, compu {phys=raw}, range phys 0..65532
          signal ResultBLEConMonitoringFBD_VR_Ch_Num10: start 392, 8 bit, little-endian, data-type-policy=OVERRIDE, base-type=uint8, compu {phys=raw}, range phys 0..252
          signal ResultBLEConMonitoringFBD_VR_Ch_qual10: start 400, 8 bit, little-endian, data-type-policy=OVERRIDE, base-type=uint8, compu {phys=raw}, range phys 0..252
          signal ResultBLEConMonitoringFBD_VR_IV00: start 408, 8 bit, little-endian, data-type-policy=OVERRIDE, base-type=uint8, compu {phys=raw}, range phys 0..255
          signal ResultBLEConMonitoringFBD_VR_IV01: start 416, 8 bit, little-endian, data-type-policy=OVERRIDE, base-type=uint8, compu {phys=raw}, range phys 0..255
          signal ResultBLEConMonitoringFBD_VR_IV02: start 424, 8 bit, little-endian, data-type-policy=OVERRIDE, base-type=uint8, compu {phys=raw}, range phys 0..255
          signal ResultBLEConMonitoringFBD_VR_IV03: start 432, 8 bit, little-endian, data-type-policy=OVERRIDE, base-type=uint8, compu {phys=raw}, range phys 0..255
          signal ResultBLEConMonitoringFBD_VR_Sign00: start 440, 8 bit, little-endian, data-type-policy=OVERRIDE, base-type=uint8, compu {phys=raw}, range phys 0..255
          signal ResultBLEConMonitoringFBD_VR_Sign01: start 448, 8 bit, little-endian, data-type-policy=OVERRIDE, base-type=uint8, compu {phys=raw}, range phys 0..255
          signal ResultBLEConMonitoringFBD_VR_Sign02: start 456, 8 bit, little-endian, data-type-policy=OVERRIDE, base-type=uint8, compu {phys=raw}, range phys 0..255
          signal ResultBLEConMonitoringFBD_VR_Sign03: start 464, 8 bit, little-endian, data-type-policy=OVERRIDE, base-type=uint8, compu {phys=raw}, range phys 0..255
          signal ResultBLEConMonitoringFBD_VR_Sign04: start 472, 8 bit, little-endian, data-type-policy=OVERRIDE, base-type=uint8, compu {phys=raw}, range phys 0..255
          signal ResultBLEConMonitoringFBD_VR_Sign05: start 480, 8 bit, little-endian, data-type-policy=OVERRIDE, base-type=uint8, compu {phys=raw}, range phys 0..255
          signal ResultBLEConMonitoringFBD_VR_Sign06: start 488, 8 bit, little-endian, data-type-policy=OVERRIDE, base-type=uint8, compu {phys=raw}, range phys 0..255
          signal ResultBLEConMonitoringFBD_VR_Sign07: start 496, 8 bit, little-endian, data-type-policy=OVERRIDE, base-type=uint8, compu {phys=raw}, range phys 0..255
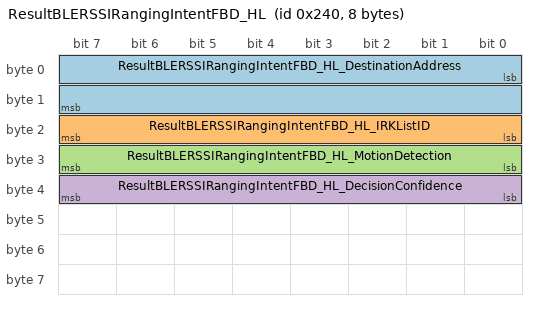
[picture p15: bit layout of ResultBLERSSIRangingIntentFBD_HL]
      frame ResultBLERSSIRangingIntentFBD_HL: id 0x240, frame-length=8, can-addressing-mode=STANDARD, can-frame-rx-behavior=CAN-20, can-frame-tx-behavior=CAN-20
        pdu ResultBLERSSIRangingIntentFBD_HL: length=8, unused-bit-pattern=0
          signal ResultBLERSSIRangingIntentFBD_HL_DestinationAddress: start 0, 16 bit, little-endian, data-type-policy=OVERRIDE, compu {phys=raw}
          signal ResultBLERSSIRangingIntentFBD_HL_IRKListID: start 16, 8 bit, little-endian, data-type-policy=OVERRIDE, base-type=uint8, compu {phys=raw}, range phys 0..252
          signal ResultBLERSSIRangingIntentFBD_HL_MotionDetection: start 24, 8 bit, little-endian, data-type-policy=OVERRIDE, base-type=uint8, compu {phys=raw}, range phys 0..252
          signal ResultBLERSSIRangingIntentFBD_HL_DecisionConfidence: start 32, 8 bit, little-endian, data-type-policy=OVERRIDE, base-type=uint8, compu {phys=raw*0.004}, range phys 0..1
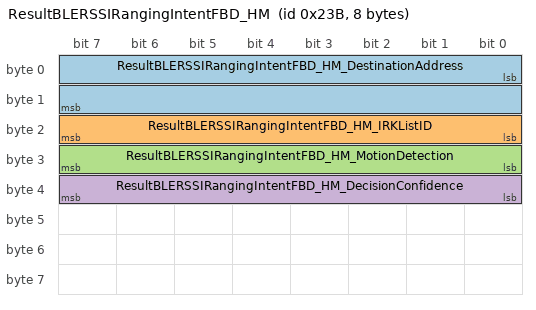
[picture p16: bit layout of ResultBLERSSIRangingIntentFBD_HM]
      frame ResultBLERSSIRangingIntentFBD_HM: id 0x23B, frame-length=8, can-addressing-mode=STANDARD, can-frame-rx-behavior=CAN-20, can-frame-tx-behavior=CAN-20
        pdu ResultBLERSSIRangingIntentFBD_HM: length=8, unused-bit-pattern=0
          signal ResultBLERSSIRangingIntentFBD_HM_DestinationAddress: start 0, 16 bit, little-endian, data-type-policy=OVERRIDE, compu {phys=raw}
          signal ResultBLERSSIRangingIntentFBD_HM_IRKListID: start 16, 8 bit, little-endian, data-type-policy=OVERRIDE, base-type=uint8, compu {phys=raw}, range phys 0..252
          signal ResultBLERSSIRangingIntentFBD_HM_MotionDetection: start 24, 8 bit, little-endian, data-type-policy=OVERRIDE, base-type=uint8, compu {phys=raw}, range phys 0..252
          signal ResultBLERSSIRangingIntentFBD_HM_DecisionConfidence: start 32, 8 bit, little-endian, data-type-policy=OVERRIDE, base-type=uint8, compu {phys=raw*0.004}, range phys 0..1
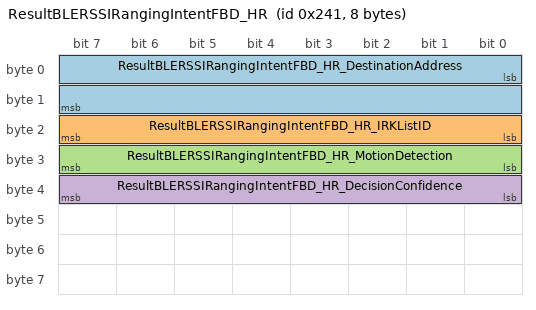
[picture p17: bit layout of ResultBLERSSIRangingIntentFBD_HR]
      frame ResultBLERSSIRangingIntentFBD_HR: id 0x241, frame-length=8, can-addressing-mode=STANDARD, can-frame-rx-behavior=CAN-20, can-frame-tx-behavior=CAN-20
        pdu ResultBLERSSIRangingIntentFBD_HR: length=8, unused-bit-pattern=0
          signal ResultBLERSSIRangingIntentFBD_HR_DestinationAddress: start 0, 16 bit, little-endian, data-type-policy=OVERRIDE, compu {phys=raw}
          signal ResultBLERSSIRangingIntentFBD_HR_IRKListID: start 16, 8 bit, little-endian, data-type-policy=OVERRIDE, base-type=uint8, compu {phys=raw}, range phys 0..252
          signal ResultBLERSSIRangingIntentFBD_HR_MotionDetection: start 24, 8 bit, little-endian, data-type-policy=OVERRIDE, base-type=uint8, compu {phys=raw}, range phys 0..252
          signal ResultBLERSSIRangingIntentFBD_HR_DecisionConfidence: start 32, 8 bit, little-endian, data-type-policy=OVERRIDE, base-type=uint8, compu {phys=raw*0.004}, range phys 0..1
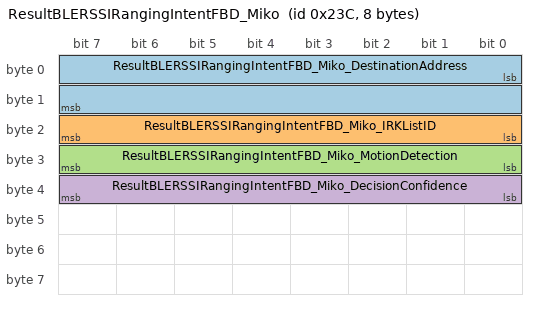
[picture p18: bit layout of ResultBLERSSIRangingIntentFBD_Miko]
      frame ResultBLERSSIRangingIntentFBD_Miko: id 0x23C, frame-length=8, can-addressing-mode=STANDARD, can-frame-rx-behavior=CAN-20, can-frame-tx-behavior=CAN-20
        pdu ResultBLERSSIRangingIntentFBD_Miko: length=8, unused-bit-pattern=0
          signal ResultBLERSSIRangingIntentFBD_Miko_DestinationAddress: start 0, 16 bit, little-endian, data-type-policy=OVERRIDE, compu {phys=raw}
          signal ResultBLERSSIRangingIntentFBD_Miko_IRKListID: start 16, 8 bit, little-endian, data-type-policy=OVERRIDE, base-type=uint8, compu {phys=raw}, range phys 0..252
          signal ResultBLERSSIRangingIntentFBD_Miko_MotionDetection: start 24, 8 bit, little-endian, data-type-policy=OVERRIDE, base-type=uint8, compu {phys=raw}, range phys 0..252
          signal ResultBLERSSIRangingIntentFBD_Miko_DecisionConfidence: start 32, 8 bit, little-endian, data-type-policy=OVERRIDE, base-type=uint8, compu {phys=raw*0.004}, range phys 0..1
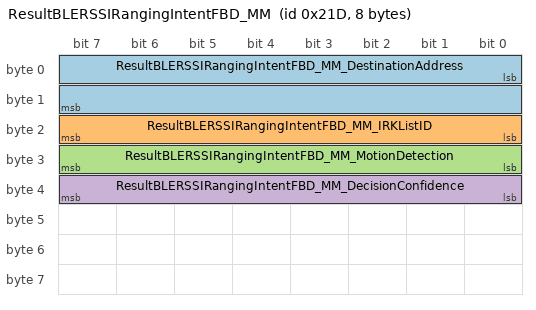
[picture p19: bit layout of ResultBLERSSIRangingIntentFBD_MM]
      frame ResultBLERSSIRangingIntentFBD_MM: id 0x21D, frame-length=8, can-addressing-mode=STANDARD, can-frame-rx-behavior=CAN-20, can-frame-tx-behavior=CAN-20
        pdu ResultBLERSSIRangingIntentFBD_MM: length=8, unused-bit-pattern=0
          signal ResultBLERSSIRangingIntentFBD_MM_DestinationAddress: start 0, 16 bit, little-endian, data-type-policy=OVERRIDE, compu {phys=raw}
          signal ResultBLERSSIRangingIntentFBD_MM_IRKListID: start 16, 8 bit, little-endian, data-type-policy=OVERRIDE, base-type=uint8, compu {phys=raw}, range phys 0..252
          signal ResultBLERSSIRangingIntentFBD_MM_MotionDetection: start 24, 8 bit, little-endian, data-type-policy=OVERRIDE, base-type=uint8, compu {phys=raw}, range phys 0..252
          signal ResultBLERSSIRangingIntentFBD_MM_DecisionConfidence: start 32, 8 bit, little-endian, data-type-policy=OVERRIDE, base-type=uint8, compu {phys=raw*0.004}, range phys 0..1
      frame ResultBLERSSIRangingIntentFBD_SML: id 0x242, frame-length=8, can-addressing-mode=STANDARD, can-frame-rx-behavior=CAN-20, can-frame-tx-behavior=CAN-20
        pdu ResultBLERSSIRangingIntentFBD_SML: length=8, unused-bit-pattern=0
          signal ResultBLERSSIRangingIntentFBD_SML_DestinationAddress: start 0, 16 bit, little-endian, data-type-policy=OVERRIDE, compu {phys=raw}
          signal ResultBLERSSIRangingIntentFBD_SML_IRKListID: start 16, 8 bit, little-endian, data-type-policy=OVERRIDE, base-type=uint8, compu {phys=raw}, range phys 0..252
          signal ResultBLERSSIRangingIntentFBD_SML_MotionDetection: start 24, 8 bit, little-endian, data-type-policy=OVERRIDE, base-type=uint8, compu {phys=raw}, range phys 0..252
      frame ResultBLERSSIRangingIntentFBD_SMR: id 0x243, frame-length=8, can-addressing-mode=STANDARD, can-frame-rx-behavior=CAN-20, can-frame-tx-behavior=CAN-20
        pdu ResultBLERSSIRangingIntentFBD_SMR: length=8, unused-bit-pattern=0
          signal ResultBLERSSIRangingIntentFBD_SMR_DestinationAddress: start 0, 16 bit, little-endian, data-type-policy=OVERRIDE, compu {phys=raw}
          signal ResultBLERSSIRangingIntentFBD_SMR_IRKListID: start 16, 8 bit, little-endian, data-type-policy=OVERRIDE, base-type=uint8, compu {phys=raw}, range phys 0..252
          signal ResultBLERSSIRangingIntentFBD_SMR_MotionDetection: start 24, 8 bit, little-endian, data-type-policy=OVERRIDE, base-type=uint8, compu {phys=raw}, range phys 0..252
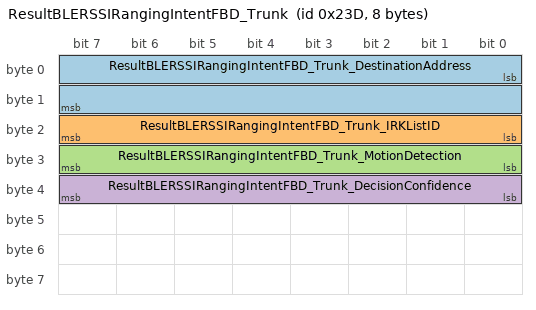
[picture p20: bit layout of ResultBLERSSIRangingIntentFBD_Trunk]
      frame ResultBLERSSIRangingIntentFBD_Trunk: id 0x23D, frame-length=8, can-addressing-mode=STANDARD, can-frame-rx-behavior=CAN-20, can-frame-tx-behavior=CAN-20
        pdu ResultBLERSSIRangingIntentFBD_Trunk: length=8, unused-bit-pattern=0
          signal ResultBLERSSIRangingIntentFBD_Trunk_DestinationAddress: start 0, 16 bit, little-endian, data-type-policy=OVERRIDE, compu {phys=raw}
          signal ResultBLERSSIRangingIntentFBD_Trunk_IRKListID: start 16, 8 bit, little-endian, data-type-policy=OVERRIDE, base-type=uint8, compu {phys=raw}, range phys 0..252
          signal ResultBLERSSIRangingIntentFBD_Trunk_MotionDetection: start 24, 8 bit, little-endian, data-type-policy=OVERRIDE, base-type=uint8, compu {phys=raw}, range phys 0..252
          signal ResultBLERSSIRangingIntentFBD_Trunk_DecisionConfidence: start 32, 8 bit, little-endian, data-type-policy=OVERRIDE, base-type=uint8, compu {phys=raw*0.004}, range phys 0..1
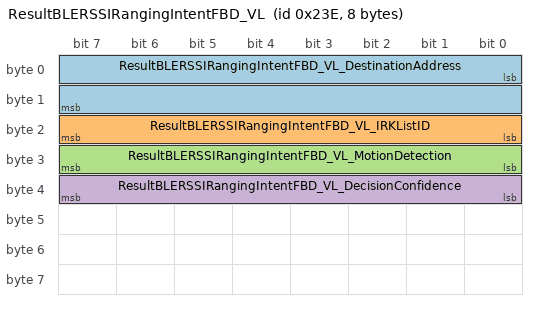
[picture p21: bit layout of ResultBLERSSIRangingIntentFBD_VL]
      frame ResultBLERSSIRangingIntentFBD_VL: id 0x23E, frame-length=8, can-addressing-mode=STANDARD, can-frame-rx-behavior=CAN-20, can-frame-tx-behavior=CAN-20
        pdu ResultBLERSSIRangingIntentFBD_VL: length=8, unused-bit-pattern=0
          signal ResultBLERSSIRangingIntentFBD_VL_DestinationAddress: start 0, 16 bit, little-endian, data-type-policy=OVERRIDE, compu {phys=raw}
          signal ResultBLERSSIRangingIntentFBD_VL_IRKListID: start 16, 8 bit, little-endian, data-type-policy=OVERRIDE, base-type=uint8, compu {phys=raw}, range phys 0..252
          signal ResultBLERSSIRangingIntentFBD_VL_MotionDetection: start 24, 8 bit, little-endian, data-type-policy=OVERRIDE, base-type=uint8, compu {phys=raw}, range phys 0..252
          signal ResultBLERSSIRangingIntentFBD_VL_DecisionConfidence: start 32, 8 bit, little-endian, data-type-policy=OVERRIDE, base-type=uint8, compu {phys=raw*0.004}, range phys 0..1
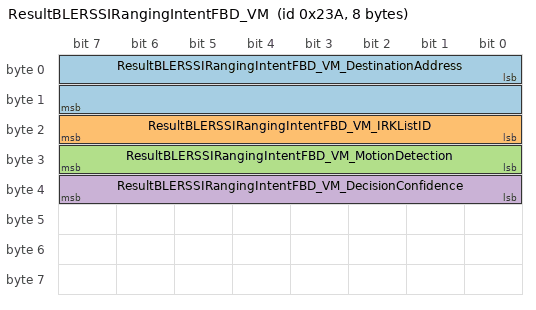
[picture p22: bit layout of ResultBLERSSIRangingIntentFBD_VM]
      frame ResultBLERSSIRangingIntentFBD_VM: id 0x23A, frame-length=8, can-addressing-mode=STANDARD, can-frame-rx-behavior=CAN-20, can-frame-tx-behavior=CAN-20
        pdu ResultBLERSSIRangingIntentFBD_VM: length=8, unused-bit-pattern=0
          signal ResultBLERSSIRangingIntentFBD_VM_DestinationAddress: start 0, 16 bit, little-endian, data-type-policy=OVERRIDE, compu {phys=raw}
          signal ResultBLERSSIRangingIntentFBD_VM_IRKListID: start 16, 8 bit, little-endian, data-type-policy=OVERRIDE, base-type=uint8, compu {phys=raw}, range phys 0..252
          signal ResultBLERSSIRangingIntentFBD_VM_MotionDetection: start 24, 8 bit, little-endian, data-type-policy=OVERRIDE, base-type=uint8, compu {phys=raw}, range phys 0..252
          signal ResultBLERSSIRangingIntentFBD_VM_DecisionConfidence: start 32, 8 bit, little-endian, data-type-policy=OVERRIDE, base-type=uint8, compu {phys=raw*0.004}, range phys 0..1
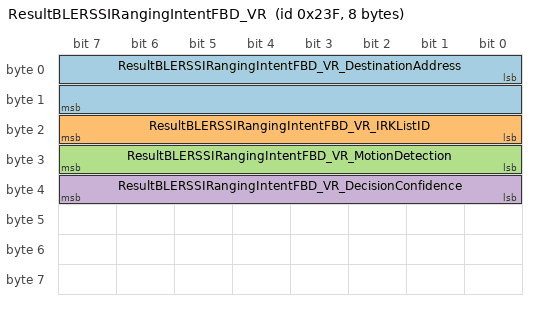
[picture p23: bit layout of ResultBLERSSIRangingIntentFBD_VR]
      frame ResultBLERSSIRangingIntentFBD_VR: id 0x23F, frame-length=8, can-addressing-mode=STANDARD, can-frame-rx-behavior=CAN-20, can-frame-tx-behavior=CAN-20
        pdu ResultBLERSSIRangingIntentFBD_VR: length=8, unused-bit-pattern=0
          signal ResultBLERSSIRangingIntentFBD_VR_DestinationAddress: start 0, 16 bit, little-endian, data-type-policy=OVERRIDE, compu {phys=raw}
          signal ResultBLERSSIRangingIntentFBD_VR_IRKListID: start 16, 8 bit, little-endian, data-type-policy=OVERRIDE, base-type=uint8, compu {phys=raw}, range phys 0..252
          signal ResultBLERSSIRangingIntentFBD_VR_MotionDetection: start 24, 8 bit, little-endian, data-type-policy=OVERRIDE, base-type=uint8, compu {phys=raw}, range phys 0..252
          signal ResultBLERSSIRangingIntentFBD_VR_DecisionConfidence: start 32, 8 bit, little-endian, data-type-policy=OVERRIDE, base-type=uint8, compu {phys=raw*0.004}, range phys 0..1
      frame ResumeRangingSessionFBD_HL: id 0x1E6, frame-length=20, can-addressing-mode=STANDARD, can-frame-rx-behavior=CAN-FD, can-frame-tx-behavior=CAN-FD
        pdu ResumeRangingSessionFBD_HL: length=20, unused-bit-pattern=0
          signal ResumeRangingSessionFBD_HL_Function: start 0, 8 bit, little-endian, data-type-policy=OVERRIDE, base-type=uint8, compu {phys=raw}, range phys 0..252
          signal ResumeRangingSessionFBD_HL_SessionIDShort: start 8, 8 bit, little-endian, data-type-policy=OVERRIDE, base-type=uint8, compu {phys=raw}, range phys 0..252
          signal ResumeRangingSessionFBD_HL_STSIndex: start 16, 32 bit, little-endian, data-type-policy=OVERRIDE, base-type=uint32, compu {phys=raw}, range phys 0..4294967292
          signal ResumeRangingSessionFBD_HL_RANMultiplier: start 48, 8 bit, little-endian, data-type-policy=OVERRIDE, base-type=uint8, compu {phys=raw}, range phys 0..252
          signal ResumeRangingSessionFBD_HL_UWBTime0: start 56, 64 bit, little-endian, data-type-policy=OVERRIDE, base-type=uint64, compu {phys=raw}, range phys 0..18446744073709551612
          signal ResumeRangingSessionFBD_HL_ToFStatus: start 120, 8 bit, little-endian, data-type-policy=OVERRIDE, base-type=uint8, compu {phys=raw}, range phys 0..252
          signal ResumeRangingSessionFBD_HL_RangingRoundIndex: start 128, 16 bit, little-endian, data-type-policy=OVERRIDE, base-type=uint16, compu {phys=raw}, range phys 0..65532
          signal ResumeRangingSessionFBD_HL_RangingBlockIndex: start 144, 16 bit, little-endian, data-type-policy=OVERRIDE, base-type=uint16, compu {phys=raw}, range phys 0..65532
      frame ResumeRangingSessionFBD_HM: id 0x1E1, frame-length=20, can-addressing-mode=STANDARD, can-frame-rx-behavior=CAN-FD, can-frame-tx-behavior=CAN-FD
        pdu ResumeRangingSessionFBD_HM: length=20, unused-bit-pattern=0
          signal ResumeRangingSessionFBD_HM_Function: start 0, 8 bit, little-endian, data-type-policy=OVERRIDE, base-type=uint8, compu {phys=raw}, range phys 0..252
          signal ResumeRangingSessionFBD_HM_SessionIDShort: start 8, 8 bit, little-endian, data-type-policy=OVERRIDE, base-type=uint8, compu {phys=raw}, range phys 0..252
          signal ResumeRangingSessionFBD_HM_STSIndex: start 16, 32 bit, little-endian, data-type-policy=OVERRIDE, base-type=uint32, compu {phys=raw}, range phys 0..4294967292
          signal ResumeRangingSessionFBD_HM_RANMultiplier: start 48, 8 bit, little-endian, data-type-policy=OVERRIDE, base-type=uint8, compu {phys=raw}, range phys 0..252
          signal ResumeRangingSessionFBD_HM_UWBTime0: start 56, 64 bit, little-endian, data-type-policy=OVERRIDE, base-type=uint64, compu {phys=raw}, range phys 0..18446744073709551612
          signal ResumeRangingSessionFBD_HM_ToFStatus: start 120, 8 bit, little-endian, data-type-policy=OVERRIDE, base-type=uint8, compu {phys=raw}, range phys 0..252
          signal ResumeRangingSessionFBD_HM_RangingRoundIndex: start 128, 16 bit, little-endian, data-type-policy=OVERRIDE, base-type=uint16, compu {phys=raw}, range phys 0..65532
          signal ResumeRangingSessionFBD_HM_RangingBlockIndex: start 144, 16 bit, little-endian, data-type-policy=OVERRIDE, base-type=uint16, compu {phys=raw}, range phys 0..65532
      frame ResumeRangingSessionFBD_HR: id 0x1E7, frame-length=20, can-addressing-mode=STANDARD, can-frame-rx-behavior=CAN-FD, can-frame-tx-behavior=CAN-FD
        pdu ResumeRangingSessionFBD_HR: length=20, unused-bit-pattern=0
          signal ResumeRangingSessionFBD_HR_Function: start 0, 8 bit, little-endian, data-type-policy=OVERRIDE, base-type=uint8, compu {phys=raw}, range phys 0..252
          signal ResumeRangingSessionFBD_HR_SessionIDShort: start 8, 8 bit, little-endian, data-type-policy=OVERRIDE, base-type=uint8, compu {phys=raw}, range phys 0..252
          signal ResumeRangingSessionFBD_HR_STSIndex: start 16, 32 bit, little-endian, data-type-policy=OVERRIDE, base-type=uint32, compu {phys=raw}, range phys 0..4294967292
          signal ResumeRangingSessionFBD_HR_RANMultiplier: start 48, 8 bit, little-endian, data-type-policy=OVERRIDE, base-type=uint8, compu {phys=raw}, range phys 0..252
          signal ResumeRangingSessionFBD_HR_UWBTime0: start 56, 64 bit, little-endian, data-type-policy=OVERRIDE, base-type=uint64, compu {phys=raw}, range phys 0..18446744073709551612
          signal ResumeRangingSessionFBD_HR_ToFStatus: start 120, 8 bit, little-endian, data-type-policy=OVERRIDE, base-type=uint8, compu {phys=raw}, range phys 0..252
          signal ResumeRangingSessionFBD_HR_RangingRoundIndex: start 128, 16 bit, little-endian, data-type-policy=OVERRIDE, base-type=uint16, compu {phys=raw}, range phys 0..65532
          signal ResumeRangingSessionFBD_HR_RangingBlockIndex: start 144, 16 bit, little-endian, data-type-policy=OVERRIDE, base-type=uint16, compu {phys=raw}, range phys 0..65532
      frame ResumeRangingSessionFBD_Miko: id 0x1E2, frame-length=20, can-addressing-mode=STANDARD, can-frame-rx-behavior=CAN-FD, can-frame-tx-behavior=CAN-FD
        pdu ResumeRangingSessionFBD_Miko: length=20, unused-bit-pattern=0
          signal ResumeRangingSessionFBD_Miko_Function: start 0, 8 bit, little-endian, data-type-policy=OVERRIDE, base-type=uint8, compu {phys=raw}, range phys 0..252
          signal ResumeRangingSessionFBD_Miko_SessionIDShort: start 8, 8 bit, little-endian, data-type-policy=OVERRIDE, base-type=uint8, compu {phys=raw}, range phys 0..252
          signal ResumeRangingSessionFBD_Miko_STSIndex: start 16, 32 bit, little-endian, data-type-policy=OVERRIDE, base-type=uint32, compu {phys=raw}, range phys 0..4294967292
          signal ResumeRangingSessionFBD_Miko_RANMultiplier: start 48, 8 bit, little-endian, data-type-policy=OVERRIDE, base-type=uint8, compu {phys=raw}, range phys 0..252
          signal ResumeRangingSessionFBD_Miko_UWBTime0: start 56, 64 bit, little-endian, data-type-policy=OVERRIDE, base-type=uint64, compu {phys=raw}, range phys 0..18446744073709551612
          signal ResumeRangingSessionFBD_Miko_ToFStatus: start 120, 8 bit, little-endian, data-type-policy=OVERRIDE, base-type=uint8, compu {phys=raw}, range phys 0..252
          signal ResumeRangingSessionFBD_Miko_RangingRoundIndex: start 128, 16 bit, little-endian, data-type-policy=OVERRIDE, base-type=uint16, compu {phys=raw}, range phys 0..65532
          signal ResumeRangingSessionFBD_Miko_RangingBlockIndex: start 144, 16 bit, little-endian, data-type-policy=OVERRIDE, base-type=uint16, compu {phys=raw}, range phys 0..65532
      frame ResumeRangingSessionFBD_MM: id 0x1BA, frame-length=20, can-addressing-mode=STANDARD, can-frame-rx-behavior=CAN-FD, can-frame-tx-behavior=CAN-FD
        pdu ResumeRangingSessionFBD_MM: length=20, unused-bit-pattern=0
          signal ResumeRangingSessionFBD_MM_Function: start 0, 8 bit, little-endian, data-type-policy=OVERRIDE, base-type=uint8, compu {phys=raw}, range phys 0..252
          signal ResumeRangingSessionFBD_MM_SessionIDShort: start 8, 8 bit, little-endian, data-type-policy=OVERRIDE, base-type=uint8, compu {phys=raw}, range phys 0..252
          signal ResumeRangingSessionFBD_MM_STSIndex: start 16, 32 bit, little-endian, data-type-policy=OVERRIDE, base-type=uint32, compu {phys=raw}, range phys 0..4294967292
          signal ResumeRangingSessionFBD_MM_RANMultiplier: start 48, 8 bit, little-endian, data-type-policy=OVERRIDE, base-type=uint8, compu {phys=raw}, range phys 0..252
          signal ResumeRangingSessionFBD_MM_UWBTime0: start 56, 64 bit, little-endian, data-type-policy=OVERRIDE, base-type=uint64, compu {phys=raw}, range phys 0..18446744073709551612
          signal ResumeRangingSessionFBD_MM_ToFStatus: start 120, 8 bit, little-endian, data-type-policy=OVERRIDE, base-type=uint8, compu {phys=raw}, range phys 0..252
          signal ResumeRangingSessionFBD_MM_RangingRoundIndex: start 128, 16 bit, little-endian, data-type-policy=OVERRIDE, base-type=uint16, compu {phys=raw}, range phys 0..65532
          signal ResumeRangingSessionFBD_MM_RangingBlockIndex: start 144, 16 bit, little-endian, data-type-policy=OVERRIDE, base-type=uint16, compu {phys=raw}, range phys 0..65532
      frame ResumeRangingSessionFBD_SML: id 0x1E8, frame-length=20, can-addressing-mode=STANDARD, can-frame-rx-behavior=CAN-FD, can-frame-tx-behavior=CAN-FD
        pdu ResumeRangingSessionFBD_SML: length=20, unused-bit-pattern=0
          signal ResumeRangingSessionFBD_SML_Function: start 0, 8 bit, little-endian, data-type-policy=OVERRIDE, base-type=uint8, compu {phys=raw}, range phys 0..252
          signal ResumeRangingSessionFBD_SML_SessionIDShort: start 8, 8 bit, little-endian, data-type-policy=OVERRIDE, base-type=uint8, compu {phys=raw}, range phys 0..252
          signal ResumeRangingSessionFBD_SML_STSIndex: start 16, 32 bit, little-endian, data-type-policy=OVERRIDE, base-type=uint32, compu {phys=raw}, range phys 0..4294967292
          signal ResumeRangingSessionFBD_SML_RANMultiplier: start 48, 8 bit, little-endian, data-type-policy=OVERRIDE, base-type=uint8, compu {phys=raw}, range phys 0..252
          signal ResumeRangingSessionFBD_SML_UWBTime0: start 56, 64 bit, little-endian, data-type-policy=OVERRIDE, base-type=uint64, compu {phys=raw}, range phys 0..18446744073709551612
          signal ResumeRangingSessionFBD_SML_ToFStatus: start 120, 8 bit, little-endian, data-type-policy=OVERRIDE, base-type=uint8, compu {phys=raw}, range phys 0..252
          signal ResumeRangingSessionFBD_SML_RangingRoundIndex: start 128, 16 bit, little-endian, data-type-policy=OVERRIDE, base-type=uint16, compu {phys=raw}, range phys 0..65532
          signal ResumeRangingSessionFBD_SML_RangingBlockIndex: start 144, 16 bit, little-endian, data-type-policy=OVERRIDE, base-type=uint16, compu {phys=raw}, range phys 0..65532
      frame ResumeRangingSessionFBD_SMR: id 0x1E9, frame-length=20, can-addressing-mode=STANDARD, can-frame-rx-behavior=CAN-FD, can-frame-tx-behavior=CAN-FD
        pdu ResumeRangingSessionFBD_SMR: length=20, unused-bit-pattern=0
          signal ResumeRangingSessionFBD_SMR_Function: start 0, 8 bit, little-endian, data-type-policy=OVERRIDE, base-type=uint8, compu {phys=raw}, range phys 0..252
          signal ResumeRangingSessionFBD_SMR_SessionIDShort: start 8, 8 bit, little-endian, data-type-policy=OVERRIDE, base-type=uint8, compu {phys=raw}, range phys 0..252
          signal ResumeRangingSessionFBD_SMR_STSIndex: start 16, 32 bit, little-endian, data-type-policy=OVERRIDE, base-type=uint32, compu {phys=raw}, range phys 0..4294967292
          signal ResumeRangingSessionFBD_SMR_RANMultiplier: start 48, 8 bit, little-endian, data-type-policy=OVERRIDE, base-type=uint8, compu {phys=raw}, range phys 0..252
          signal ResumeRangingSessionFBD_SMR_UWBTime0: start 56, 64 bit, little-endian, data-type-policy=OVERRIDE, base-type=uint64, compu {phys=raw}, range phys 0..18446744073709551612
          signal ResumeRangingSessionFBD_SMR_ToFStatus: start 120, 8 bit, little-endian, data-type-policy=OVERRIDE, base-type=uint8, compu {phys=raw}, range phys 0..252
          signal ResumeRangingSessionFBD_SMR_RangingRoundIndex: start 128, 16 bit, little-endian, data-type-policy=OVERRIDE, base-type=uint16, compu {phys=raw}, range phys 0..65532
          signal ResumeRangingSessionFBD_SMR_RangingBlockIndex: start 144, 16 bit, little-endian, data-type-policy=OVERRIDE, base-type=uint16, compu {phys=raw}, range phys 0..65532
      frame ResumeRangingSessionFBD_Trunk: id 0x1E3, frame-length=20, can-addressing-mode=STANDARD, can-frame-rx-behavior=CAN-FD, can-frame-tx-behavior=CAN-FD
        pdu ResumeRangingSessionFBD_Trunk: length=20, unused-bit-pattern=0
          signal ResumeRangingSessionFBD_Trunk_Function: start 0, 8 bit, little-endian, data-type-policy=OVERRIDE, base-type=uint8, compu {phys=raw}, range phys 0..252
          signal ResumeRangingSessionFBD_Trunk_SessionIDShort: start 8, 8 bit, little-endian, data-type-policy=OVERRIDE, base-type=uint8, compu {phys=raw}, range phys 0..252
          signal ResumeRangingSessionFBD_Trunk_STSIndex: start 16, 32 bit, little-endian, data-type-policy=OVERRIDE, base-type=uint32, compu {phys=raw}, range phys 0..4294967292
          signal ResumeRangingSessionFBD_Trunk_RANMultiplier: start 48, 8 bit, little-endian, data-type-policy=OVERRIDE, base-type=uint8, compu {phys=raw}, range phys 0..252
          signal ResumeRangingSessionFBD_Trunk_UWBTime0: start 56, 64 bit, little-endian, data-type-policy=OVERRIDE, base-type=uint64, compu {phys=raw}, range phys 0..18446744073709551612
          signal ResumeRangingSessionFBD_Trunk_ToFStatus: start 120, 8 bit, little-endian, data-type-policy=OVERRIDE, base-type=uint8, compu {phys=raw}, range phys 0..252
          signal ResumeRangingSessionFBD_Trunk_RangingRoundIndex: start 128, 16 bit, little-endian, data-type-policy=OVERRIDE, base-type=uint16, compu {phys=raw}, range phys 0..65532
          signal ResumeRangingSessionFBD_Trunk_RangingBlockIndex: start 144, 16 bit, little-endian, data-type-policy=OVERRIDE, base-type=uint16, compu {phys=raw}, range phys 0..65532
      frame ResumeRangingSessionFBD_VL: id 0x1E4, frame-length=20, can-addressing-mode=STANDARD, can-frame-rx-behavior=CAN-FD, can-frame-tx-behavior=CAN-FD
        pdu ResumeRangingSessionFBD_VL: length=20, unused-bit-pattern=0
          signal ResumeRangingSessionFBD_VL_Function: start 0, 8 bit, little-endian, data-type-policy=OVERRIDE, base-type=uint8, compu {phys=raw}, range phys 0..252
          signal ResumeRangingSessionFBD_VL_SessionIDShort: start 8, 8 bit, little-endian, data-type-policy=OVERRIDE, base-type=uint8, compu {phys=raw}, range phys 0..252
          signal ResumeRangingSessionFBD_VL_STSIndex: start 16, 32 bit, little-endian, data-type-policy=OVERRIDE, base-type=uint32, compu {phys=raw}, range phys 0..4294967292
          signal ResumeRangingSessionFBD_VL_RANMultiplier: start 48, 8 bit, little-endian, data-type-policy=OVERRIDE, base-type=uint8, compu {phys=raw}, range phys 0..252
          signal ResumeRangingSessionFBD_VL_UWBTime0: start 56, 64 bit, little-endian, data-type-policy=OVERRIDE, base-type=uint64, compu {phys=raw}, range phys 0..18446744073709551612
          signal ResumeRangingSessionFBD_VL_ToFStatus: start 120, 8 bit, little-endian, data-type-policy=OVERRIDE, base-type=uint8, compu {phys=raw}, range phys 0..252
          signal ResumeRangingSessionFBD_VL_RangingRoundIndex: start 128, 16 bit, little-endian, data-type-policy=OVERRIDE, base-type=uint16, compu {phys=raw}, range phys 0..65532
          signal ResumeRangingSessionFBD_VL_RangingBlockIndex: start 144, 16 bit, little-endian, data-type-policy=OVERRIDE, base-type=uint16, compu {phys=raw}, range phys 0..65532
      frame ResumeRangingSessionFBD_VM: id 0x1E0, frame-length=20, can-addressing-mode=STANDARD, can-frame-rx-behavior=CAN-FD, can-frame-tx-behavior=CAN-FD
        pdu ResumeRangingSessionFBD_VM: length=20, unused-bit-pattern=0
          signal ResumeRangingSessionFBD_VM_Function: start 0, 8 bit, little-endian, data-type-policy=OVERRIDE, base-type=uint8, compu {phys=raw}, range phys 0..252
          signal ResumeRangingSessionFBD_VM_SessionIDShort: start 8, 8 bit, little-endian, data-type-policy=OVERRIDE, base-type=uint8, compu {phys=raw}, range phys 0..252
          signal ResumeRangingSessionFBD_VM_STSIndex: start 16, 32 bit, little-endian, data-type-policy=OVERRIDE, base-type=uint32, compu {phys=raw}, range phys 0..4294967292
          signal ResumeRangingSessionFBD_VM_RANMultiplier: start 48, 8 bit, little-endian, data-type-policy=OVERRIDE, base-type=uint8, compu {phys=raw}, range phys 0..252
          signal ResumeRangingSessionFBD_VM_UWBTime0: start 56, 64 bit, little-endian, data-type-policy=OVERRIDE, base-type=uint64, compu {phys=raw}, range phys 0..18446744073709551612
          signal ResumeRangingSessionFBD_VM_ToFStatus: start 120, 8 bit, little-endian, data-type-policy=OVERRIDE, base-type=uint8, compu {phys=raw}, range phys 0..252
          signal ResumeRangingSessionFBD_VM_RangingRoundIndex: start 128, 16 bit, little-endian, data-type-policy=OVERRIDE, base-type=uint16, compu {phys=raw}, range phys 0..65532
          signal ResumeRangingSessionFBD_VM_RangingBlockIndex: start 144, 16 bit, little-endian, data-type-policy=OVERRIDE, base-type=uint16, compu {phys=raw}, range phys 0..65532
      frame ResumeRangingSessionFBD_VR: id 0x1E5, frame-length=20, can-addressing-mode=STANDARD, can-frame-rx-behavior=CAN-FD, can-frame-tx-behavior=CAN-FD
        pdu ResumeRangingSessionFBD_VR: length=20, unused-bit-pattern=0
          signal ResumeRangingSessionFBD_VR_Function: start 0, 8 bit, little-endian, data-type-policy=OVERRIDE, base-type=uint8, compu {phys=raw}, range phys 0..252
          signal ResumeRangingSessionFBD_VR_SessionIDShort: start 8, 8 bit, little-endian, data-type-policy=OVERRIDE, base-type=uint8, compu {phys=raw}, range phys 0..252
          signal ResumeRangingSessionFBD_VR_STSIndex: start 16, 32 bit, little-endian, data-type-policy=OVERRIDE, base-type=uint32, compu {phys=raw}, range phys 0..4294967292
          signal ResumeRangingSessionFBD_VR_RANMultiplier: start 48, 8 bit, little-endian, data-type-policy=OVERRIDE, base-type=uint8, compu {phys=raw}, range phys 0..252
          signal ResumeRangingSessionFBD_VR_UWBTime0: start 56, 64 bit, little-endian, data-type-policy=OVERRIDE, base-type=uint64, compu {phys=raw}, range phys 0..18446744073709551612
          signal ResumeRangingSessionFBD_VR_ToFStatus: start 120, 8 bit, little-endian, data-type-policy=OVERRIDE, base-type=uint8, compu {phys=raw}, range phys 0..252
          signal ResumeRangingSessionFBD_VR_RangingRoundIndex: start 128, 16 bit, little-endian, data-type-policy=OVERRIDE, base-type=uint16, compu {phys=raw}, range phys 0..65532
          signal ResumeRangingSessionFBD_VR_RangingBlockIndex: start 144, 16 bit, little-endian, data-type-policy=OVERRIDE, base-type=uint16, compu {phys=raw}, range phys 0..65532
      frame SeamlessBLEStatusFBD_HL: id 0x114, frame-length=20, can-addressing-mode=STANDARD, can-frame-rx-behavior=CAN-FD, can-frame-tx-behavior=CAN-FD
        pdu SeamlessBLEStatusFBD_HL: length=20, unused-bit-pattern=0
          signal SeamlessBLEStatusFBD_HL_NumberActiveConnections: start 0, 8 bit, little-endian, data-type-policy=OVERRIDE, base-type=uint8, compu {phys=raw}, range phys 0..252
          signal SeamlessBLEStatusFBD_HL_ConnectionID1: start 8, 8 bit, little-endian, data-type-policy=OVERRIDE, base-type=uint8, compu {phys=raw}, range phys 0..252
          signal SeamlessBLEStatusFBD_HL_ConnectionRSSI1: start 16, 8 bit, little-endian, data-type-policy=OVERRIDE, base-type=uint8, compu {phys=raw*0.5-127; unit dB}, range phys -127..-1
          signal SeamlessBLEStatusFBD_HL_ConnectionID2: start 24, 8 bit, little-endian, data-type-policy=OVERRIDE, base-type=uint8, compu {phys=raw}, range phys 0..252
          signal SeamlessBLEStatusFBD_HL_ConnectionRSSI2: start 32, 8 bit, little-endian, data-type-policy=OVERRIDE, base-type=uint8, compu {phys=raw*0.5-127; unit dB}, range phys -127..-1
          signal SeamlessBLEStatusFBD_HL_ConnectionID3: start 40, 8 bit, little-endian, data-type-policy=OVERRIDE, base-type=uint8, compu {phys=raw}, range phys 0..252
          signal SeamlessBLEStatusFBD_HL_ConnectionRSSI3: start 48, 8 bit, little-endian, data-type-policy=OVERRIDE, base-type=uint8, compu {phys=raw*0.5-127; unit dB}, range phys -127..-1
          signal SeamlessBLEStatusFBD_HL_ConnectionID4: start 56, 8 bit, little-endian, data-type-policy=OVERRIDE, base-type=uint8, compu {phys=raw}, range phys 0..252
          signal SeamlessBLEStatusFBD_HL_ConnectionRSSI4: start 64, 8 bit, little-endian, data-type-policy=OVERRIDE, base-type=uint8, compu {phys=raw*0.5-127; unit dB}, range phys -127..-1
          signal SeamlessBLEStatusFBD_HL_ConnectionID5: start 72, 8 bit, little-endian, data-type-policy=OVERRIDE, base-type=uint8, compu {phys=raw}, range phys 0..252
          signal SeamlessBLEStatusFBD_HL_ConnectionRSSI5: start 80, 8 bit, little-endian, data-type-policy=OVERRIDE, base-type=uint8, compu {phys=raw*0.5-127; unit dB}, range phys -127..-1
          signal SeamlessBLEStatusFBD_HL_ConnectionID6: start 88, 8 bit, little-endian, data-type-policy=OVERRIDE, base-type=uint8, compu {phys=raw}, range phys 0..252
          signal SeamlessBLEStatusFBD_HL_ConnectionRSSI6: start 96, 8 bit, little-endian, data-type-policy=OVERRIDE, base-type=uint8, compu {phys=raw*0.5-127; unit dB}, range phys -127..-1
          signal SeamlessBLEStatusFBD_HL_ConnectionID7: start 104, 8 bit, little-endian, data-type-policy=OVERRIDE, base-type=uint8, compu {phys=raw}, range phys 0..252
          signal SeamlessBLEStatusFBD_HL_ConnectionRSSI7: start 112, 8 bit, little-endian, data-type-policy=OVERRIDE, base-type=uint8, compu {phys=raw*0.5-127; unit dB}, range phys -127..-1
          signal SeamlessBLEStatusFBD_HL_ConnectionID8: start 120, 8 bit, little-endian, data-type-policy=OVERRIDE, base-type=uint8, compu {phys=raw}, range phys 0..252
          signal SeamlessBLEStatusFBD_HL_ConnectionRSSI8: start 128, 8 bit, little-endian, data-type-policy=OVERRIDE, base-type=uint8, compu {phys=raw*0.5-127; unit dB}, range phys -127..-1
